VERSION ""

NS_ :

BS_:

BU_: BPCM ECM EVCU2 IDCM MCPA MCPB SGCP

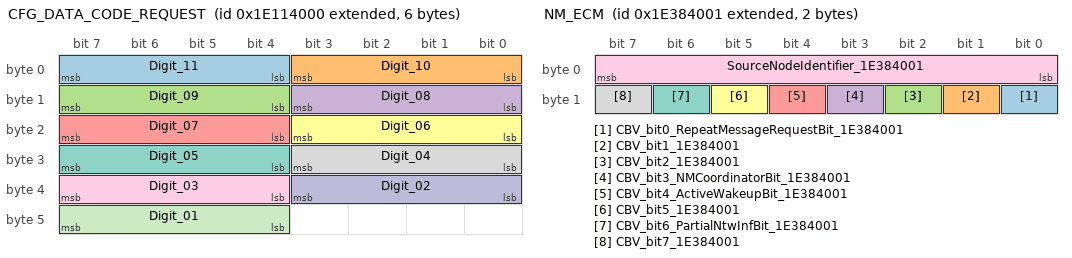
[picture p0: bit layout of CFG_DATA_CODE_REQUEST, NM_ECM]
BO_ 2651930624 CFG_DATA_CODE_REQUEST: 6 EVCU2
 SG_ Digit_11 : 7|4@0+ (1,0) [0|15] "" MCPB,MCPA
 SG_ Digit_10 : 3|4@0+ (1,0) [0|15] "" MCPB,MCPA
 SG_ Digit_09 : 15|4@0+ (1,0) [0|15] "" MCPB,MCPA
 SG_ Digit_08 : 11|4@0+ (1,0) [0|15] "" MCPB,MCPA
 SG_ Digit_07 : 23|4@0+ (1,0) [0|15] "" MCPB,MCPA
 SG_ Digit_06 : 19|4@0+ (1,0) [0|15] "" MCPB,MCPA
 SG_ Digit_05 : 31|4@0+ (1,0) [0|15] "" MCPB,MCPA
 SG_ Digit_04 : 27|4@0+ (1,0) [0|15] "" MCPB,MCPA
 SG_ Digit_03 : 39|4@0+ (1,0) [0|15] "" MCPB,MCPA
 SG_ Digit_02 : 35|4@0+ (1,0) [0|15] "" MCPB,MCPA
 SG_ Digit_01 : 47|4@0+ (1,0) [0|15] "" MCPB,MCPA

BO_ 2564554481 DIAGNOSTIC_REQUEST_FUNCTIONAL: 8 EVCU2
 SG_ N_PDU_18DBFEF1 : 7|64@0+ (1,0) [0|0] "" SGCP,MCPB,MCPA

BO_ 2564502513 DIAGNOSTIC_REQUEST_FUNC_OBD: 8 EVCU2
 SG_ N_PDU_18DB33F1 : 7|64@0+ (1,0) [0|0] "" MCPB,MCPA

BO_ 1053 VIN: 32 EVCU2
 SG_ VIN_MSG : 75|2@0+ (1,0) [0|3] "" SGCP,MCPB,MCPA,IDCM,BPCM
 SG_ VIN_DATA : 87|56@0+ (1,0) [0|72057594037927900] "" SGCP,MCPB,MCPA,IDCM,BPCM

BO_ 520 TRANSM_FD_2: 32 EVCU2
 SG_ GearEngagedForDisplay : 15|5@0+ (1,0) [0|30] "-"  SGCP,MCPB,MCPA

BO_ 156 TELEMATIC_FD_1: 32 EVCU2
 SG_ GPS_UTC_Second : 151|16@0+ (0.01,0) [0|59.99] "s"  MCPB,MCPA,IDCM,BPCM
 SG_ GPS_UTC_Minute : 47|8@0+ (1,0) [0|59] "min"  MCPB,MCPA,IDCM,BPCM
 SG_ GPS_UTC_Hour : 55|8@0+ (1,0) [0|23] "h"  MCPB,MCPA,IDCM,BPCM
 SG_ GPS_Date_Year : 167|16@0+ (1,0) [0|65534] "Years"  MCPB,MCPA,IDCM,BPCM
 SG_ GPS_Date_Month : 71|8@0+ (1,0) [1|12] "Months"  MCPB,MCPA,IDCM,BPCM
 SG_ GPS_Date_Day : 63|8@0+ (1,0) [1|31] "Days"  MCPB,MCPA,IDCM,BPCM

BO_ 1058 OBD_CONTENT_FRAME: 32 ECM
 SG_ MessageCounter_OBDCONTENTFRAME : 179|4@0+ (1,0) [0|15] "-"  EVCU2
 SG_ CRC_OBDCONTENTFRAME : 191|8@0+ (1,0) [0|255] "-"  EVCU2

BO_ 1829 IPC_FD_1: 32 EVCU2
 SG_ TotalOdometer : 75|20@0+ (1,0) [0|1048575] "km"  SGCP,MCPB,MCPA,IDCM,BPCM

BO_ 1626 IMPACT_INFO: 32 EVCU2
 SG_ IMPACTConfirm : 81|1@0+ (1,0) [0|1] "-"  MCPB,MCPA,IDCM,BPCM
 SG_ IMPACTCommand : 80|1@0+ (1,0) [0|1] "-"  MCPB,MCPA,IDCM,BPCM

BO_ 518 ENGINE_FD_5: 32 ECM
 SG_ RPMOverRev_W : 115|1@0+ (1,0) [0|1] "-"  EVCU2
 SG_ MessageCounter_ENGINE5 : 179|4@0+ (1,0) [0|15] "-"  EVCU2
 SG_ CRC_ENGINE5 : 191|8@0+ (1,0) [0|255] "-"  EVCU2

BO_ 1054 ENGINE_FD_1: 32 ECM
 SG_ ThermalManagementActive_W : 1|1@0+ (1,0) [0|1] "-"  EVCU2
 SG_ MessageCounter_ENGINE1 : 179|4@0+ (1,0) [0|15] "-"  EVCU2
 SG_ CRC_ENGINE1 : 191|8@0+ (1,0) [0|255] "-"  EVCU2

BO_ 2564554482 DIAGNOSTIC_REQUEST_FD_FUNCTIONAL: 64 EVCU2
 SG_ N_PDU_18DBFEF2 : 7|64@0+ (1,0) [0|0] "" SGCP,MCPB,MCPA

BO_ 1155 BRAKE_FD_5: 32 EVCU2
 SG_ ESCFailSts : 83|1@0+ (1,0) [0|1] "-"  MCPB
 SG_ ABSFailSts : 87|1@0+ (1,0) [0|1] "-"  MCPB

BO_ 609 BRAKE_FD_4: 32 EVCU2
 SG_ EPBSts : 115|4@0+ (1,0) [0|14] "-"  SGCP,MCPB,MCPA

BO_ 1066 BCM_FD_9: 32 EVCU2
 SG_ ExternalTemperature : 0|9@0+ (0.5,-85) [-85|170] "°C"  SGCP,MCPB,MCPA,IDCM,BPCM

BO_ 1827 BCM_FD_7: 32 EVCU2
 SG_ IgnitionOnCounter : 95|16@0+ (1,0) [0|65535] "-"  SGCP,MCPB,MCPA

BO_ 256 BCM_FD_2: 32 EVCU2
 SG_ OperationalModeSts : 75|4@0+ (1,0) [0|15] "" MCPB,MCPA,IDCM,BPCM

BO_ 1153 BCM_FD_10: 32 EVCU2
 SG_ ExternalTemperatureC : 80|9@0+ (0.5,-85) [-85|170] "°C"  SGCP,MCPB,MCPA
 SG_ CmdIgnSts : 138|3@0+ (1,0) [0|7] "" SGCP,MCPB,MCPA,IDCM,BPCM
 SG_ MessageCounter_BCM10 : 179|4@0+ (1,0) [0|15] "-"  MCPB
 SG_ CRC_BCM10 : 191|8@0+ (1,0) [0|255] "-"  MCPB

BO_ 753 LV_CHARGER1: 32 IDCM
 SG_ IDCM_Wakeup_HCP : 23|1@0+ (1,0) [0|1] "-"  EVCU2

BO_ 1032 HYBRID_THERMAL_COMMAND: 32 EVCU2
 SG_ MessageCounter_HYBRID_THERMAL_C : 179|4@0+ (1,0) [0|15] "-"  SGCP,MCPB,MCPA,ECM
 SG_ CRC_HYBRID_THERMAL_COMMAND : 191|8@0+ (1,0) [0|255] "-"  SGCP,MCPB,MCPA,ECM
 SG_ SGCP_OIL_TEMP : 175|8@0+ (1,-50) [-50|205] "°C"  SGCP
 SG_ SGCP_OIL_FlwRate : 135|8@0+ (0.1,0) [0|25.4] "LPM"  SGCP
 SG_ EOPB_OIL_TEMP : 151|8@0+ (1,-50) [-50|205] "°C"  MCPB
 SG_ EOPB_OIL_FlwRate : 167|8@0+ (0.1,0) [0|25.4] "LPM"  MCPB
 SG_ EOPA_OIL_TEMP : 143|8@0+ (1,-50) [-50|205] "°C"  MCPA
 SG_ EOPA_OIL_FlwRate : 159|8@0+ (0.1,0) [0|25.4] "LPM"  MCPA

BO_ 267 HYBRID_SYSTEM_EPT1: 32 EVCU2
 SG_ WU_Timer_Value : 23|16@0+ (1,0) [0|65535] "min"  MCPB,MCPA,IDCM,BPCM
 SG_ PerWakeUp_Diag : 33|10@0+ (1,0) [0|1023] "-"  MCPB,MCPA,IDCM,BPCM

BO_ 1033 HYBRID_POWERTRAIN5: 32 EVCU2
 SG_ IdleCLoopTrq : 33|10@0+ (0.32,-163.52) [-163.52|163.52] "Nm"  ECM
 SG_ HEV_HybPwrtrnRdcdPerfCmnd : 22|1@0+ (1,0) [0|0] "-"  ECM
 SG_ HCPMaxEngRPM : 63|8@0+ (32,0) [0|8128] "rpm"  ECM
 SG_ CRC_HYBRID_POWERTRAIN5 : 191|8@0+ (1,0) [0|255] "-"  ECM
 SG_ MessageCounter_HYBRID_POWERTRAI_409 : 179|4@0+ (1,0) [0|15] "-"  ECM
 SG_ HCP_HoodAjar : 35|2@0+ (1,0) [0|2] "" ECM

BO_ 1034 HVBATTERY_THERMAL: 48 BPCM
 SG_ HVBatSleepTime : 7|8@0+ (0.2,0) [0|48] "Days"  EVCU2

BO_ 1328 ENGINE_HYBD_FD_4: 32 ECM
 SG_ EngTorqCapbltyMinTorq : 51|12@0+ (0.32,-300.16) [-300.16|1008] "Nm"  EVCU2
 SG_ EngTorqCapbltyMaxTorq : 19|12@0+ (0.32,-300.16) [-300.16|1008] "Nm"  EVCU2
 SG_ EngTorqCapbltyMaxOffTorq : 3|12@0+ (0.32,-300.16) [-300.16|1008] "Nm"  EVCU2
 SG_ EngTorqCapbltyRefEngSpd : 71|8@0+ (32,0) [0|8160] "rpm"  EVCU2
 SG_ EngTorqCapbltyMinRunTorq : 35|12@0+ (0.32,-300.16) [-300.16|1008] "Nm"  EVCU2
 SG_ EngTorqCapbltyFrmCntr : 7|4@0+ (1,0) [0|15] "-"  EVCU2
 SG_ EngTorqCapbltyEngOpMd : 21|1@0+ (1,0) [0|0] "-"  EVCU2
 SG_ EngTorqACCCapability : 79|8@0+ (0.32,0) [0|81.28] "Nm"  EVCU2
 SG_ MessageCounter_ENGINE_HYBD_FD_4 : 179|4@0+ (1,0) [0|15] "-"  EVCU2
 SG_ CRC_ENGINE_HYBD_FD_4 : 191|8@0+ (1,0) [0|255] "-"  EVCU2

BO_ 1035 ENGINE_HYBD_FD_3: 32 ECM
 SG_ MaxEngSpdCap : 52|13@0+ (1,0) [0|8160] "rpm"  EVCU2
 SG_ MinEngSpdCap : 68|13@0+ (1,0) [0|8160] "rpm"  EVCU2
 SG_ EngSpd : 7|16@0+ (0.125,0) [0|8160] "rpm"  EVCU2
 SG_ MessageCounter_ENGINE_HYBD_FD_3 : 179|4@0+ (1,0) [0|15] "-"  EVCU2
 SG_ CRC_ENGINE_HYBD_FD_3 : 191|8@0+ (1,0) [0|255] "-"  EVCU2

BO_ 750 BCM_FD_3: 32 EVCU2
 SG_ Battery_Volt_1 : 56|9@0+ (0.025,5) [5|17.75] "Volt"  SGCP,MCPB,MCPA

BO_ 2654486529 NM_ECM: 2 ECM
 SG_ CBV_bit0_RepeatMessageRequestBit_1E384001 : 8|1@0+ (1,0) [0|1] "" SGCP,EVCU2,MCPB,MCPA,IDCM,BPCM
 SG_ CBV_bit1_1E384001 : 9|1@0+ (1,0) [0|1] "" SGCP,EVCU2,MCPB,MCPA,IDCM,BPCM
 SG_ CBV_bit2_1E384001 : 10|1@0+ (1,0) [0|1] "" SGCP,EVCU2,MCPB,MCPA,IDCM,BPCM
 SG_ CBV_bit3_NMCoordinatorBit_1E384001 : 11|1@0+ (1,0) [0|1] "" SGCP,EVCU2,MCPB,MCPA,IDCM,BPCM
 SG_ CBV_bit4_ActiveWakeupBit_1E384001 : 12|1@0+ (1,0) [0|1] "" SGCP,EVCU2,MCPB,MCPA,IDCM,BPCM
 SG_ CBV_bit5_1E384001 : 13|1@0+ (1,0) [0|1] "" SGCP,EVCU2,MCPB,MCPA,IDCM,BPCM
 SG_ CBV_bit6_PartialNtwInfBit_1E384001 : 14|1@0+ (1,0) [0|1] "" SGCP,EVCU2,MCPB,MCPA,IDCM,BPCM
 SG_ CBV_bit7_1E384001 : 15|1@0+ (1,0) [0|1] "" SGCP,EVCU2,MCPB,MCPA,IDCM,BPCM
 SG_ SourceNodeIdentifier_1E384001 : 7|8@0+ (1,0) [0|255] "-"  SGCP,EVCU2,MCPB,MCPA,IDCM,BPCM

BO_ 269 HYBRID_POWERTRAIN2: 64 EVCU2
 SG_ CRC_HYBRID_POWERTRAIN2 : 447|8@0+ (1,0) [0|255] "-"  ECM
 SG_ MessageCounter_HYBRID_POWERTRAI_10D : 435|4@0+ (1,0) [0|15] "-"  ECM

BO_ 276 HYBRID_POWERTRAIN1: 64 EVCU2
 SG_ Hybrid_Remedial_Stop : 290|1@0+ (1,0) [0|0] "-"  ECM
 SG_ HybCrnkAbrted : 282|1@0+ (1,0) [0|0] "-"  ECM
 SG_ CRC_HYBRID_POWERTRAIN1 : 447|8@0+ (1,0) [0|255] "-"  ECM
 SG_ PropulsionSystemActive : 408|1@0+ (1,0) [0|1] "-"  BPCM,ECM
 SG_ DriveReady : 423|1@0+ (1,0) [0|1] "-"  Vector__XXX
 SG_ MessageCounter_HYBRID_POWERTRAI_114 : 435|4@0+ (1,0) [0|15] "-"  ECM

BO_ 271 ENGINE_HYBD_FD_1: 64 ECM
 SG_ MessageCounter_ENGINE_HYBD_FD_1 : 435|4@0+ (1,0) [0|15] "-"  EVCU2
 SG_ CRC_ENGINE_HYBD_FD_1 : 447|8@0+ (1,0) [0|255] "-"  EVCU2
 SG_ RedSpkAuthorityAvbl : 308|1@0+ (1,0) [0|1] "" EVCU2
 SG_ EngMinSparkNomCurrAirTorqCap : 82|11@0+ (1,-500) [-500|1547] "Nm"  EVCU2

BO_ 262 ENGINE_FD_2: 64 ECM
 SG_ PowertrainPrplsnActv : 181|1@0+ (1,0) [0|1] "" SGCP,MCPB,MCPA
 SG_ MessageCounter_ENGINE2 : 435|4@0+ (1,0) [0|15] "-"  EVCU2
 SG_ EngineSpeedFailSts_W : 168|1@0+ (1,0) [0|1] "-"  SGCP,MCPB,MCPA
 SG_ EngineSpeed_W : 21|14@0+ (1,0) [0|16382] "1/min"  SGCP,MCPB,MCPA
 SG_ CRC_ENGINE2 : 447|8@0+ (1,0) [0|255] "-"  EVCU2

BO_ 258 BRAKE_FD_2: 64 EVCU2
 SG_ VehicleSpeedVSOSig : 4|13@0+ (0.0625,0) [0|511.875] "Km/h"  SGCP,MCPB,MCPA,BPCM
 SG_ MessageCounter_BRAKE2 : 435|4@0+ (1,0) [0|15] "-"  MCPB,MCPA
 SG_ LongAccelerationFailSts_BSM : 69|1@0+ (1,0) [0|1] "-"  MCPB,MCPA
 SG_ LongAcceleration_BSM : 35|12@0+ (0.02,-40.96) [-40.96|40.92] "m/s^2"  MCPB,MCPA
 SG_ LatAccelerationFailSts_BSM : 68|1@0+ (1,0) [0|1] "-"  MCPB,MCPA
 SG_ LatAcceleration_BSM : 19|12@0+ (0.02,-40.96) [-40.96|40.92] "m/s^2"  MCPB,MCPA
 SG_ ESCActive : 84|1@0+ (1,0) [0|1] "-"  MCPB,MCPA
 SG_ CRC_BRAKE2 : 447|8@0+ (1,0) [0|255] "-"  MCPB,MCPA
 SG_ ABSActive : 83|1@0+ (1,0) [0|1] "-"  MCPB,MCPA

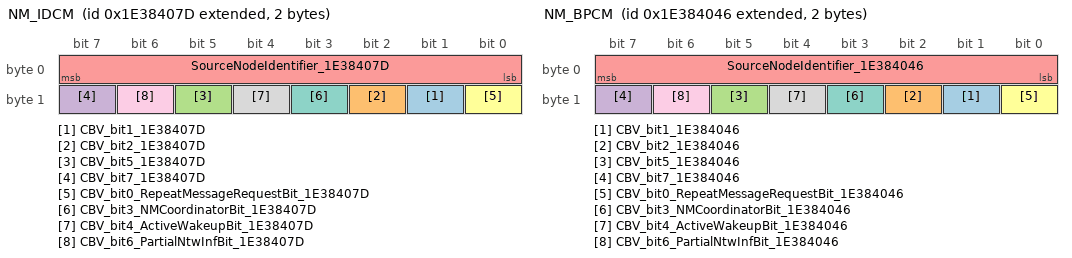
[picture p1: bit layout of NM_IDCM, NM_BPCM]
BO_ 2654486653 NM_IDCM: 2 IDCM
 SG_ CBV_bit1_1E38407D : 9|1@0+ (1,0) [0|1] "" SGCP,EVCU2,MCPB,MCPA,BPCM,ECM
 SG_ CBV_bit2_1E38407D : 10|1@0+ (1,0) [0|1] "" SGCP,EVCU2,MCPB,MCPA,BPCM,ECM
 SG_ CBV_bit5_1E38407D : 13|1@0+ (1,0) [0|1] "" SGCP,EVCU2,MCPB,MCPA,BPCM,ECM
 SG_ CBV_bit7_1E38407D : 15|1@0+ (1,0) [0|1] "" SGCP,EVCU2,MCPB,MCPA,BPCM,ECM
 SG_ SourceNodeIdentifier_1E38407D : 7|8@0+ (1,0) [0|255] "-"  SGCP,EVCU2,MCPB,MCPA,BPCM,ECM
 SG_ CBV_bit0_RepeatMessageRequestBit_1E38407D : 8|1@0+ (1,0) [0|1] "" SGCP,EVCU2,MCPB,MCPA,BPCM,ECM
 SG_ CBV_bit3_NMCoordinatorBit_1E38407D : 11|1@0+ (1,0) [0|1] "" SGCP,EVCU2,MCPB,MCPA,BPCM,ECM
 SG_ CBV_bit4_ActiveWakeupBit_1E38407D : 12|1@0+ (1,0) [0|1] "" SGCP,EVCU2,MCPB,MCPA,BPCM,ECM
 SG_ CBV_bit6_PartialNtwInfBit_1E38407D : 14|1@0+ (1,0) [0|1] "" SGCP,EVCU2,MCPB,MCPA,BPCM,ECM

BO_ 2654486598 NM_BPCM: 2 BPCM
 SG_ CBV_bit1_1E384046 : 9|1@0+ (1,0) [0|1] "" SGCP,EVCU2,MCPB,MCPA,IDCM,ECM
 SG_ CBV_bit2_1E384046 : 10|1@0+ (1,0) [0|1] "" SGCP,EVCU2,MCPB,MCPA,IDCM,ECM
 SG_ CBV_bit5_1E384046 : 13|1@0+ (1,0) [0|1] "" SGCP,EVCU2,MCPB,MCPA,IDCM,ECM
 SG_ CBV_bit7_1E384046 : 15|1@0+ (1,0) [0|1] "" SGCP,EVCU2,MCPB,MCPA,IDCM,ECM
 SG_ SourceNodeIdentifier_1E384046 : 7|8@0+ (1,0) [0|255] "-"  SGCP,EVCU2,MCPB,MCPA,IDCM,ECM
 SG_ CBV_bit0_RepeatMessageRequestBit_1E384046 : 8|1@0+ (1,0) [0|1] "" SGCP,EVCU2,MCPB,MCPA,IDCM,ECM
 SG_ CBV_bit3_NMCoordinatorBit_1E384046 : 11|1@0+ (1,0) [0|1] "" SGCP,EVCU2,MCPB,MCPA,IDCM,ECM
 SG_ CBV_bit4_ActiveWakeupBit_1E384046 : 12|1@0+ (1,0) [0|1] "" SGCP,EVCU2,MCPB,MCPA,IDCM,ECM
 SG_ CBV_bit6_PartialNtwInfBit_1E384046 : 14|1@0+ (1,0) [0|1] "" SGCP,EVCU2,MCPB,MCPA,IDCM,ECM

BO_ 1579 HYBRID_CHARGING_STATUS: 32 EVCU2
 SG_ HVBatteryVoltage_MinCal : 32|9@0+ (1,0) [0|510] "V"  IDCM,BPCM
 SG_ HVBatteryVoltage_MaxCal : 16|9@0+ (1,0) [0|510] "V"  IDCM,BPCM
 SG_ HVBatteryCurrent_MaxCal : 63|8@0+ (0.25,-32) [-32|31.5] "Amp"  IDCM,BPCM
 SG_ ChargeSystemFaultReason : 55|8@0+ (1,0) [0|254] "-"  IDCM
 SG_ ACCurrent_MaxCal : 0|9@0+ (0.25,-31.5) [-31.5|50] "Amp"  IDCM,BPCM
 SG_ ChargingLevel : 4|4@0+ (1,0) [0|14] "-"  IDCM
 SG_ OBCM_PLUG_STS : 23|2@0+ (1,0) [0|3] "" IDCM
 SG_ ChargeSystemSts : 7|3@0+ (1,0) [0|6] "-"  IDCM,BPCM
 SG_ ChargeSystemFault : 17|1@0+ (1,0) [0|1] "-"  IDCM
 SG_ CRC_HYBRID_CHARGING_STATUS : 191|8@0+ (1,0) [0|255] "-"  IDCM
 SG_ MessageCounter_HYBRID_CHARGING__62B : 179|4@0+ (1,0) [0|15] "-"  IDCM

BO_ 478 HYBRID_CHARGING_COMMAND: 32 EVCU2
 SG_ CRC_HYBRID_CHARGING_COMMAND : 191|8@0+ (1,0) [0|255] "-"  IDCM
 SG_ VoltageRequest : 4|13@0+ (0.1,0) [0|819.1] "Volts"  IDCM
 SG_ OBC_ControlMethod : 38|2@0+ (1,0) [0|2] "-"  IDCM
 SG_ J1772_CloseS2 : 51|1@0+ (1,0) [0|1] "-"  IDCM
 SG_ HVBatCoolantLevelLow : 50|2@0+ (1,0) [0|2] "-"  BPCM
 SG_ OBC_OperativeModeReq : 87|4@0+ (1,0) [0|14] "-"  IDCM
 SG_ HV_Volt_Min_Thrsh : 138|11@0+ (1,0) [0|2047] "V"  IDCM
 SG_ HV_Volt_Max_Thrsh : 133|11@0+ (1,0) [0|2047] "V"  IDCM
 SG_ DC_Curr_Max_Thrsh : 127|10@0+ (1,-511) [-511|512] "A"  IDCM
 SG_ ChargeEnable : 171|2@0+ (1,0) [0|2] "-"  IDCM
 SG_ AC_Curr_Min_Thrsh : 165|10@0+ (1,-511) [-511|512] "A"  IDCM
 SG_ AC_Curr_Max_Thrsh : 159|10@0+ (1,-511) [-511|512] "A"  IDCM
 SG_ CurrentRequest : 81|10@0+ (0.1,-32) [-32|70.3] "A"  IDCM
 SG_ VDCM_StsWldgReq : 83|1@0+ (1,0) [0|1] "-"  IDCM
 SG_ VDCM_SessnStopReq : 82|1@0+ (1,0) [0|1] "-"  IDCM
 SG_ VDCM_StsSWWldgReq : 55|2@0+ (1,0) [0|3] "-"  Vector__XXX
 SG_ MessageCounter_HYBRID_CHARGING__1DE : 179|4@0+ (1,0) [0|15] "-"  IDCM

BO_ 1578 HV_CHARGER2: 32 IDCM
 SG_ OBC_IdleTimeSec : 71|16@0+ (3,0) [0|196602] "sec"  EVCU2
 SG_ OBC_IdleTimeMin : 87|16@0+ (1,0) [0|65534] "min"  EVCU2
 SG_ OBC_ChargeTimeSec : 39|16@0+ (3,0) [0|196602] "sec"  EVCU2
 SG_ OBC_ChargeTimeMin : 55|16@0+ (1,0) [0|65534] "min"  EVCU2
 SG_ Charging_WHr : 23|16@0+ (1,0) [0|65534] "WHr"  EVCU2
 SG_ OnboardChargerReady : 116|2@0+ (1,0) [0|2] "-"  EVCU2
 SG_ OnboardChargerMode : 114|4@0+ (1,0) [0|15] "-"  EVCU2
 SG_ OBC_WakeReason : 107|4@0+ (1,0) [0|7] "-"  EVCU2
 SG_ OBC_GenericFailSts : 125|1@0+ (1,0) [0|1] "-"  EVCU2
 SG_ OBC_FaultReason : 102|7@0+ (1,0) [0|126] "-"  EVCU2
 SG_ OBC_EVServiceLampOn : 124|1@0+ (1,0) [0|1] "-"  EVCU2
 SG_ OBC_EVServiceLampFlash : 123|1@0+ (1,0) [0|1] "-"  EVCU2
 SG_ OBC_CurrentFailureSts : 121|1@0+ (1,0) [0|1] "-"  EVCU2
 SG_ OBC_ChargingFaultSts : 110|3@0+ (1,0) [0|7] "-"  EVCU2
 SG_ OBC_ChargeFailure : 120|1@0+ (1,0) [0|1] "-"  EVCU2
 SG_ OBC_CaptureEnvironmentData : 119|1@0+ (1,0) [0|1] "-"  EVCU2
 SG_ ACplug_PwrMax : 7|16@0+ (1,-32767) [-32767|32767] "W"  EVCU2
 SG_ OBC_Prox : 159|8@0+ (0.05,0) [0|12.75] "V"  EVCU2
 SG_ OBC_Pilot : 151|8@0+ (0.05,0) [0|12.75] "V"  EVCU2
 SG_ OBCM_PrechargeSts : 167|2@0+ (1,0) [0|3] "-"  EVCU2
 SG_ ChrgFailSts : 165|3@0+ (1,0) [0|7] "" EVCU2

BO_ 1372 DUALCHARGER_THERMAL: 32 IDCM
 SG_ OBC_Temp4 : 63|8@0+ (1,-40) [-40|214] "°C"  EVCU2
 SG_ OBC_Temp3 : 55|8@0+ (1,-40) [-40|214] "°C"  EVCU2
 SG_ OBC_Temp2 : 47|8@0+ (1,-40) [-40|214] "°C"  EVCU2
 SG_ OBC_Temp1 : 39|8@0+ (1,-40) [-40|214] "°C"  EVCU2

BO_ 1460 FOTA_MASTER: 32 EVCU2
 SG_ FOTA_Status : 7|4@0+ (1,0) [0|15] "" SGCP,MCPB,MCPA

BO_ 502 VDCM_OBCM: 48 EVCU2
 SG_ VDCM_OBCDischCurrentLim : 265|14@0+ (0.1,-815) [-815|823.3] "A"  IDCM
 SG_ VDCM_BattBulkSOC : 283|10@0+ (0.1,0) [0|100] "%"  IDCM
 SG_ HVCMS_ServiceScope : 87|16@0+ (1,0) [0|65534] "" IDCM
 SG_ HVCMS_ReadyToChargeState : 271|1@0+ (1,0) [0|1] "" IDCM
 SG_ HVCMS_Protocol_Entry3 : 39|16@0+ (1,0) [0|65534] "" IDCM
 SG_ HVCMS_Protocol_Entry2 : 23|16@0+ (1,0) [0|65534] "" IDCM
 SG_ HVCMS_Protocol_Entry1 : 7|16@0+ (1,0) [0|65534] "" IDCM
 SG_ HVCMS_EVTargetVoltage : 247|14@0+ (0.1,0) [0|1638.2] "V"  IDCM
 SG_ HVCMS_EVTargetCurrent : 249|10@0+ (1,-500) [-500|522] "" IDCM
 SG_ HVCMS_EVRESSConditioning : 171|1@0+ (1,0) [0|1] "" IDCM
 SG_ HVCMS_EVRESS_SOC : 159|12@0+ (0.02442,0) [0|99.97548] "%"  IDCM
 SG_ HVCMS_EVReady : 170|1@0+ (1,0) [0|1] "" IDCM
 SG_ HVCMS_EVMax_V_Limit : 215|14@0+ (0.1,0) [0|1638.2] "V"  IDCM
 SG_ HVCMS_EVMax_P_Limit : 191|24@0+ (0.1,0) [0|1677721.4] "W"  IDCM
 SG_ HVCMS_EVMax_I_Limit : 169|10@0+ (1,-500) [-500|522] "A"  IDCM
 SG_ HVCMS_EVEnergyCapacity : 217|17@0+ (1,0) [0|131070] "Wh"  IDCM
 SG_ HVCMS_ChargingComplete : 269|1@0+ (1,0) [0|1] "" IDCM
 SG_ HVCMS_BulkChargingComplete : 270|1@0+ (1,0) [0|1] "" IDCM
 SG_ VDCM_TypeCNegotiationSts : 378|3@0+ (1,0) [0|7] "" IDCM
 SG_ VDCM_GenChallenge : 362|16@0+ (1,0) [0|65535] "" IDCM
 SG_ VDCM_ContractAuthenticationID : 346|16@0+ (1,0) [0|65535] "" IDCM
 SG_ HVCMS_EVEnergyRequest : 331|17@0+ (1,0) [0|131071] "Wh"  IDCM
 SG_ OBCM_OutVoltageSyncTgt : 289|10@0+ (1,0) [0|1022] "V"  IDCM
 SG_ HVCMS_ServiceCategory : 103|4@0+ (1,0) [0|15] "" IDCM
 SG_ HVCMS_SelectedServiceId : 135|16@0+ (1,0) [0|65535] "" IDCM
 SG_ HVCMS_SelectedPaymentOptn : 119|2@0+ (1,0) [0|3] "" IDCM
 SG_ HVCMS_SelectedEnergyTransferType : 151|4@0+ (1,0) [0|15] "" IDCM
 SG_ HVCMS_RemaningTimeToFullSOC : 71|16@0+ (1,0) [0|65535] "sec"  IDCM
 SG_ HVCMS_RemaningTimeToBulkSOC : 55|16@0+ (1,0) [0|65534] "" IDCM
 SG_ HVCMS_EVErrorCode : 163|4@0+ (1,0) [0|15] "" IDCM

BO_ 242 PIM_F: 64 MCPA
 SG_ MC_PF1 : 499|4@0+ (1,0) [0|15] "-"  EVCU2,BPCM
 SG_ INVFInterlockSts : 229|2@0+ (1,0) [0|3] "-"  EVCU2
 SG_ InvF_DC_Voltage : 271|10@0+ (1,0) [0|1022] "V"  EVCU2
 SG_ CRC_PF1 : 511|8@0+ (1,0) [0|255] "-"  EVCU2,BPCM
 SG_ InvF_DerateReason : 170|4@0+ (1,0) [0|15] "-"  EVCU2
 SG_ MCPA_Torque_Achieved : 44|13@0+ (0.125,-512) [-512|511.875] "Nm"  EVCU2
 SG_ MCPA_TorqAchieved_AEMD_V : 196|1@0+ (1,0) [0|1] "" EVCU2
 SG_ MCPA_TorqAchieved_AEMD : 299|13@0+ (0.125,-512) [-512|511.875] "Nm"  EVCU2
 SG_ MCPA_Spd_Lim : 356|16@0+ (1,-32767) [-32767|32678] "rpm"  EVCU2
 SG_ MCPA_RPM_V : 234|1@0+ (1,0) [0|1] "" EVCU2
 SG_ MCPA_RPM : 28|16@0+ (1,-32768) [-32768|32767] "rpm"  EVCU2
 SG_ MCPA_MtrMinCpbltyTrq : 321|13@0+ (0.125,-512) [-512|511.875] "Nm"  EVCU2
 SG_ MCPA_MtrMaxCpbltyTrq : 318|13@0+ (0.125,-512) [-512|511.875] "Nm"  EVCU2
 SG_ MCPA_MtrIndex : 398|5@0+ (1,0) [0|31] "" EVCU2
 SG_ MCPA_MinTorq : 280|13@0+ (0.125,-512) [-512|511.875] "Nm"  EVCU2
 SG_ MCPA_MaxTorq : 277|13@0+ (0.125,-512) [-512|511.875] "Nm"  EVCU2
 SG_ MCPA_Invrtr_State : 186|4@0+ (1,0) [0|15] "" EVCU2
 SG_ MCPA_HV_CnctrOpn_Req : 195|1@0+ (1,0) [0|1] "" EVCU2
 SG_ MCPA_Dschrge_Status : 393|2@0+ (1,0) [0|3] "" EVCU2
 SG_ MCPA_DeratingFactor : 388|6@0+ (0.02,0) [0|1.26] "" EVCU2
 SG_ MCPA_DC_Volt_V : 197|1@0+ (1,0) [0|1] "" EVCU2
 SG_ MCPA_DC_Current_V : 198|1@0+ (1,0) [0|1] "" EVCU2
 SG_ MCPA_DC_Current : 63|15@0+ (0.1,-1638.4) [-1638.4|1638.3] "A"  EVCU2,BPCM
 SG_ MCPA_CpbltySpdDivVolt : 340|16@0+ (1,0) [0|65535] "rpm"  EVCU2
 SG_ MCPA_AccelRawV : 193|1@0+ (1,0) [0|1] "" EVCU2
 SG_ MCPA_AccelRaw : 372|16@0+ (1,0) [0|65535] "" EVCU2
 SG_ MCPA_6SO_Status : 64|2@0+ (1,0) [0|3] "" EVCU2
 SG_ MCPA_3PS_Pos : 194|1@0+ (1,0) [0|1] "" EVCU2
 SG_ InvF_CoolantTemp : 407|11@0+ (0.1,-40) [-40|164.7] "°C"  EVCU2
 SG_ MCPA_Torque_Achieved_V : 129|1@0+ (1,0) [0|1] "" EVCU2
 SG_ MCPA_SPT_Stat : 78|2@0+ (1,0) [0|3] "" EVCU2

BO_ 498 OBCM_VDCM: 48 IDCM
 SG_ HVCMS_EVSEPresentVoltage : 250|14@0+ (0.1,0) [0|1638.3] "V"  EVCU2
 SG_ HVCMS_EVSEPeakCurrentRipple : 199|10@0+ (1,-500) [-500|523] "A"  EVCU2
 SG_ HVCMS_EVSEMinCurrentLimit : 157|10@0+ (1,-500) [-500|523] "A"  EVCU2
 SG_ HVCMS_EVSEMaxPowerLimit : 205|24@0+ (0.1,0) [0|1677721.5] "W"  EVCU2
 SG_ HVCMS_EVSEMaxCurrentLimit : 151|10@0+ (1,-500) [-500|523] "A"  EVCU2
 SG_ HVCMS_EVSECurrRegulationTol : 244|10@0+ (1,-500) [-500|523] "A"  EVCU2
 SG_ HVCMS_EnergyToBeDelivered : 229|17@0+ (1,0) [0|131071] "Wh"  EVCU2
 SG_ EVSE_IsolationSts : 143|3@0+ (1,0) [0|7] "" EVCU2
 SG_ EVSE_Accepted_Protocol : 39|16@0+ (1,0) [0|65535] "" EVCU2
 SG_ DC_TimeOut : 139|1@0+ (1,0) [0|1] "" EVCU2
 SG_ DC_Isolation_Disable_Cmd : 140|1@0+ (1,0) [0|1] "" EVCU2
 SG_ OBCM_PLCTypeSts : 337|3@0+ (1,0) [0|6] "" EVCU2
 SG_ HVCMS_EVSEVoltageLimitAchieved : 286|2@0+ (1,0) [0|3] "" EVCU2
 SG_ HVCMS_EVSEPowerLimitAchieved : 272|2@0+ (1,0) [0|3] "" EVCU2
 SG_ HVCMS_EVSEMinimumVoltageLimit : 300|16@0+ (0.1,0) [0|6553.4] "V"  EVCU2
 SG_ HVCMS_EVSEMaximumVoltageLimit : 284|16@0+ (0.1,0) [0|6553.4] "V"  EVCU2
 SG_ HVCMS_EVSECurrentLimitAchieved : 274|2@0+ (1,0) [0|3] "" EVCU2
 SG_ HVCMS_EVSEPresentCurrent : 350|16@0+ (0.02,0) [0|1310.7] "A"  EVCU2
 SG_ EVSE_OfferedEnergyTransferType : 103|4@0+ (1,0) [0|15] "" EVCU2
 SG_ HVCMS_TxMessageStat : 7|5@0+ (1,0) [0|31] "" EVCU2
 SG_ HVCMS_ResponseCode : 23|5@0+ (1,0) [0|31] "" EVCU2
 SG_ HVCMS_EVSEProcessing : 119|1@0+ (1,0) [0|1] "" EVCU2
 SG_ EVSE_FreeService : 71|1@0+ (1,0) [0|1] "" EVCU2
 SG_ TxMessageResponse : 70|5@0+ (1,0) [0|31] "" EVCU2
 SG_ HVCMS_EVSEStatusCode : 135|4@0+ (1,0) [0|15] "" EVCU2
 SG_ EVSE_ServiceId : 55|16@0+ (1,0) [0|65535] "" EVCU2
 SG_ EVSE_OfferedService : 138|3@0+ (1,0) [0|7] "" EVCU2
 SG_ EVSE_OfferedPaymentOptn : 87|2@0+ (1,0) [0|3] "" EVCU2
 SG_ MC_OBCM_VDCM : 371|4@0+ (1,0) [0|15] "" EVCU2
 SG_ EVSE_Supported_ISO1 : 64|1@0+ (1,0) [0|1] "" EVCU2
 SG_ EVSE_Supported_DIN : 65|1@0+ (1,0) [0|1] "-"  EVCU2
 SG_ CRC_OBCM_VDCM : 383|8@0+ (1,0) [0|255] "" EVCU2
 SG_ EVSE_Supported_SAE : 31|1@0+ (1,0) [0|1] "" EVCU2
 SG_ EVSE_Service2_Certificate : 16|1@0+ (1,0) [0|1] "-"  EVCU2
 SG_ EVSE_OfferedPaymentEIM : 18|1@0+ (1,0) [0|1] "-"  EVCU2
 SG_ EVSE_OfferedPaymentContract : 17|1@0+ (1,0) [0|1] "-"  EVCU2
 SG_ EVSE_Notification : 2|2@0+ (1,0) [0|3] "" EVCU2

CM_ "Project_WS25_ProjectStandard_FD-CAN5 [CS00155_FD]";
CM_ SG_ 1328 EngTorqCapbltyMinTorq "Engine torque capability: minimum torque (fuel off)";
CM_ SG_ 1328 EngTorqCapbltyMaxTorq "Engine torque capability: maximum torque";
CM_ SG_ 1035 MaxEngSpdCap "Maximum Engine Speed Capacity";
CM_ SG_ 2564502513 N_PDU_18DB33F1 "This signal is used for diagnostic purposes";
CM_ SG_ 1328 EngTorqCapbltyMaxOffTorq "Capability Max-off";
CM_ SG_ 1053 VIN_MSG "VIN Message Information";
CM_ SG_ 1829 TotalOdometer "Used to give information about the total odometer value in km.";
CM_ SG_ 1626 IMPACTConfirm "This signal is used to confirm that a crash happened";
CM_ SG_ 1626 IMPACTCommand "This signal is used to indicate that a crash happened";
CM_ SG_ 1155 ESCFailSts "0";
CM_ SG_ 1155 ABSFailSts "0";
CM_ SG_ 609 EPBSts "0";
CM_ SG_ 1153 ExternalTemperatureC "Used to indicate the external temperature value in °C";
CM_ SG_ 1153 CmdIgnSts "Used to give information about the key selector position";
CM_ SG_ 1033 IdleCLoopTrq "Electric motor PID torque to maintain idle speed.";
CM_ SG_ 1033 HEV_HybPwrtrnRdcdPerfCmnd "Driver torque request modifier due to system remedial acion";
CM_ SG_ 1033 HCPMaxEngRPM "Engine rev limit due to HCP/MGU limits";
CM_ SG_ 1328 EngTorqCapbltyRefEngSpd "Engine torque capability: reference engine speed";
CM_ SG_ 1328 EngTorqCapbltyMinRunTorq "Engine torque capability: minimum run torque (fuel on)";
CM_ SG_ 1328 EngTorqCapbltyFrmCntr "Engine Torque Capability: Frame Counter (4 bit)";
CM_ SG_ 1328 EngTorqCapbltyEngOpMd "Engine operating mode [0] = non-MDS, [1] = MDS";
CM_ SG_ 1328 EngTorqACCCapability "Eng Trq to be subtracted from the entire capability curve on the HCP side";
CM_ SG_ 1035 MinEngSpdCap "Minimum Engine Speed Capacity";
CM_ SG_ 1035 EngSpd "Engine speed";
CM_ SG_ 518 RPMOverRev_W "-";
CM_ SG_ 518 MessageCounter_ENGINE5 "This signal is a counter used for safety checks strategies. This counter is incremented of 1 (one) unit at each frame transmission.";
CM_ SG_ 518 CRC_ENGINE5 "CRC according to SAE J1850 standard at each frame transmission.";
CM_ SG_ 1054 ThermalManagementActive_W "-";
CM_ SG_ 1054 MessageCounter_ENGINE1 "This signal is a counter used for safety checks strategies. This counter is incremented of 1 (one) unit at each frame transmission.";
CM_ SG_ 1054 CRC_ENGINE1 "CRC according to SAE J1850 standard at each frame transmission.";
CM_ SG_ 750 Battery_Volt_1 "Battery Volt 1 signal";
CM_ SG_ 1153 MessageCounter_BCM10 "This signal is a counter used for safety checks strategies. This counter is incremented of 1 (one) unit at each frame transmission.";
CM_ SG_ 1153 CRC_BCM10 "CRC according to SAE J1850 standard at each frame transmission.";
CM_ SG_ 1058 MessageCounter_OBDCONTENTFRAME "This signal is a counter used for safety checks strategies. This counter is incremented of 1 (one) unit at each frame transmission.";
CM_ SG_ 1058 CRC_OBDCONTENTFRAME "CRC according to SAE J1850 standard at each frame transmission.";
CM_ SG_ 1033 CRC_HYBRID_POWERTRAIN5 "CRC according to SAE J1850 standard at each frame transmission.";
CM_ SG_ 269 CRC_HYBRID_POWERTRAIN2 "CRC according to SAE J1850 standard at each frame transmission.";
CM_ SG_ 276 Hybrid_Remedial_Stop "Engine Start Allowed.0 = ENG_ON_ALLOWED, 1 = ENG_ON_NOT_ALLOW";
CM_ SG_ 276 HybCrnkAbrted "Hybrid Crank Aborted";
CM_ SG_ 276 CRC_HYBRID_POWERTRAIN1 "CRC according to SAE J1850 standard at each frame transmission.";
CM_ SG_ 1328 MessageCounter_ENGINE_HYBD_FD_4 "This signal is a counter used for safety checks strategies. This counter is incremented of 1 (one) unit at each frame transmission.";
CM_ SG_ 1328 CRC_ENGINE_HYBD_FD_4 "CRC according to SAE J1850 standard at each frame transmission.";
CM_ SG_ 1035 MessageCounter_ENGINE_HYBD_FD_3 "This signal is a counter used for safety checks strategies. This counter is incremented of 1 (one) unit at each frame transmission.";
CM_ SG_ 1035 CRC_ENGINE_HYBD_FD_3 "CRC according to SAE J1850 standard at each frame transmission.";
CM_ SG_ 271 MessageCounter_ENGINE_HYBD_FD_1 "This signal is a counter used for safety checks strategies. This counter is incremented of 1 (one) unit at each frame transmission.";
CM_ SG_ 271 CRC_ENGINE_HYBD_FD_1 "CRC according to SAE J1850 standard at each frame transmission.";
CM_ SG_ 262 PowertrainPrplsnActv "Powertrain Propulsion Status.";
CM_ SG_ 262 MessageCounter_ENGINE2 "This signal is a counter used for safety checks strategies. This counter is incremented of 1 (one) unit at each frame transmission.";
CM_ SG_ 262 EngineSpeedFailSts_W "Used to indicate if a Fail is present for the engine speed";
CM_ SG_ 262 EngineSpeed_W "It gives information on C-CAN network about  engine speed";
CM_ SG_ 262 CRC_ENGINE2 "CRC according to SAE J1850 standard at each frame transmission.";
CM_ SG_ 258 VehicleSpeedVSOSig "It is the average vehicle speed calculated.";
CM_ SG_ 258 MessageCounter_BRAKE2 "This signal is a counter used for safety checks strategies. This counter is incremented of 1 (one) unit at each frame transmission.";
CM_ SG_ 258 LongAccelerationFailSts_BSM "This signal indicates the status of Longitudinal acceleration signal";
CM_ SG_ 258 LongAcceleration_BSM "This signal indicates the Longitudinal Acceleration Value";
CM_ SG_ 258 LatAccelerationFailSts_BSM "This signal indicates the status of Lateral Acceleration Signal";
CM_ SG_ 258 LatAcceleration_BSM "This signal indicates the Lateral Acceleration Value";
CM_ SG_ 258 ESCActive "This signal is set to Active when the brake intervention by ESC is active.";
CM_ SG_ 258 CRC_BRAKE2 "CRC according to SAE J1850 standard at each frame transmission.";
CM_ SG_ 258 ABSActive "This signal is set to Active when the ABS functionality is active.";
CM_ SG_ 1579 HVBatteryVoltage_MinCal "Minimum allowable HV battery voltage";
CM_ SG_ 1579 HVBatteryVoltage_MaxCal "Maximum allowable HV battery voltage";
CM_ SG_ 1579 HVBatteryCurrent_MaxCal "Maximum allowable HV battery current";
CM_ SG_ 1579 ChargeSystemFaultReason "Charge System Fault Reason";
CM_ SG_ 1579 ACCurrent_MaxCal "Maximum allowable AC current";
CM_ SG_ 478 CRC_HYBRID_CHARGING_COMMAND "CRC according to SAE J1850 standard at each frame transmission.";
CM_ SG_ 1034 HVBatSleepTime "Time since BPCM last went to sleep.";
CM_ SG_ 1578 OBC_IdleTimeSec "On board charger idle time";
CM_ SG_ 1578 OBC_IdleTimeMin "On board charger idle time - long";
CM_ SG_ 1578 OBC_ChargeTimeSec "On board charge time";
CM_ SG_ 1578 OBC_ChargeTimeMin "On board charge time - long";
CM_ SG_ 1578 Charging_WHr "Watt-hours of charge";
CM_ SG_ 1372 OBC_Temp4 "OBCM temperature sensor 3";
CM_ SG_ 1372 OBC_Temp3 "OBCM temperature sensor 4";
CM_ SG_ 1372 OBC_Temp2 "OBCM temperature sensor 2";
CM_ SG_ 1372 OBC_Temp1 "OBCM temperature sensor 1";
CM_ SG_ 520 GearEngagedForDisplay "Transmission Gear engaged signal for Display on cluster.";
CM_ SG_ 156 GPS_UTC_Second "GPS UTC second";
CM_ SG_ 156 GPS_UTC_Minute "GPS UTC minute";
CM_ SG_ 156 GPS_UTC_Hour "GPS UTC hour";
CM_ SG_ 156 GPS_Date_Year "GPS date year";
CM_ SG_ 156 GPS_Date_Month "GPS date month";
CM_ SG_ 156 GPS_Date_Day "GPS date day";
CM_ SG_ 276 PropulsionSystemActive "Propulsion system active, [1] = active";
CM_ SG_ 1460 FOTA_Status "FOTA_Status";
CM_ SG_ 478 VoltageRequest "High Voltage Battery Voltage";
CM_ SG_ 2564554481 N_PDU_18DBFEF1 "This signal is used for diagnostic purposes";
CM_ SG_ 2564554482 N_PDU_18DBFEF2 "This signal is used for diagnostic purposes";
CM_ SG_ 267 WU_Timer_Value "HCP wake-up timer value";
CM_ SG_ 267 PerWakeUp_Diag "Periodic wakeup diagnostics";
CM_ SG_ 1579 ChargingLevel "Charging level and type.";
CM_ SG_ 478 OBC_ControlMethod "Onboard charger commanded control method";
CM_ SG_ 478 J1772_CloseS2 "J 1772 Close command";
CM_ SG_ 478 HVBatCoolantLevelLow "Battery coolant level low";
CM_ SG_ 502 VDCM_OBCDischCurrentLim "This signal indicates the Limit of discharge current.";
CM_ SG_ 502 VDCM_BattBulkSOC "This signal indicates the SOC at which the battery is considered as full.";
CM_ SG_ 502 HVCMS_ServiceScope "This signal indicates the HVCMS Service Scope.";
CM_ SG_ 502 HVCMS_ReadyToChargeState "This signal indicates the HVCMS_ReadyToChargeState.";
CM_ SG_ 502 HVCMS_Protocol_Entry3 "HVCMS Protocol";
CM_ SG_ 502 HVCMS_Protocol_Entry2 "HVCMS Protocol";
CM_ SG_ 502 HVCMS_Protocol_Entry1 "HVCMS Protocol";
CM_ SG_ 502 HVCMS_EVTargetVoltage "This signal indicates the HVCMS EV Target Voltage.";
CM_ SG_ 502 HVCMS_EVTargetCurrent "This signal indicates the HVCMS_EVTargetCurrent.";
CM_ SG_ 502 HVCMS_EVRESSConditioning "This signal indicates the HVCMS EV RESS Conditioning.";
CM_ SG_ 502 HVCMS_EVRESS_SOC "This signal indicates the HVCMS EV RESS State Of Charge.";
CM_ SG_ 502 HVCMS_EVReady "This signal indicates the HVCMS EV Ready.";
CM_ SG_ 502 HVCMS_EVMax_V_Limit "This signal indicates the HVCMS EV Max Voltage Limit.";
CM_ SG_ 502 HVCMS_EVMax_P_Limit "This signal indicates the HVCMS EV Max Power Limit.";
CM_ SG_ 502 HVCMS_EVMax_I_Limit "This signal indicates the HVCMS EV Max Current Limit.";
CM_ SG_ 502 HVCMS_EVEnergyCapacity "This signal indicates the HVCMS EV Energy Capacity.";
CM_ SG_ 502 HVCMS_ChargingComplete "This signal indicates the HVCMS Charging Complete.";
CM_ SG_ 502 HVCMS_BulkChargingComplete "This signal indicates the HVCMS Bulk Charging Complete.";
CM_ SG_ 242 MC_PF1 "Message counter according to SAE J1850 standard that has to be calculated from bit 63 to bit 8 at each frame transmission.";
CM_ SG_ 242 INVFInterlockSts "Front inverter interlock state";
CM_ SG_ 242 InvF_DC_Voltage "Inverter Front DC Voltage.";
CM_ SG_ 242 CRC_PF1 "CRC according to SAE J1850 standard that has to be calculated from bit 63 to bit 8 at each frame transmission.";
CM_ SG_ 498 HVCMS_EVSEPeakCurrentRipple "Peak-to-peak magnitude of the current ripple of the EVSE.";
CM_ SG_ 498 HVCMS_EVSEMaxPowerLimit "Maximum power the EVSE can deliver.";
CM_ SG_ 498 HVCMS_EVSECurrRegulationTol "Absolute magnitude of the regulation tolerance of the EVSE.";
CM_ SG_ 498 HVCMS_EnergyToBeDelivered "Amount of energy to be delivered by the EVSE.";
CM_ SG_ 498 DC_TimeOut "DC Charging session time out";
CM_ SG_ 498 DC_Isolation_Disable_Cmd "Isolation Disabling command for DC charging";
CM_ SG_ 1579 OBCM_PLUG_STS "Plug Status retrieved by the VDCM according to the proximity Sts and pilot Sts and current input available sent by the OBCM";
CM_ SG_ 478 OBC_OperativeModeReq "This signal indicates the Onboard charger mode request";
CM_ SG_ 478 HV_Volt_Min_Thrsh "This signal indicates the Commanded minimum Traction Battery Voltage to On Board Charger.";
CM_ SG_ 478 HV_Volt_Max_Thrsh "This signal indicates the Commanded maximum Traction Battery Voltage to On Board Charger.";
CM_ SG_ 478 DC_Curr_Max_Thrsh "Maximum Threshold for charging DC current.";
CM_ SG_ 478 ChargeEnable "Charge Enable";
CM_ SG_ 478 AC_Curr_Min_Thrsh "Commanded AC current min threshold to On Board Charge";
CM_ SG_ 478 AC_Curr_Max_Thrsh "Commanded AC current max threshold to On Board Charge";
CM_ SG_ 1578 OnboardChargerReady "OBCM Ready status";
CM_ SG_ 1578 OnboardChargerMode "OBCM operative mode";
CM_ SG_ 1578 OBC_WakeReason "OBCM wakeup status";
CM_ SG_ 1578 OBC_GenericFailSts ".";
CM_ SG_ 1578 OBC_FaultReason "OBCM Fault Reason";
CM_ SG_ 1578 OBC_EVServiceLampOn "Ev service On request from OBCM";
CM_ SG_ 1578 OBC_EVServiceLampFlash "Ev service LIGHT flash from OBCM";
CM_ SG_ 1578 OBC_CurrentFailureSts ".";
CM_ SG_ 1578 OBC_ChargingFaultSts "OBCM charging fault status";
CM_ SG_ 1578 OBC_ChargeFailure "0 = Open, 1 = Off/SNA";
CM_ SG_ 1578 OBC_CaptureEnvironmentData "Capture Environmental Data";
CM_ SG_ 1578 ACplug_PwrMax "Maximum  AC power limit";
CM_ SG_ 2654486653 SourceNodeIdentifier_1E38407D "Source Node Identifier";
CM_ SG_ 2654486598 SourceNodeIdentifier_1E384046 "Source Node Identifier";
CM_ SG_ 478 CurrentRequest "HCP current request to the on board charger";
CM_ SG_ 276 DriveReady "Ready to Drive, [1] = Vehicle is allowed to shift out of park or neutral";
CM_ SG_ 502 VDCM_TypeCNegotiationSts "This signal indicates the Status of Negotiation in case of Type C EVSE";
CM_ SG_ 502 VDCM_GenChallenge "This signal indicates the Contract Authentication request gen challenge.";
CM_ SG_ 502 VDCM_ContractAuthenticationID "This signal indicates the Contract Authentication ID.";
CM_ SG_ 502 HVCMS_EVEnergyRequest "This signal indicates the HVCMS EV Energy Request.";
CM_ SG_ 242 InvF_DerateReason "Inverter Derating Reason";
CM_ SG_ 498 OBCM_PLCTypeSts "Power Line communication";
CM_ SG_ 498 HVCMS_EVSEMinimumVoltageLimit "For communication with charging station type A,B,C";
CM_ SG_ 498 HVCMS_EVSEMaximumVoltageLimit "For communication with charging station type A,B,C";
CM_ SG_ 1579 ChargeSystemSts "Charging System status";
CM_ SG_ 1579 ChargeSystemFault "Charging System Fault status";
CM_ SG_ 753 IDCM_Wakeup_HCP "IDCM wakeup event for charging";
CM_ SG_ 502 OBCM_OutVoltageSyncTgt "This signal indicates the OBCM Precharge Voltage Level";
CM_ SG_ 242 MCPA_Torque_Achieved "Motr B Torque Achieved";
CM_ SG_ 242 MCPA_TorqAchieved_AEMD_V "Motor Torque Achieved Validity";
CM_ SG_ 242 MCPA_TorqAchieved_AEMD "Motor Torque Achieved";
CM_ SG_ 242 MCPA_Spd_Lim "Limited motor speed during reduced performance from MCP B";
CM_ SG_ 242 MCPA_RPM_V "Motor A Speed Validity, [1] = True";
CM_ SG_ 242 MCPA_RPM "Motor A Speed Raw";
CM_ SG_ 242 MCPA_MtrMinCpbltyTrq "Motor A Min Capability Torque";
CM_ SG_ 242 MCPA_MtrMaxCpbltyTrq "Motor A Max Capability Torque";
CM_ SG_ 242 MCPA_MtrIndex "Motor A Capability Curve Array Index";
CM_ SG_ 242 MCPA_MinTorq "Motor A Minimum Torque";
CM_ SG_ 242 MCPA_MaxTorq "Motor A Maximum Torque";
CM_ SG_ 242 MCPA_Invrtr_State "Inverter State of Operation of Motor A";
CM_ SG_ 242 MCPA_HV_CnctrOpn_Req "HV Battery pack contactor request";
CM_ SG_ 242 MCPA_Dschrge_Status "The active discharge status of MCPA";
CM_ SG_ 242 MCPA_DeratingFactor "Motor A Derating Factor";
CM_ SG_ 242 MCPA_DC_Volt_V "Motor A DC current  validity, [1] = True";
CM_ SG_ 242 MCPA_DC_Current_V "Motor A DC current  validity, [1] = True";
CM_ SG_ 242 MCPA_DC_Current "Motor A DC Current";
CM_ SG_ 242 MCPA_CpbltySpdDivVolt "Motor A Speed at Capability Curve";
CM_ SG_ 242 MCPA_AccelRawV "Motor A Acceleration Validity";
CM_ SG_ 242 MCPA_AccelRaw "Motor A Acceleration";
CM_ SG_ 242 MCPA_6SO_Status "Motor A 6SO Status";
CM_ SG_ 242 MCPA_3PS_Pos "3 phase motor short possible from MCP B; True = [1]";
CM_ SG_ 478 VDCM_StsWldgReq "This signal indicates the welding check request from VDCM";
CM_ SG_ 478 VDCM_SessnStopReq "This signal indicates the session stop request from VDCM";
CM_ SG_ 2654486653 CBV_bit0_RepeatMessageRequestBit_1E38407D "Repeat Message Request Bit";
CM_ SG_ 2654486653 CBV_bit3_NMCoordinatorBit_1E38407D "NM Coordinator Sleep Bit";
CM_ SG_ 2654486653 CBV_bit4_ActiveWakeupBit_1E38407D "Active Wakeup Bit";
CM_ SG_ 2654486653 CBV_bit6_PartialNtwInfBit_1E38407D "Partial Network Information Bit (PNI)";
CM_ SG_ 2654486529 CBV_bit0_RepeatMessageRequestBit_1E384001 "Repeat Message Request Bit";
CM_ SG_ 2654486529 CBV_bit3_NMCoordinatorBit_1E384001 "NM Coordinator Sleep Bit";
CM_ SG_ 2654486529 CBV_bit4_ActiveWakeupBit_1E384001 "Active Wakeup Bit";
CM_ SG_ 2654486529 CBV_bit6_PartialNtwInfBit_1E384001 "Partial Network Information Bit (PNI)";
CM_ SG_ 2654486529 SourceNodeIdentifier_1E384001 "Source Node Identifier";
CM_ SG_ 2654486598 CBV_bit0_RepeatMessageRequestBit_1E384046 "Repeat Message Request Bit";
CM_ SG_ 2654486598 CBV_bit3_NMCoordinatorBit_1E384046 "NM Coordinator Sleep Bit";
CM_ SG_ 2654486598 CBV_bit4_ActiveWakeupBit_1E384046 "Active Wakeup Bit";
CM_ SG_ 2654486598 CBV_bit6_PartialNtwInfBit_1E384046 "Partial Network Information Bit (PNI)";
CM_ SG_ 1033 MessageCounter_HYBRID_POWERTRAI_409 "This signal is a counter used for safety checks strategies. This counter is incremented of 1 (one) unit at each frame transmission.";
CM_ SG_ 269 MessageCounter_HYBRID_POWERTRAI_10D "This signal is a counter used for safety checks strategies. This counter is incremented of 1 (one) unit at each frame transmission.";
CM_ SG_ 276 MessageCounter_HYBRID_POWERTRAI_114 "This signal is a counter used for safety checks strategies. This counter is incremented of 1 (one) unit at each frame transmission.";
CM_ SG_ 242 InvF_CoolantTemp "PIM Coolant Temperature";
CM_ SG_ 498 HVCMS_TxMessageStat "Response code from the Charging Station";
CM_ SG_ 498 HVCMS_ResponseCode "Response code from the Charging Station";
CM_ SG_ 1579 CRC_HYBRID_CHARGING_STATUS "CRC according to SAE J1850 standard at each frame transmission.";
CM_ SG_ 478 VDCM_StsSWWldgReq "Software welding check request from VDCM";
CM_ SG_ 1578 OBCM_PrechargeSts "OBCM precharge status feedback";
CM_ SG_ 502 HVCMS_ServiceCategory "This signal indicates the HVCMS Service Category.";
CM_ SG_ 502 HVCMS_SelectedServiceId "This signal indicates the HVCMS Selected Service Identifier.";
CM_ SG_ 502 HVCMS_SelectedPaymentOptn "This signal indicates the HVCMS Selected Payment Option.";
CM_ SG_ 502 HVCMS_SelectedEnergyTransferType "This signal indicates the HVCMS Selected Energy Transfer Type.";
CM_ SG_ 502 HVCMS_RemaningTimeToFullSOC "This signal indicates the HVCM Remaning Time To Full SOC.";
CM_ SG_ 502 HVCMS_RemaningTimeToBulkSOC "This signal indicates the HVCM Remaning Time To Bulk SOC.";
CM_ SG_ 502 HVCMS_EVErrorCode "This signal indicates the HVCMS EV Error Code.";
CM_ SG_ 242 MCPA_Torque_Achieved_V "Achieved Torque value Validity, [1] = True";
CM_ SG_ 242 MCPA_SPT_Stat "Inverter Isolation Status";
CM_ SG_ 498 TxMessageResponse "This signal indicates the HVCMS Service Category.";
CM_ SG_ 498 EVSE_ServiceId "EVSE Service ID";
CM_ SG_ 498 EVSE_OfferedPaymentOptn "List of payment options offered.";
CM_ SG_ 1578 ChrgFailSts "TxMessageResponse from EVSE.";
CM_ SG_ 1053 VIN_DATA "VIN Digits (8 bit ascii encoded)";
CM_ SG_ 1033 HCP_HoodAjar "Diagnosed hood status for HVIL";
CM_ SG_ 271 RedSpkAuthorityAvbl "Reduced Spark Availability Warning";
CM_ SG_ 271 EngMinSparkNomCurrAirTorqCap "Engine Torque capacity at current airflow  min and  nominal spark advance.";
CM_ SG_ 1032 MessageCounter_HYBRID_THERMAL_C "This signal is a counter used for safety checks strategies. This counter is incremented of 1 (one) unit at each frame transmission.";
CM_ SG_ 1032 CRC_HYBRID_THERMAL_COMMAND "CRC according to SAE J1850 standard at each frame transmission.";
CM_ SG_ 1579 MessageCounter_HYBRID_CHARGING__62B "This signal is a counter used for safety checks strategies. This counter is incremented of 1 (one) unit at each frame transmission.";
CM_ SG_ 478 MessageCounter_HYBRID_CHARGING__1DE "This signal is a counter used for safety checks strategies. This counter is incremented of 1 (one) unit at each frame transmission.";
CM_ SG_ 1032 SGCP_OIL_TEMP "SGCP Oil Temperature in generator";
CM_ SG_ 1032 SGCP_OIL_FlwRate "SGCP Oil Flow Rate through generator";
CM_ SG_ 1032 EOPB_OIL_TEMP "EOPB Oil Temperature in EDM B";
CM_ SG_ 1032 EOPB_OIL_FlwRate "EOPB Oil Flow Rate through EDM B";
CM_ SG_ 1032 EOPA_OIL_TEMP "EOPA Oil Temperature in EDM A";
CM_ SG_ 1032 EOPA_OIL_FlwRate "EOPA Oil Flow Rate through EDM A";
CM_ SG_ 498 EVSE_Supported_ISO1 "Used to report if ISO15118_2 protocol is offered or not.";
CM_ SG_ 498 EVSE_Supported_DIN "Used to report if DIN protocol is offered or not.";
CM_ SG_ 498 EVSE_Supported_SAE "Used to report if SAE protocol is offered or not.";
CM_ SG_ 498 EVSE_Service2_Certificate "Used to report the availability of Contract Certificate services.";
CM_ SG_ 498 EVSE_OfferedPaymentEIM "Used to report if EIM is offered as a method of paymet by EVSE.";
CM_ SG_ 498 EVSE_OfferedPaymentContract "Used to report if Contract is offered as a method of paymet by EVSE.";
CM_ SG_ 498 EVSE_Notification "This signal contains an action that the SECC wants the EVCC to perform.";
BA_DEF_ SG_ "GenSigTimeoutTime_ECM" INT 0 65535;
BA_DEF_ SG_ "GenSigTimeoutTime_BPCM" INT 0 65535;
BA_DEF_ SG_ "SystemSignalLongSymbol" STRING ;
BA_DEF_ SG_ "GenSigSendType" ENUM "NotUsed","OnWrite","OnWriteWithRepetition","OnChange","OnChangeWithRepetition","IfActive","IfActiveWithRepetition","NoSigSendType";
BA_DEF_ SG_ "GenSigInactiveValue" INT 0 2147483647;
BA_DEF_ SG_ "GenSigStartValue" INT 0 2147483647;
BA_DEF_ BU_ "NwmNodeType" ENUM "+15_NotWakeable","+30_Wakeable","+30_NotWakeable","kMaster","kSlave15","kSlave30","none";
BA_DEF_ BU_ "NmNodeType" ENUM "+15_NotWakeable","+30_Wakeable","+30_NotWakeable","kMaster","kSlave15","kSlave30","none";
BA_DEF_ BU_ "NmAsrCanMsgReducedTime" INT 1 65535;
BA_DEF_ BU_ "NmAsrNodeIdentifier" HEX 0 255;
BA_DEF_ BU_ "NmAsrNode" ENUM "No","Yes";
BA_DEF_ BU_ "NmNode" ENUM "No","Yes";
BA_DEF_ BU_ "NmStationAddress" HEX 0 255;
BA_DEF_ BU_ "Description" STRING ;
BA_DEF_ "VersionYear" INT 0 99;
BA_DEF_ "VersionWeek" INT 0 53;
BA_DEF_ "Version" HEX 0 255;
BA_DEF_ "NmAsrCanMsgCycleTime" INT 1 65535;
BA_DEF_ "NmAsrBaseAddress" HEX 235487232 2147483647;
BA_DEF_ "NmAsrMessageCount" INT 1 256;
BA_DEF_ "NmAsrRepeatMessageTime" INT 1 65535;
BA_DEF_ "NmAsrWaitBusSleepTime" INT 1 65535;
BA_DEF_ "NmAsrTimeoutTime" INT 1 65535;
BA_DEF_ "DBName" STRING ;
BA_DEF_ "Baudrate" INT 0 1000000;
BA_DEF_ "BusType" STRING ;
BA_DEF_ "NmType" STRING ;
BA_DEF_ "Manufacturer" ENUM "DBAG","VAG","BWVAG","PAG","GM";
BA_DEF_ BO_ "CANFD_BRS" ENUM "0","1";
BA_DEF_ BO_ "VFrameFormat" ENUM "StandardCAN","ExtendedCAN","reserved","reserved","reserved","reserved","reserved","reserved","reserved","reserved","reserved","reserved","reserved","reserved","StandardCAN_FD","ExtendedCAN_FD";
BA_DEF_ BO_ "DiagConnection" HEX 0 65535;
BA_DEF_ BO_ "DiagState" ENUM "No","Yes";
BA_DEF_ BO_ "NmAsrMessage" ENUM "No","Yes";
BA_DEF_ BO_ "GenMsgDelayTime" INT 0 65535;
BA_DEF_ BO_ "GenMsgCycleTime" INT 0 65535;
BA_DEF_ BO_ "GenMsgCycleTimeFast" INT 0 65535;
BA_DEF_ BO_ "GenMsgStartDelayTime" INT 0 65535;
BA_DEF_ BO_ "GenMsgILSupport" ENUM "No","Yes";
BA_DEF_ BO_ "GenMsgNrOfRepetition" INT 0 255;
BA_DEF_ BO_ "GenMsgSendType" ENUM "Cyclic","NotUsed","NotUsed","NotUsed","NotUsed","NotUsed","NotUsed","NotUsed","NoMsgSendType";
BA_DEF_ BO_ "NmMessage" ENUM "No","Yes";
BA_DEF_ BO_ "DiagResponse" ENUM "No","Yes";
BA_DEF_ BO_ "Type" ENUM "P","C","PE","COC","PE_Cntrl","E","E_Cntrl","OC","S","BAF","DC","EM","MM","ISO-TP","-";
BA_DEF_ BO_ "DiagRequest" ENUM "No","Yes";
BA_DEF_ SG_ "GenSigTimeoutTime_SGCP" INT 0 65535;
BA_DEF_ SG_ "GenSigTimeoutTime_MCPB" INT 0 65535;
BA_DEF_ SG_ "GenSigTimeoutTime_MCPA" INT 0 65535;
BA_DEF_ SG_ "GenSigTimeoutTime_IDCM" INT 0 65535;
BA_DEF_ SG_ "GenSigTimeoutTime_EVCU2" INT 0 65535;
BA_DEF_DEF_ "GenSigTimeoutTime_ECM" 2500;
BA_DEF_DEF_ "GenSigTimeoutTime_BPCM" 2500;
BA_DEF_DEF_ "SystemSignalLongSymbol" "";
BA_DEF_DEF_ "GenSigSendType" "NoSigSendType";
BA_DEF_DEF_ "GenSigInactiveValue" 0;
BA_DEF_DEF_ "GenSigStartValue" 0;
BA_DEF_DEF_ "NwmNodeType" "none";
BA_DEF_DEF_ "NmNodeType" "none";
BA_DEF_DEF_ "NmAsrCanMsgReducedTime" 100;
BA_DEF_DEF_ "NmAsrNodeIdentifier" 0;
BA_DEF_DEF_ "NmAsrNode" "Yes";
BA_DEF_DEF_ "NmNode" "Yes";
BA_DEF_DEF_ "NmStationAddress" 0;
BA_DEF_DEF_ "Description" "";
BA_DEF_DEF_ "VersionYear" 23;
BA_DEF_DEF_ "VersionWeek" 17;
BA_DEF_DEF_ "Version" 160;
BA_DEF_DEF_ "NmAsrCanMsgCycleTime" 200;
BA_DEF_DEF_ "NmAsrBaseAddress" 506724352;
BA_DEF_DEF_ "NmAsrMessageCount" 256;
BA_DEF_DEF_ "NmAsrRepeatMessageTime" 800;
BA_DEF_DEF_ "NmAsrWaitBusSleepTime" 750;
BA_DEF_DEF_ "NmAsrTimeoutTime" 1000;
BA_DEF_DEF_ "DBName" "CAN";
BA_DEF_DEF_ "Baudrate" 500000;
BA_DEF_DEF_ "BusType" "CAN";
BA_DEF_DEF_ "NmType" "";
BA_DEF_DEF_ "Manufacturer" "DBAG";
BA_DEF_DEF_ "CANFD_BRS" "0";
BA_DEF_DEF_ "VFrameFormat" "StandardCAN_FD";
BA_DEF_DEF_ "DiagConnection" 0;
BA_DEF_DEF_ "DiagState" "No";
BA_DEF_DEF_ "NmAsrMessage" "No";
BA_DEF_DEF_ "GenMsgDelayTime" 0;
BA_DEF_DEF_ "GenMsgCycleTime" 0;
BA_DEF_DEF_ "GenMsgCycleTimeFast" 0;
BA_DEF_DEF_ "GenMsgStartDelayTime" 0;
BA_DEF_DEF_ "GenMsgILSupport" "No";
BA_DEF_DEF_ "GenMsgNrOfRepetition" 0;
BA_DEF_DEF_ "GenMsgSendType" "NoMsgSendType";
BA_DEF_DEF_ "NmMessage" "No";
BA_DEF_DEF_ "DiagResponse" "No";
BA_DEF_DEF_ "Type" "-";
BA_DEF_DEF_ "DiagRequest" "No";
BA_DEF_DEF_ "GenSigTimeoutTime_SGCP" 2500;
BA_DEF_DEF_ "GenSigTimeoutTime_MCPB" 2500;
BA_DEF_DEF_ "GenSigTimeoutTime_MCPA" 2500;
BA_DEF_DEF_ "GenSigTimeoutTime_IDCM" 2500;
BA_DEF_DEF_ "GenSigTimeoutTime_EVCU2" 2500;
BA_ "NmAsrBaseAddress" 507002880;
BA_ "NmAsrCanMsgCycleTime" 1000;
BA_ "NmAsrRepeatMessageTime" 5000;
BA_ "NmAsrWaitBusSleepTime" 1000;
BA_ "NmAsrTimeoutTime" 8000;
BA_ "DBName" "FDCAN5";
BA_ "BusType" "CAN FD";
BA_ "NmType" "NmAsr";
BA_ "NwmNodeType" BU_ BPCM 1;
BA_ "NmNodeType" BU_ BPCM 1;
BA_ "NmAsrCanMsgReducedTime" BU_ BPCM 525;
BA_ "NmAsrNodeIdentifier" BU_ BPCM 70;
BA_ "NmStationAddress" BU_ BPCM 70;
BA_ "Description" BU_ BPCM "Battery Pack Control Module";
BA_ "NwmNodeType" BU_ ECM 0;
BA_ "NmNodeType" BU_ ECM 0;
BA_ "NmAsrCanMsgReducedTime" BU_ ECM 575;
BA_ "NmAsrNodeIdentifier" BU_ ECM 1;
BA_ "NmAsrNode" BU_ ECM 0;
BA_ "NmNode" BU_ ECM 0;
BA_ "NmStationAddress" BU_ ECM 1;
BA_ "Description" BU_ ECM "Engine Control Module";
BA_ "NwmNodeType" BU_ EVCU2 1;
BA_ "NmNodeType" BU_ EVCU2 1;
BA_ "NmAsrCanMsgReducedTime" BU_ EVCU2 950;
BA_ "NmAsrNodeIdentifier" BU_ EVCU2 64;
BA_ "NmStationAddress" BU_ EVCU2 64;
BA_ "Description" BU_ EVCU2 "Electric Vehicle Control Unit 2";
BA_ "NwmNodeType" BU_ IDCM 1;
BA_ "NmNodeType" BU_ IDCM 1;
BA_ "NmAsrCanMsgReducedTime" BU_ IDCM 600;
BA_ "NmAsrNodeIdentifier" BU_ IDCM 125;
BA_ "NmStationAddress" BU_ IDCM 125;
BA_ "Description" BU_ IDCM "Integrated Dual Charge Module";
BA_ "NwmNodeType" BU_ MCPA 1;
BA_ "NmNodeType" BU_ MCPA 1;
BA_ "NmAsrCanMsgReducedTime" BU_ MCPA 625;
BA_ "NmAsrNodeIdentifier" BU_ MCPA 88;
BA_ "NmStationAddress" BU_ MCPA 88;
BA_ "Description" BU_ MCPA "Motor Control Processor A";
BA_ "NwmNodeType" BU_ MCPB 1;
BA_ "NmNodeType" BU_ MCPB 1;
BA_ "NmAsrCanMsgReducedTime" BU_ MCPB 650;
BA_ "NmAsrNodeIdentifier" BU_ MCPB 89;
BA_ "NmStationAddress" BU_ MCPB 89;
BA_ "Description" BU_ MCPB "Motor Control Processor B";
BA_ "NwmNodeType" BU_ SGCP 1;
BA_ "NmNodeType" BU_ SGCP 1;
BA_ "NmAsrCanMsgReducedTime" BU_ SGCP 675;
BA_ "NmAsrNodeIdentifier" BU_ SGCP 201;
BA_ "NmStationAddress" BU_ SGCP 201;
BA_ "Description" BU_ SGCP "Starter Generator Control Processor";
BA_ "CANFD_BRS" BO_ 2651930624 1;
BA_ "VFrameFormat" BO_ 2651930624 15;
BA_ "GenMsgDelayTime" BO_ 2651930624 10;
BA_ "GenMsgILSupport" BO_ 2651930624 1;
BA_ "Type" BO_ 2651930624 8;
BA_ "VFrameFormat" BO_ 2564554481 1;
BA_ "DiagConnection" BO_ 2564554481 61950;
BA_ "DiagState" BO_ 2564554481 1;
BA_ "Type" BO_ 2564554481 8;
BA_ "VFrameFormat" BO_ 2564502513 1;
BA_ "DiagConnection" BO_ 2564502513 61747;
BA_ "DiagState" BO_ 2564502513 1;
BA_ "Type" BO_ 2564502513 8;
BA_ "CANFD_BRS" BO_ 1053 1;
BA_ "GenMsgCycleTime" BO_ 1053 100;
BA_ "GenMsgILSupport" BO_ 1053 1;
BA_ "GenMsgSendType" BO_ 1053 0;
BA_ "Type" BO_ 1053 1;
BA_ "CANFD_BRS" BO_ 520 1;
BA_ "GenMsgCycleTime" BO_ 520 20;
BA_ "GenMsgILSupport" BO_ 520 1;
BA_ "GenMsgSendType" BO_ 520 0;
BA_ "Type" BO_ 520 1;
BA_ "GenMsgILSupport" BO_ 156 1;
BA_ "Type" BO_ 156 8;
BA_ "CANFD_BRS" BO_ 156 1;
BA_ "CANFD_BRS" BO_ 1058 1;
BA_ "GenMsgCycleTime" BO_ 1058 100;
BA_ "GenMsgILSupport" BO_ 1058 1;
BA_ "GenMsgSendType" BO_ 1058 0;
BA_ "Type" BO_ 1058 1;
BA_ "CANFD_BRS" BO_ 1829 1;
BA_ "GenMsgCycleTime" BO_ 1829 1000;
BA_ "GenMsgILSupport" BO_ 1829 1;
BA_ "GenMsgSendType" BO_ 1829 0;
BA_ "Type" BO_ 1829 1;
BA_ "GenMsgCycleTimeFast" BO_ 1626 10;
BA_ "GenMsgILSupport" BO_ 1626 1;
BA_ "GenMsgSendType" BO_ 1626 0;
BA_ "Type" BO_ 1626 10;
BA_ "CANFD_BRS" BO_ 1626 1;
BA_ "GenMsgCycleTime" BO_ 1626 500;
BA_ "CANFD_BRS" BO_ 518 1;
BA_ "GenMsgCycleTime" BO_ 518 20;
BA_ "GenMsgILSupport" BO_ 518 1;
BA_ "GenMsgSendType" BO_ 518 0;
BA_ "Type" BO_ 518 1;
BA_ "GenMsgCycleTime" BO_ 1054 100;
BA_ "GenMsgILSupport" BO_ 1054 1;
BA_ "GenMsgSendType" BO_ 1054 0;
BA_ "Type" BO_ 1054 1;
BA_ "CANFD_BRS" BO_ 1054 1;
BA_ "CANFD_BRS" BO_ 2564554482 1;
BA_ "VFrameFormat" BO_ 2564554482 15;
BA_ "DiagConnection" BO_ 2564554482 62206;
BA_ "DiagState" BO_ 2564554482 1;
BA_ "Type" BO_ 2564554482 8;
BA_ "CANFD_BRS" BO_ 1155 1;
BA_ "GenMsgDelayTime" BO_ 1155 20;
BA_ "GenMsgCycleTime" BO_ 1155 500;
BA_ "GenMsgCycleTimeFast" BO_ 1155 20;
BA_ "GenMsgILSupport" BO_ 1155 1;
BA_ "GenMsgNrOfRepetition" BO_ 1155 2;
BA_ "GenMsgSendType" BO_ 1155 0;
BA_ "Type" BO_ 1155 3;
BA_ "CANFD_BRS" BO_ 609 1;
BA_ "GenMsgCycleTime" BO_ 609 100;
BA_ "GenMsgCycleTimeFast" BO_ 609 20;
BA_ "GenMsgILSupport" BO_ 609 1;
BA_ "GenMsgNrOfRepetition" BO_ 609 2;
BA_ "GenMsgSendType" BO_ 609 0;
BA_ "Type" BO_ 609 3;
BA_ "CANFD_BRS" BO_ 1066 1;
BA_ "GenMsgDelayTime" BO_ 1066 20;
BA_ "GenMsgCycleTime" BO_ 1066 250;
BA_ "GenMsgCycleTimeFast" BO_ 1066 20;
BA_ "GenMsgILSupport" BO_ 1066 1;
BA_ "GenMsgNrOfRepetition" BO_ 1066 2;
BA_ "GenMsgSendType" BO_ 1066 0;
BA_ "Type" BO_ 1066 3;
BA_ "CANFD_BRS" BO_ 1827 1;
BA_ "GenMsgCycleTime" BO_ 1827 1000;
BA_ "GenMsgILSupport" BO_ 1827 1;
BA_ "GenMsgSendType" BO_ 1827 0;
BA_ "Type" BO_ 1827 1;
BA_ "CANFD_BRS" BO_ 256 1;
BA_ "GenMsgCycleTime" BO_ 256 10;
BA_ "GenMsgILSupport" BO_ 256 1;
BA_ "GenMsgSendType" BO_ 256 0;
BA_ "Type" BO_ 256 1;
BA_ "CANFD_BRS" BO_ 1153 1;
BA_ "GenMsgDelayTime" BO_ 1153 20;
BA_ "GenMsgCycleTime" BO_ 1153 500;
BA_ "GenMsgCycleTimeFast" BO_ 1153 20;
BA_ "GenMsgILSupport" BO_ 1153 1;
BA_ "GenMsgNrOfRepetition" BO_ 1153 2;
BA_ "GenMsgSendType" BO_ 1153 0;
BA_ "Type" BO_ 1153 3;
BA_ "CANFD_BRS" BO_ 753 1;
BA_ "GenMsgCycleTime" BO_ 753 50;
BA_ "GenMsgILSupport" BO_ 753 1;
BA_ "GenMsgSendType" BO_ 753 0;
BA_ "Type" BO_ 753 1;
BA_ "CANFD_BRS" BO_ 1032 1;
BA_ "GenMsgCycleTime" BO_ 1032 100;
BA_ "GenMsgILSupport" BO_ 1032 1;
BA_ "GenMsgSendType" BO_ 1032 0;
BA_ "Type" BO_ 1032 1;
BA_ "CANFD_BRS" BO_ 267 1;
BA_ "GenMsgCycleTime" BO_ 267 10;
BA_ "GenMsgILSupport" BO_ 267 1;
BA_ "GenMsgSendType" BO_ 267 0;
BA_ "Type" BO_ 267 1;
BA_ "CANFD_BRS" BO_ 1033 1;
BA_ "GenMsgCycleTime" BO_ 1033 100;
BA_ "GenMsgILSupport" BO_ 1033 1;
BA_ "GenMsgSendType" BO_ 1033 0;
BA_ "Type" BO_ 1033 1;
BA_ "CANFD_BRS" BO_ 1034 1;
BA_ "GenMsgCycleTime" BO_ 1034 100;
BA_ "GenMsgILSupport" BO_ 1034 1;
BA_ "GenMsgSendType" BO_ 1034 0;
BA_ "Type" BO_ 1034 1;
BA_ "CANFD_BRS" BO_ 1328 1;
BA_ "GenMsgCycleTime" BO_ 1328 200;
BA_ "GenMsgILSupport" BO_ 1328 1;
BA_ "GenMsgSendType" BO_ 1328 0;
BA_ "Type" BO_ 1328 1;
BA_ "CANFD_BRS" BO_ 1035 1;
BA_ "GenMsgCycleTime" BO_ 1035 100;
BA_ "GenMsgILSupport" BO_ 1035 1;
BA_ "GenMsgSendType" BO_ 1035 0;
BA_ "Type" BO_ 1035 1;
BA_ "CANFD_BRS" BO_ 750 1;
BA_ "GenMsgCycleTime" BO_ 750 50;
BA_ "GenMsgILSupport" BO_ 750 1;
BA_ "GenMsgSendType" BO_ 750 0;
BA_ "Type" BO_ 750 1;
BA_ "CANFD_BRS" BO_ 2654486529 1;
BA_ "VFrameFormat" BO_ 2654486529 15;
BA_ "NmAsrMessage" BO_ 2654486529 1;
BA_ "NmMessage" BO_ 2654486529 1;
BA_ "Type" BO_ 2654486529 8;
BA_ "GenMsgILSupport" BO_ 269 1;
BA_ "GenMsgSendType" BO_ 269 0;
BA_ "Type" BO_ 269 1;
BA_ "CANFD_BRS" BO_ 269 1;
BA_ "GenMsgCycleTime" BO_ 269 10;
BA_ "CANFD_BRS" BO_ 276 1;
BA_ "GenMsgCycleTime" BO_ 276 10;
BA_ "GenMsgILSupport" BO_ 276 1;
BA_ "GenMsgSendType" BO_ 276 0;
BA_ "Type" BO_ 276 1;
BA_ "GenMsgCycleTime" BO_ 271 10;
BA_ "GenMsgILSupport" BO_ 271 1;
BA_ "GenMsgSendType" BO_ 271 0;
BA_ "Type" BO_ 271 1;
BA_ "CANFD_BRS" BO_ 271 1;
BA_ "CANFD_BRS" BO_ 262 1;
BA_ "GenMsgCycleTime" BO_ 262 10;
BA_ "GenMsgILSupport" BO_ 262 1;
BA_ "GenMsgSendType" BO_ 262 0;
BA_ "Type" BO_ 262 1;
BA_ "CANFD_BRS" BO_ 258 1;
BA_ "GenMsgCycleTime" BO_ 258 10;
BA_ "GenMsgILSupport" BO_ 258 1;
BA_ "GenMsgSendType" BO_ 258 0;
BA_ "Type" BO_ 258 1;
BA_ "CANFD_BRS" BO_ 2654486653 1;
BA_ "VFrameFormat" BO_ 2654486653 15;
BA_ "NmAsrMessage" BO_ 2654486653 1;
BA_ "NmMessage" BO_ 2654486653 1;
BA_ "Type" BO_ 2654486653 8;
BA_ "VFrameFormat" BO_ 2654486598 15;
BA_ "NmAsrMessage" BO_ 2654486598 1;
BA_ "NmMessage" BO_ 2654486598 1;
BA_ "Type" BO_ 2654486598 8;
BA_ "CANFD_BRS" BO_ 2654486598 1;
BA_ "CANFD_BRS" BO_ 1579 1;
BA_ "GenMsgCycleTime" BO_ 1579 500;
BA_ "GenMsgILSupport" BO_ 1579 1;
BA_ "GenMsgSendType" BO_ 1579 0;
BA_ "Type" BO_ 1579 1;
BA_ "CANFD_BRS" BO_ 478 1;
BA_ "GenMsgCycleTime" BO_ 478 20;
BA_ "GenMsgILSupport" BO_ 478 1;
BA_ "GenMsgSendType" BO_ 478 0;
BA_ "Type" BO_ 478 1;
BA_ "CANFD_BRS" BO_ 1578 1;
BA_ "GenMsgCycleTime" BO_ 1578 500;
BA_ "GenMsgCycleTimeFast" BO_ 1578 10;
BA_ "GenMsgILSupport" BO_ 1578 1;
BA_ "GenMsgNrOfRepetition" BO_ 1578 3;
BA_ "GenMsgSendType" BO_ 1578 0;
BA_ "Type" BO_ 1578 3;
BA_ "CANFD_BRS" BO_ 1372 1;
BA_ "GenMsgCycleTime" BO_ 1372 250;
BA_ "GenMsgILSupport" BO_ 1372 1;
BA_ "GenMsgSendType" BO_ 1372 0;
BA_ "Type" BO_ 1372 1;
BA_ "CANFD_BRS" BO_ 1460 1;
BA_ "GenMsgDelayTime" BO_ 1460 20;
BA_ "GenMsgCycleTime" BO_ 1460 1000;
BA_ "GenMsgILSupport" BO_ 1460 1;
BA_ "GenMsgSendType" BO_ 1460 0;
BA_ "Type" BO_ 1460 3;
BA_ "CANFD_BRS" BO_ 502 1;
BA_ "GenMsgCycleTime" BO_ 502 20;
BA_ "GenMsgILSupport" BO_ 502 1;
BA_ "GenMsgSendType" BO_ 502 0;
BA_ "Type" BO_ 502 1;
BA_ "CANFD_BRS" BO_ 242 1;
BA_ "GenMsgCycleTime" BO_ 242 10;
BA_ "GenMsgILSupport" BO_ 242 1;
BA_ "GenMsgSendType" BO_ 242 0;
BA_ "Type" BO_ 242 1;
BA_ "CANFD_BRS" BO_ 498 1;
BA_ "GenMsgCycleTime" BO_ 498 20;
BA_ "GenMsgILSupport" BO_ 498 1;
BA_ "GenMsgSendType" BO_ 498 0;
BA_ "Type" BO_ 498 1;
BA_ "GenSigTimeoutTime_ECM" SG_ 1035 EngSpd 0;
BA_ "GenSigTimeoutTime_BPCM" SG_ 1035 EngSpd 0;
BA_ "GenSigTimeoutTime_SGCP" SG_ 1035 EngSpd 0;
BA_ "GenSigTimeoutTime_MCPB" SG_ 1035 EngSpd 0;
BA_ "GenSigTimeoutTime_MCPA" SG_ 1035 EngSpd 0;
BA_ "GenSigTimeoutTime_IDCM" SG_ 1035 EngSpd 0;
BA_ "GenSigTimeoutTime_ECM" SG_ 1035 MinEngSpdCap 0;
BA_ "GenSigTimeoutTime_BPCM" SG_ 1035 MinEngSpdCap 0;
BA_ "GenSigTimeoutTime_SGCP" SG_ 1035 MinEngSpdCap 0;
BA_ "GenSigTimeoutTime_MCPB" SG_ 1035 MinEngSpdCap 0;
BA_ "GenSigTimeoutTime_MCPA" SG_ 1035 MinEngSpdCap 0;
BA_ "GenSigTimeoutTime_IDCM" SG_ 1035 MinEngSpdCap 0;
BA_ "GenSigTimeoutTime_ECM" SG_ 1035 MaxEngSpdCap 0;
BA_ "GenSigTimeoutTime_BPCM" SG_ 1035 MaxEngSpdCap 0;
BA_ "GenSigTimeoutTime_SGCP" SG_ 1035 MaxEngSpdCap 0;
BA_ "GenSigTimeoutTime_MCPB" SG_ 1035 MaxEngSpdCap 0;
BA_ "GenSigTimeoutTime_MCPA" SG_ 1035 MaxEngSpdCap 0;
BA_ "GenSigTimeoutTime_IDCM" SG_ 1035 MaxEngSpdCap 0;
BA_ "GenSigTimeoutTime_IDCM" SG_ 1328 MessageCounter_ENGINE_HYBD_FD_4 0;
BA_ "GenSigTimeoutTime_ECM" SG_ 1328 EngTorqACCCapability 0;
BA_ "GenSigTimeoutTime_BPCM" SG_ 1328 EngTorqACCCapability 0;
BA_ "GenSigTimeoutTime_SGCP" SG_ 1328 EngTorqACCCapability 0;
BA_ "GenSigTimeoutTime_MCPB" SG_ 1328 EngTorqACCCapability 0;
BA_ "GenSigTimeoutTime_MCPA" SG_ 1328 EngTorqACCCapability 0;
BA_ "GenSigTimeoutTime_IDCM" SG_ 1328 EngTorqACCCapability 0;
BA_ "GenSigTimeoutTime_ECM" SG_ 1328 EngTorqCapbltyEngOpMd 0;
BA_ "GenSigTimeoutTime_BPCM" SG_ 1328 EngTorqCapbltyEngOpMd 0;
BA_ "GenSigTimeoutTime_SGCP" SG_ 1328 EngTorqCapbltyEngOpMd 0;
BA_ "GenSigTimeoutTime_MCPB" SG_ 1328 EngTorqCapbltyEngOpMd 0;
BA_ "GenSigTimeoutTime_MCPA" SG_ 1328 EngTorqCapbltyEngOpMd 0;
BA_ "GenSigTimeoutTime_IDCM" SG_ 1328 EngTorqCapbltyEngOpMd 0;
BA_ "GenSigTimeoutTime_ECM" SG_ 1328 EngTorqCapbltyFrmCntr 0;
BA_ "GenSigTimeoutTime_BPCM" SG_ 1328 EngTorqCapbltyFrmCntr 0;
BA_ "GenSigTimeoutTime_SGCP" SG_ 1328 EngTorqCapbltyFrmCntr 0;
BA_ "GenSigTimeoutTime_MCPB" SG_ 1328 EngTorqCapbltyFrmCntr 0;
BA_ "GenSigTimeoutTime_MCPA" SG_ 1328 EngTorqCapbltyFrmCntr 0;
BA_ "GenSigTimeoutTime_IDCM" SG_ 1328 EngTorqCapbltyFrmCntr 0;
BA_ "GenSigTimeoutTime_ECM" SG_ 1328 EngTorqCapbltyMinRunTorq 0;
BA_ "GenSigTimeoutTime_BPCM" SG_ 1328 EngTorqCapbltyMinRunTorq 0;
BA_ "GenSigStartValue" SG_ 1328 EngTorqCapbltyMinRunTorq 938;
BA_ "GenSigTimeoutTime_SGCP" SG_ 1328 EngTorqCapbltyMinRunTorq 0;
BA_ "GenSigTimeoutTime_MCPB" SG_ 1328 EngTorqCapbltyMinRunTorq 0;
BA_ "GenSigTimeoutTime_MCPA" SG_ 1328 EngTorqCapbltyMinRunTorq 0;
BA_ "GenSigTimeoutTime_IDCM" SG_ 1328 EngTorqCapbltyMinRunTorq 0;
BA_ "GenSigTimeoutTime_ECM" SG_ 1328 EngTorqCapbltyRefEngSpd 0;
BA_ "GenSigTimeoutTime_BPCM" SG_ 1328 EngTorqCapbltyRefEngSpd 0;
BA_ "GenSigTimeoutTime_SGCP" SG_ 1328 EngTorqCapbltyRefEngSpd 0;
BA_ "GenSigTimeoutTime_MCPB" SG_ 1328 EngTorqCapbltyRefEngSpd 0;
BA_ "GenSigTimeoutTime_MCPA" SG_ 1328 EngTorqCapbltyRefEngSpd 0;
BA_ "GenSigTimeoutTime_IDCM" SG_ 1328 EngTorqCapbltyRefEngSpd 0;
BA_ "GenSigTimeoutTime_ECM" SG_ 1328 EngTorqCapbltyMaxOffTorq 0;
BA_ "GenSigTimeoutTime_BPCM" SG_ 1328 EngTorqCapbltyMaxOffTorq 0;
BA_ "GenSigTimeoutTime_SGCP" SG_ 1328 EngTorqCapbltyMaxOffTorq 0;
BA_ "GenSigTimeoutTime_MCPB" SG_ 1328 EngTorqCapbltyMaxOffTorq 0;
BA_ "GenSigTimeoutTime_MCPA" SG_ 1328 EngTorqCapbltyMaxOffTorq 0;
BA_ "GenSigTimeoutTime_IDCM" SG_ 1328 EngTorqCapbltyMaxOffTorq 0;
BA_ "GenSigTimeoutTime_ECM" SG_ 2654486653 SourceNodeIdentifier_1E38407D 0;
BA_ "GenSigTimeoutTime_BPCM" SG_ 2654486653 SourceNodeIdentifier_1E38407D 0;
BA_ "GenSigTimeoutTime_ECM" SG_ 1328 EngTorqCapbltyMinTorq 0;
BA_ "GenSigTimeoutTime_BPCM" SG_ 1328 EngTorqCapbltyMinTorq 0;
BA_ "GenSigStartValue" SG_ 1328 EngTorqCapbltyMinTorq 938;
BA_ "GenSigTimeoutTime_SGCP" SG_ 1328 EngTorqCapbltyMinTorq 0;
BA_ "GenSigTimeoutTime_MCPB" SG_ 1328 EngTorqCapbltyMinTorq 0;
BA_ "GenSigTimeoutTime_MCPA" SG_ 1328 EngTorqCapbltyMinTorq 0;
BA_ "GenSigTimeoutTime_IDCM" SG_ 1328 EngTorqCapbltyMinTorq 0;
BA_ "GenSigTimeoutTime_ECM" SG_ 1328 EngTorqCapbltyMaxTorq 0;
BA_ "GenSigTimeoutTime_BPCM" SG_ 1328 EngTorqCapbltyMaxTorq 0;
BA_ "GenSigStartValue" SG_ 1328 EngTorqCapbltyMaxTorq 938;
BA_ "GenSigTimeoutTime_SGCP" SG_ 1328 EngTorqCapbltyMaxTorq 0;
BA_ "GenSigTimeoutTime_MCPB" SG_ 1328 EngTorqCapbltyMaxTorq 0;
BA_ "GenSigTimeoutTime_MCPA" SG_ 1328 EngTorqCapbltyMaxTorq 0;
BA_ "GenSigTimeoutTime_IDCM" SG_ 1328 EngTorqCapbltyMaxTorq 0;
BA_ "GenSigTimeoutTime_ECM" SG_ 1054 CRC_ENGINE1 0;
BA_ "GenSigTimeoutTime_BPCM" SG_ 1054 CRC_ENGINE1 0;
BA_ "GenSigTimeoutTime_SGCP" SG_ 1054 CRC_ENGINE1 0;
BA_ "GenSigTimeoutTime_MCPB" SG_ 1054 CRC_ENGINE1 0;
BA_ "GenSigTimeoutTime_MCPA" SG_ 1054 CRC_ENGINE1 0;
BA_ "GenSigTimeoutTime_IDCM" SG_ 1054 CRC_ENGINE1 0;
BA_ "GenSigTimeoutTime_ECM" SG_ 1054 MessageCounter_ENGINE1 0;
BA_ "GenSigTimeoutTime_BPCM" SG_ 1054 MessageCounter_ENGINE1 0;
BA_ "GenSigTimeoutTime_SGCP" SG_ 1054 MessageCounter_ENGINE1 0;
BA_ "GenSigTimeoutTime_MCPB" SG_ 1054 MessageCounter_ENGINE1 0;
BA_ "GenSigTimeoutTime_MCPA" SG_ 1054 MessageCounter_ENGINE1 0;
BA_ "GenSigTimeoutTime_IDCM" SG_ 1054 MessageCounter_ENGINE1 0;
BA_ "GenSigTimeoutTime_ECM" SG_ 1054 ThermalManagementActive_W 0;
BA_ "GenSigTimeoutTime_BPCM" SG_ 1054 ThermalManagementActive_W 0;
BA_ "GenSigTimeoutTime_SGCP" SG_ 1054 ThermalManagementActive_W 0;
BA_ "GenSigTimeoutTime_MCPB" SG_ 1054 ThermalManagementActive_W 0;
BA_ "GenSigTimeoutTime_MCPA" SG_ 1054 ThermalManagementActive_W 0;
BA_ "GenSigTimeoutTime_IDCM" SG_ 1054 ThermalManagementActive_W 0;
BA_ "GenSigTimeoutTime_ECM" SG_ 518 CRC_ENGINE5 0;
BA_ "GenSigTimeoutTime_BPCM" SG_ 518 CRC_ENGINE5 0;
BA_ "GenSigTimeoutTime_SGCP" SG_ 518 CRC_ENGINE5 0;
BA_ "GenSigTimeoutTime_MCPB" SG_ 518 CRC_ENGINE5 0;
BA_ "GenSigTimeoutTime_MCPA" SG_ 518 CRC_ENGINE5 0;
BA_ "GenSigTimeoutTime_IDCM" SG_ 518 CRC_ENGINE5 0;
BA_ "GenSigTimeoutTime_ECM" SG_ 518 MessageCounter_ENGINE5 0;
BA_ "GenSigTimeoutTime_BPCM" SG_ 518 MessageCounter_ENGINE5 0;
BA_ "GenSigTimeoutTime_SGCP" SG_ 518 MessageCounter_ENGINE5 0;
BA_ "GenSigTimeoutTime_MCPB" SG_ 518 MessageCounter_ENGINE5 0;
BA_ "GenSigTimeoutTime_MCPA" SG_ 518 MessageCounter_ENGINE5 0;
BA_ "GenSigTimeoutTime_IDCM" SG_ 518 MessageCounter_ENGINE5 0;
BA_ "GenSigTimeoutTime_ECM" SG_ 518 RPMOverRev_W 0;
BA_ "GenSigTimeoutTime_BPCM" SG_ 518 RPMOverRev_W 0;
BA_ "GenSigTimeoutTime_SGCP" SG_ 518 RPMOverRev_W 0;
BA_ "GenSigTimeoutTime_MCPB" SG_ 518 RPMOverRev_W 0;
BA_ "GenSigTimeoutTime_MCPA" SG_ 518 RPMOverRev_W 0;
BA_ "GenSigTimeoutTime_IDCM" SG_ 518 RPMOverRev_W 0;
BA_ "GenSigTimeoutTime_ECM" SG_ 1058 CRC_OBDCONTENTFRAME 0;
BA_ "GenSigTimeoutTime_BPCM" SG_ 1058 CRC_OBDCONTENTFRAME 0;
BA_ "GenSigTimeoutTime_SGCP" SG_ 1058 CRC_OBDCONTENTFRAME 0;
BA_ "GenSigTimeoutTime_MCPB" SG_ 1058 CRC_OBDCONTENTFRAME 0;
BA_ "GenSigTimeoutTime_MCPA" SG_ 1058 CRC_OBDCONTENTFRAME 0;
BA_ "GenSigTimeoutTime_IDCM" SG_ 1058 CRC_OBDCONTENTFRAME 0;
BA_ "GenSigTimeoutTime_ECM" SG_ 1058 MessageCounter_OBDCONTENTFRAME 0;
BA_ "GenSigTimeoutTime_BPCM" SG_ 1058 MessageCounter_OBDCONTENTFRAME 0;
BA_ "GenSigTimeoutTime_SGCP" SG_ 1058 MessageCounter_OBDCONTENTFRAME 0;
BA_ "GenSigTimeoutTime_MCPB" SG_ 1058 MessageCounter_OBDCONTENTFRAME 0;
BA_ "GenSigTimeoutTime_MCPA" SG_ 1058 MessageCounter_OBDCONTENTFRAME 0;
BA_ "GenSigTimeoutTime_IDCM" SG_ 1058 MessageCounter_OBDCONTENTFRAME 0;
BA_ "GenSigTimeoutTime_ECM" SG_ 262 CRC_ENGINE2 0;
BA_ "GenSigTimeoutTime_BPCM" SG_ 262 CRC_ENGINE2 0;
BA_ "GenSigTimeoutTime_SGCP" SG_ 262 CRC_ENGINE2 0;
BA_ "GenSigTimeoutTime_MCPB" SG_ 262 CRC_ENGINE2 0;
BA_ "GenSigTimeoutTime_MCPA" SG_ 262 CRC_ENGINE2 0;
BA_ "GenSigTimeoutTime_IDCM" SG_ 262 CRC_ENGINE2 0;
BA_ "GenSigTimeoutTime_ECM" SG_ 262 EngineSpeed_W 0;
BA_ "GenSigTimeoutTime_BPCM" SG_ 262 EngineSpeed_W 0;
BA_ "GenSigTimeoutTime_IDCM" SG_ 262 EngineSpeed_W 0;
BA_ "GenSigTimeoutTime_EVCU2" SG_ 262 EngineSpeed_W 0;
BA_ "GenSigTimeoutTime_ECM" SG_ 262 EngineSpeedFailSts_W 0;
BA_ "GenSigTimeoutTime_BPCM" SG_ 262 EngineSpeedFailSts_W 0;
BA_ "GenSigTimeoutTime_IDCM" SG_ 262 EngineSpeedFailSts_W 0;
BA_ "GenSigTimeoutTime_EVCU2" SG_ 262 EngineSpeedFailSts_W 0;
BA_ "GenSigTimeoutTime_ECM" SG_ 262 MessageCounter_ENGINE2 0;
BA_ "GenSigTimeoutTime_BPCM" SG_ 262 MessageCounter_ENGINE2 0;
BA_ "GenSigTimeoutTime_SGCP" SG_ 262 MessageCounter_ENGINE2 0;
BA_ "GenSigTimeoutTime_MCPB" SG_ 262 MessageCounter_ENGINE2 0;
BA_ "GenSigTimeoutTime_MCPA" SG_ 262 MessageCounter_ENGINE2 0;
BA_ "GenSigTimeoutTime_IDCM" SG_ 262 MessageCounter_ENGINE2 0;
BA_ "GenSigTimeoutTime_IDCM" SG_ 262 PowertrainPrplsnActv 0;
BA_ "GenSigTimeoutTime_EVCU2" SG_ 262 PowertrainPrplsnActv 0;
BA_ "GenSigTimeoutTime_MCPA" SG_ 276 MessageCounter_HYBRID_POWERTRAI_114 0;
BA_ "GenSigTimeoutTime_IDCM" SG_ 276 MessageCounter_HYBRID_POWERTRAI_114 0;
BA_ "GenSigTimeoutTime_EVCU2" SG_ 276 MessageCounter_HYBRID_POWERTRAI_114 0;
BA_ "GenSigTimeoutTime_BPCM" SG_ 276 CRC_HYBRID_POWERTRAIN1 0;
BA_ "GenSigTimeoutTime_SGCP" SG_ 276 CRC_HYBRID_POWERTRAIN1 0;
BA_ "GenSigTimeoutTime_MCPB" SG_ 276 CRC_HYBRID_POWERTRAIN1 0;
BA_ "GenSigTimeoutTime_MCPA" SG_ 276 CRC_HYBRID_POWERTRAIN1 0;
BA_ "GenSigTimeoutTime_IDCM" SG_ 276 CRC_HYBRID_POWERTRAIN1 0;
BA_ "GenSigTimeoutTime_EVCU2" SG_ 276 CRC_HYBRID_POWERTRAIN1 0;
BA_ "GenSigTimeoutTime_ECM" SG_ 258 LatAccelerationFailSts_BSM 0;
BA_ "GenSigTimeoutTime_BPCM" SG_ 258 LatAccelerationFailSts_BSM 0;
BA_ "GenSigTimeoutTime_SGCP" SG_ 258 LatAccelerationFailSts_BSM 0;
BA_ "GenSigTimeoutTime_IDCM" SG_ 258 LatAccelerationFailSts_BSM 0;
BA_ "GenSigTimeoutTime_EVCU2" SG_ 258 LatAccelerationFailSts_BSM 0;
BA_ "GenSigTimeoutTime_ECM" SG_ 258 LatAcceleration_BSM 0;
BA_ "GenSigTimeoutTime_BPCM" SG_ 258 LatAcceleration_BSM 0;
BA_ "GenSigStartValue" SG_ 258 LatAcceleration_BSM 4095;
BA_ "GenSigTimeoutTime_ECM" SG_ 258 LongAccelerationFailSts_BSM 0;
BA_ "GenSigTimeoutTime_BPCM" SG_ 258 LongAccelerationFailSts_BSM 0;
BA_ "GenSigTimeoutTime_SGCP" SG_ 258 LongAccelerationFailSts_BSM 0;
BA_ "GenSigTimeoutTime_IDCM" SG_ 258 LongAccelerationFailSts_BSM 0;
BA_ "GenSigTimeoutTime_EVCU2" SG_ 258 LongAccelerationFailSts_BSM 0;
BA_ "GenSigTimeoutTime_ECM" SG_ 258 LongAcceleration_BSM 0;
BA_ "GenSigTimeoutTime_BPCM" SG_ 258 LongAcceleration_BSM 0;
BA_ "GenSigStartValue" SG_ 258 LongAcceleration_BSM 4095;
BA_ "GenSigTimeoutTime_SGCP" SG_ 258 LongAcceleration_BSM 0;
BA_ "GenSigTimeoutTime_IDCM" SG_ 258 LongAcceleration_BSM 0;
BA_ "GenSigTimeoutTime_EVCU2" SG_ 258 LongAcceleration_BSM 0;
BA_ "GenSigTimeoutTime_ECM" SG_ 258 MessageCounter_BRAKE2 0;
BA_ "GenSigTimeoutTime_BPCM" SG_ 258 MessageCounter_BRAKE2 0;
BA_ "GenSigTimeoutTime_SGCP" SG_ 258 MessageCounter_BRAKE2 0;
BA_ "GenSigTimeoutTime_IDCM" SG_ 258 MessageCounter_BRAKE2 0;
BA_ "GenSigTimeoutTime_EVCU2" SG_ 258 MessageCounter_BRAKE2 0;
BA_ "GenSigTimeoutTime_ECM" SG_ 258 VehicleSpeedVSOSig 0;
BA_ "GenSigTimeoutTime_IDCM" SG_ 258 VehicleSpeedVSOSig 0;
BA_ "GenSigTimeoutTime_EVCU2" SG_ 258 VehicleSpeedVSOSig 0;
BA_ "GenSigTimeoutTime_ECM" SG_ 242 MCPA_Torque_Achieved 0;
BA_ "GenSigTimeoutTime_BPCM" SG_ 242 MCPA_Torque_Achieved 0;
BA_ "GenSigStartValue" SG_ 242 MCPA_Torque_Achieved 4096;
BA_ "GenSigTimeoutTime_SGCP" SG_ 242 MCPA_Torque_Achieved 0;
BA_ "GenSigTimeoutTime_MCPB" SG_ 242 MCPA_Torque_Achieved 0;
BA_ "GenSigTimeoutTime_MCPA" SG_ 242 MCPA_Torque_Achieved 0;
BA_ "GenSigTimeoutTime_IDCM" SG_ 242 MCPA_Torque_Achieved 0;
BA_ "GenSigTimeoutTime_ECM" SG_ 242 MCPA_TorqAchieved_AEMD_V 0;
BA_ "GenSigTimeoutTime_BPCM" SG_ 242 MCPA_TorqAchieved_AEMD_V 0;
BA_ "GenSigTimeoutTime_SGCP" SG_ 242 MCPA_TorqAchieved_AEMD_V 0;
BA_ "GenSigTimeoutTime_MCPB" SG_ 242 MCPA_TorqAchieved_AEMD_V 0;
BA_ "GenSigTimeoutTime_MCPA" SG_ 242 MCPA_TorqAchieved_AEMD_V 0;
BA_ "GenSigTimeoutTime_IDCM" SG_ 242 MCPA_TorqAchieved_AEMD_V 0;
BA_ "GenSigTimeoutTime_ECM" SG_ 242 MCPA_TorqAchieved_AEMD 0;
BA_ "GenSigTimeoutTime_BPCM" SG_ 242 MCPA_TorqAchieved_AEMD 0;
BA_ "GenSigStartValue" SG_ 242 MCPA_TorqAchieved_AEMD 4096;
BA_ "GenSigTimeoutTime_SGCP" SG_ 242 MCPA_TorqAchieved_AEMD 0;
BA_ "GenSigTimeoutTime_MCPB" SG_ 242 MCPA_TorqAchieved_AEMD 0;
BA_ "GenSigTimeoutTime_MCPA" SG_ 242 MCPA_TorqAchieved_AEMD 0;
BA_ "GenSigTimeoutTime_IDCM" SG_ 242 MCPA_TorqAchieved_AEMD 0;
BA_ "GenSigTimeoutTime_ECM" SG_ 242 MCPA_Spd_Lim 0;
BA_ "GenSigTimeoutTime_BPCM" SG_ 242 MCPA_Spd_Lim 0;
BA_ "GenSigTimeoutTime_SGCP" SG_ 242 MCPA_Spd_Lim 0;
BA_ "GenSigTimeoutTime_MCPB" SG_ 242 MCPA_Spd_Lim 0;
BA_ "GenSigTimeoutTime_MCPA" SG_ 242 MCPA_Spd_Lim 0;
BA_ "GenSigTimeoutTime_IDCM" SG_ 242 MCPA_Spd_Lim 0;
BA_ "GenSigTimeoutTime_ECM" SG_ 242 InvF_DerateReason 0;
BA_ "GenSigTimeoutTime_BPCM" SG_ 242 InvF_DerateReason 0;
BA_ "GenSigTimeoutTime_SGCP" SG_ 242 InvF_DerateReason 0;
BA_ "GenSigTimeoutTime_MCPB" SG_ 242 InvF_DerateReason 0;
BA_ "GenSigTimeoutTime_MCPA" SG_ 242 InvF_DerateReason 0;
BA_ "GenSigTimeoutTime_IDCM" SG_ 242 InvF_DerateReason 0;
BA_ "GenSigTimeoutTime_ECM" SG_ 242 CRC_PF1 0;
BA_ "GenSigTimeoutTime_SGCP" SG_ 242 CRC_PF1 0;
BA_ "GenSigTimeoutTime_MCPB" SG_ 242 CRC_PF1 0;
BA_ "GenSigTimeoutTime_MCPA" SG_ 242 CRC_PF1 0;
BA_ "GenSigTimeoutTime_IDCM" SG_ 242 CRC_PF1 0;
BA_ "GenSigTimeoutTime_ECM" SG_ 242 INVFInterlockSts 0;
BA_ "GenSigTimeoutTime_BPCM" SG_ 242 INVFInterlockSts 0;
BA_ "GenSigTimeoutTime_SGCP" SG_ 242 INVFInterlockSts 0;
BA_ "GenSigTimeoutTime_MCPB" SG_ 242 INVFInterlockSts 0;
BA_ "GenSigTimeoutTime_MCPA" SG_ 242 INVFInterlockSts 0;
BA_ "GenSigTimeoutTime_IDCM" SG_ 242 INVFInterlockSts 0;
BA_ "GenSigTimeoutTime_ECM" SG_ 242 InvF_DC_Voltage 0;
BA_ "GenSigTimeoutTime_BPCM" SG_ 242 InvF_DC_Voltage 0;
BA_ "GenSigTimeoutTime_SGCP" SG_ 242 InvF_DC_Voltage 0;
BA_ "GenSigTimeoutTime_MCPB" SG_ 242 InvF_DC_Voltage 0;
BA_ "GenSigTimeoutTime_MCPA" SG_ 242 InvF_DC_Voltage 0;
BA_ "GenSigTimeoutTime_IDCM" SG_ 242 InvF_DC_Voltage 0;
BA_ "GenSigTimeoutTime_ECM" SG_ 242 MC_PF1 0;
BA_ "GenSigTimeoutTime_SGCP" SG_ 242 MC_PF1 0;
BA_ "GenSigTimeoutTime_MCPB" SG_ 242 MC_PF1 0;
BA_ "GenSigTimeoutTime_MCPA" SG_ 242 MC_PF1 0;
BA_ "GenSigTimeoutTime_IDCM" SG_ 242 MC_PF1 0;
BA_ "GenSigTimeoutTime_ECM" SG_ 242 MCPA_3PS_Pos 0;
BA_ "GenSigTimeoutTime_BPCM" SG_ 242 MCPA_3PS_Pos 0;
BA_ "GenSigTimeoutTime_SGCP" SG_ 242 MCPA_3PS_Pos 0;
BA_ "GenSigTimeoutTime_MCPB" SG_ 242 MCPA_3PS_Pos 0;
BA_ "GenSigTimeoutTime_MCPA" SG_ 242 MCPA_3PS_Pos 0;
BA_ "GenSigTimeoutTime_IDCM" SG_ 242 MCPA_3PS_Pos 0;
BA_ "GenSigTimeoutTime_ECM" SG_ 242 InvF_CoolantTemp 0;
BA_ "GenSigTimeoutTime_BPCM" SG_ 242 InvF_CoolantTemp 0;
BA_ "GenSigTimeoutTime_SGCP" SG_ 242 InvF_CoolantTemp 0;
BA_ "GenSigTimeoutTime_MCPB" SG_ 242 InvF_CoolantTemp 0;
BA_ "GenSigTimeoutTime_MCPA" SG_ 242 InvF_CoolantTemp 0;
BA_ "GenSigTimeoutTime_IDCM" SG_ 242 InvF_CoolantTemp 0;
BA_ "GenSigTimeoutTime_ECM" SG_ 242 MCPA_Torque_Achieved_V 0;
BA_ "GenSigTimeoutTime_BPCM" SG_ 242 MCPA_Torque_Achieved_V 0;
BA_ "GenSigTimeoutTime_SGCP" SG_ 242 MCPA_Torque_Achieved_V 0;
BA_ "GenSigTimeoutTime_MCPB" SG_ 242 MCPA_Torque_Achieved_V 0;
BA_ "GenSigTimeoutTime_MCPA" SG_ 242 MCPA_Torque_Achieved_V 0;
BA_ "GenSigTimeoutTime_IDCM" SG_ 242 MCPA_Torque_Achieved_V 0;
BA_ "GenSigTimeoutTime_ECM" SG_ 242 MCPA_SPT_Stat 0;
BA_ "GenSigTimeoutTime_BPCM" SG_ 242 MCPA_SPT_Stat 0;
BA_ "GenSigTimeoutTime_SGCP" SG_ 242 MCPA_SPT_Stat 0;
BA_ "GenSigTimeoutTime_MCPB" SG_ 242 MCPA_SPT_Stat 0;
BA_ "GenSigTimeoutTime_MCPA" SG_ 242 MCPA_SPT_Stat 0;
BA_ "GenSigTimeoutTime_IDCM" SG_ 242 MCPA_SPT_Stat 0;
BA_ "GenSigTimeoutTime_ECM" SG_ 242 MCPA_AccelRaw 0;
BA_ "GenSigTimeoutTime_BPCM" SG_ 242 MCPA_AccelRaw 0;
BA_ "GenSigTimeoutTime_SGCP" SG_ 242 MCPA_AccelRaw 0;
BA_ "GenSigTimeoutTime_MCPB" SG_ 242 MCPA_AccelRaw 0;
BA_ "GenSigTimeoutTime_MCPA" SG_ 242 MCPA_AccelRaw 0;
BA_ "GenSigTimeoutTime_IDCM" SG_ 242 MCPA_AccelRaw 0;
BA_ "GenSigTimeoutTime_ECM" SG_ 242 MCPA_6SO_Status 0;
BA_ "GenSigTimeoutTime_BPCM" SG_ 242 MCPA_6SO_Status 0;
BA_ "GenSigTimeoutTime_SGCP" SG_ 242 MCPA_6SO_Status 0;
BA_ "GenSigTimeoutTime_MCPB" SG_ 242 MCPA_6SO_Status 0;
BA_ "GenSigTimeoutTime_MCPA" SG_ 242 MCPA_6SO_Status 0;
BA_ "GenSigTimeoutTime_IDCM" SG_ 242 MCPA_6SO_Status 0;
BA_ "GenSigTimeoutTime_ECM" SG_ 242 MCPA_RPM_V 0;
BA_ "GenSigTimeoutTime_BPCM" SG_ 242 MCPA_RPM_V 0;
BA_ "GenSigTimeoutTime_SGCP" SG_ 242 MCPA_RPM_V 0;
BA_ "GenSigTimeoutTime_MCPB" SG_ 242 MCPA_RPM_V 0;
BA_ "GenSigTimeoutTime_MCPA" SG_ 242 MCPA_RPM_V 0;
BA_ "GenSigTimeoutTime_IDCM" SG_ 242 MCPA_RPM_V 0;
BA_ "GenSigTimeoutTime_ECM" SG_ 242 MCPA_RPM 0;
BA_ "GenSigTimeoutTime_BPCM" SG_ 242 MCPA_RPM 0;
BA_ "GenSigStartValue" SG_ 242 MCPA_RPM 32768;
BA_ "GenSigTimeoutTime_SGCP" SG_ 242 MCPA_RPM 0;
BA_ "GenSigTimeoutTime_MCPB" SG_ 242 MCPA_RPM 0;
BA_ "GenSigTimeoutTime_MCPA" SG_ 242 MCPA_RPM 0;
BA_ "GenSigTimeoutTime_IDCM" SG_ 242 MCPA_RPM 0;
BA_ "GenSigTimeoutTime_MCPB" SG_ 242 MCPA_MtrMinCpbltyTrq 0;
BA_ "GenSigTimeoutTime_MCPA" SG_ 242 MCPA_MtrMinCpbltyTrq 0;
BA_ "GenSigTimeoutTime_IDCM" SG_ 242 MCPA_MtrMinCpbltyTrq 0;
BA_ "GenSigTimeoutTime_ECM" SG_ 242 MCPA_MtrMinCpbltyTrq 0;
BA_ "GenSigTimeoutTime_BPCM" SG_ 242 MCPA_MtrMinCpbltyTrq 0;
BA_ "GenSigStartValue" SG_ 242 MCPA_MtrMinCpbltyTrq 4096;
BA_ "GenSigTimeoutTime_SGCP" SG_ 242 MCPA_MtrMinCpbltyTrq 0;
BA_ "GenSigTimeoutTime_ECM" SG_ 242 MCPA_MtrMaxCpbltyTrq 0;
BA_ "GenSigTimeoutTime_BPCM" SG_ 242 MCPA_MtrMaxCpbltyTrq 0;
BA_ "GenSigStartValue" SG_ 242 MCPA_MtrMaxCpbltyTrq 4096;
BA_ "GenSigTimeoutTime_SGCP" SG_ 242 MCPA_MtrMaxCpbltyTrq 0;
BA_ "GenSigTimeoutTime_MCPB" SG_ 242 MCPA_MtrMaxCpbltyTrq 0;
BA_ "GenSigTimeoutTime_MCPA" SG_ 242 MCPA_MtrMaxCpbltyTrq 0;
BA_ "GenSigTimeoutTime_IDCM" SG_ 242 MCPA_MtrMaxCpbltyTrq 0;
BA_ "GenSigTimeoutTime_ECM" SG_ 242 MCPA_MtrIndex 0;
BA_ "GenSigTimeoutTime_BPCM" SG_ 242 MCPA_MtrIndex 0;
BA_ "GenSigTimeoutTime_SGCP" SG_ 242 MCPA_MtrIndex 0;
BA_ "GenSigTimeoutTime_MCPB" SG_ 242 MCPA_MtrIndex 0;
BA_ "GenSigTimeoutTime_MCPA" SG_ 242 MCPA_MtrIndex 0;
BA_ "GenSigTimeoutTime_IDCM" SG_ 242 MCPA_MtrIndex 0;
BA_ "GenSigTimeoutTime_ECM" SG_ 242 MCPA_MinTorq 0;
BA_ "GenSigTimeoutTime_BPCM" SG_ 242 MCPA_MinTorq 0;
BA_ "GenSigStartValue" SG_ 242 MCPA_MinTorq 4096;
BA_ "GenSigTimeoutTime_SGCP" SG_ 242 MCPA_MinTorq 0;
BA_ "GenSigTimeoutTime_MCPB" SG_ 242 MCPA_MinTorq 0;
BA_ "GenSigTimeoutTime_MCPA" SG_ 242 MCPA_MinTorq 0;
BA_ "GenSigTimeoutTime_IDCM" SG_ 242 MCPA_MinTorq 0;
BA_ "GenSigTimeoutTime_ECM" SG_ 242 MCPA_MaxTorq 0;
BA_ "GenSigTimeoutTime_BPCM" SG_ 242 MCPA_MaxTorq 0;
BA_ "GenSigStartValue" SG_ 242 MCPA_MaxTorq 4096;
BA_ "GenSigTimeoutTime_SGCP" SG_ 242 MCPA_MaxTorq 0;
BA_ "GenSigTimeoutTime_MCPB" SG_ 242 MCPA_MaxTorq 0;
BA_ "GenSigTimeoutTime_MCPA" SG_ 242 MCPA_MaxTorq 0;
BA_ "GenSigTimeoutTime_IDCM" SG_ 242 MCPA_MaxTorq 0;
BA_ "GenSigTimeoutTime_ECM" SG_ 242 MCPA_Invrtr_State 0;
BA_ "GenSigTimeoutTime_BPCM" SG_ 242 MCPA_Invrtr_State 0;
BA_ "GenSigTimeoutTime_SGCP" SG_ 242 MCPA_Invrtr_State 0;
BA_ "GenSigTimeoutTime_MCPB" SG_ 242 MCPA_Invrtr_State 0;
BA_ "GenSigTimeoutTime_MCPA" SG_ 242 MCPA_Invrtr_State 0;
BA_ "GenSigTimeoutTime_IDCM" SG_ 242 MCPA_Invrtr_State 0;
BA_ "GenSigTimeoutTime_ECM" SG_ 242 MCPA_HV_CnctrOpn_Req 0;
BA_ "GenSigTimeoutTime_BPCM" SG_ 242 MCPA_HV_CnctrOpn_Req 0;
BA_ "GenSigTimeoutTime_SGCP" SG_ 242 MCPA_HV_CnctrOpn_Req 0;
BA_ "GenSigTimeoutTime_MCPB" SG_ 242 MCPA_HV_CnctrOpn_Req 0;
BA_ "GenSigTimeoutTime_MCPA" SG_ 242 MCPA_HV_CnctrOpn_Req 0;
BA_ "GenSigTimeoutTime_IDCM" SG_ 242 MCPA_HV_CnctrOpn_Req 0;
BA_ "GenSigTimeoutTime_ECM" SG_ 242 MCPA_Dschrge_Status 0;
BA_ "GenSigTimeoutTime_BPCM" SG_ 242 MCPA_Dschrge_Status 0;
BA_ "GenSigTimeoutTime_SGCP" SG_ 242 MCPA_Dschrge_Status 0;
BA_ "GenSigTimeoutTime_MCPB" SG_ 242 MCPA_Dschrge_Status 0;
BA_ "GenSigTimeoutTime_MCPA" SG_ 242 MCPA_Dschrge_Status 0;
BA_ "GenSigTimeoutTime_IDCM" SG_ 242 MCPA_Dschrge_Status 0;
BA_ "GenSigTimeoutTime_ECM" SG_ 242 MCPA_DeratingFactor 0;
BA_ "GenSigTimeoutTime_BPCM" SG_ 242 MCPA_DeratingFactor 0;
BA_ "GenSigTimeoutTime_SGCP" SG_ 242 MCPA_DeratingFactor 0;
BA_ "GenSigTimeoutTime_MCPB" SG_ 242 MCPA_DeratingFactor 0;
BA_ "GenSigTimeoutTime_MCPA" SG_ 242 MCPA_DeratingFactor 0;
BA_ "GenSigTimeoutTime_IDCM" SG_ 242 MCPA_DeratingFactor 0;
BA_ "GenSigTimeoutTime_ECM" SG_ 242 MCPA_DC_Volt_V 0;
BA_ "GenSigTimeoutTime_BPCM" SG_ 242 MCPA_DC_Volt_V 0;
BA_ "GenSigTimeoutTime_SGCP" SG_ 242 MCPA_DC_Volt_V 0;
BA_ "GenSigTimeoutTime_MCPB" SG_ 242 MCPA_DC_Volt_V 0;
BA_ "GenSigTimeoutTime_MCPA" SG_ 242 MCPA_DC_Volt_V 0;
BA_ "GenSigTimeoutTime_IDCM" SG_ 242 MCPA_DC_Volt_V 0;
BA_ "GenSigTimeoutTime_ECM" SG_ 242 MCPA_DC_Current_V 0;
BA_ "GenSigTimeoutTime_BPCM" SG_ 242 MCPA_DC_Current_V 0;
BA_ "GenSigTimeoutTime_SGCP" SG_ 242 MCPA_DC_Current_V 0;
BA_ "GenSigTimeoutTime_MCPB" SG_ 242 MCPA_DC_Current_V 0;
BA_ "GenSigTimeoutTime_MCPA" SG_ 242 MCPA_DC_Current_V 0;
BA_ "GenSigTimeoutTime_IDCM" SG_ 242 MCPA_DC_Current_V 0;
BA_ "GenSigTimeoutTime_ECM" SG_ 242 MCPA_DC_Current 0;
BA_ "GenSigStartValue" SG_ 242 MCPA_DC_Current 16384;
BA_ "GenSigTimeoutTime_SGCP" SG_ 242 MCPA_DC_Current 0;
BA_ "GenSigTimeoutTime_MCPB" SG_ 242 MCPA_DC_Current 0;
BA_ "GenSigTimeoutTime_MCPA" SG_ 242 MCPA_DC_Current 0;
BA_ "GenSigTimeoutTime_IDCM" SG_ 242 MCPA_DC_Current 0;
BA_ "GenSigTimeoutTime_ECM" SG_ 242 MCPA_CpbltySpdDivVolt 0;
BA_ "GenSigTimeoutTime_BPCM" SG_ 242 MCPA_CpbltySpdDivVolt 0;
BA_ "GenSigTimeoutTime_SGCP" SG_ 242 MCPA_CpbltySpdDivVolt 0;
BA_ "GenSigTimeoutTime_MCPB" SG_ 242 MCPA_CpbltySpdDivVolt 0;
BA_ "GenSigTimeoutTime_MCPA" SG_ 242 MCPA_CpbltySpdDivVolt 0;
BA_ "GenSigTimeoutTime_IDCM" SG_ 242 MCPA_CpbltySpdDivVolt 0;
BA_ "GenSigTimeoutTime_ECM" SG_ 242 MCPA_AccelRawV 0;
BA_ "GenSigTimeoutTime_BPCM" SG_ 242 MCPA_AccelRawV 0;
BA_ "GenSigTimeoutTime_SGCP" SG_ 242 MCPA_AccelRawV 0;
BA_ "GenSigTimeoutTime_MCPB" SG_ 242 MCPA_AccelRawV 0;
BA_ "GenSigTimeoutTime_MCPA" SG_ 242 MCPA_AccelRawV 0;
BA_ "GenSigTimeoutTime_IDCM" SG_ 242 MCPA_AccelRawV 0;
BA_ "GenSigTimeoutTime_ECM" SG_ 271 MessageCounter_ENGINE_HYBD_FD_1 0;
BA_ "GenSigTimeoutTime_BPCM" SG_ 271 MessageCounter_ENGINE_HYBD_FD_1 0;
BA_ "GenSigTimeoutTime_SGCP" SG_ 271 MessageCounter_ENGINE_HYBD_FD_1 0;
BA_ "GenSigTimeoutTime_MCPB" SG_ 271 MessageCounter_ENGINE_HYBD_FD_1 0;
BA_ "GenSigTimeoutTime_MCPA" SG_ 271 MessageCounter_ENGINE_HYBD_FD_1 0;
BA_ "GenSigTimeoutTime_IDCM" SG_ 271 MessageCounter_ENGINE_HYBD_FD_1 0;
BA_ "GenSigTimeoutTime_SGCP" SG_ 271 CRC_ENGINE_HYBD_FD_1 0;
BA_ "GenSigTimeoutTime_MCPB" SG_ 271 CRC_ENGINE_HYBD_FD_1 0;
BA_ "GenSigTimeoutTime_MCPA" SG_ 271 CRC_ENGINE_HYBD_FD_1 0;
BA_ "GenSigTimeoutTime_IDCM" SG_ 271 CRC_ENGINE_HYBD_FD_1 0;
BA_ "GenSigTimeoutTime_ECM" SG_ 271 CRC_ENGINE_HYBD_FD_1 0;
BA_ "GenSigTimeoutTime_BPCM" SG_ 271 CRC_ENGINE_HYBD_FD_1 0;
BA_ "GenSigTimeoutTime_ECM" SG_ 271 RedSpkAuthorityAvbl 0;
BA_ "GenSigTimeoutTime_BPCM" SG_ 271 RedSpkAuthorityAvbl 0;
BA_ "GenSigTimeoutTime_SGCP" SG_ 271 RedSpkAuthorityAvbl 0;
BA_ "GenSigTimeoutTime_MCPB" SG_ 271 RedSpkAuthorityAvbl 0;
BA_ "GenSigTimeoutTime_MCPA" SG_ 271 RedSpkAuthorityAvbl 0;
BA_ "GenSigTimeoutTime_IDCM" SG_ 271 RedSpkAuthorityAvbl 0;
BA_ "GenSigTimeoutTime_ECM" SG_ 271 EngMinSparkNomCurrAirTorqCap 0;
BA_ "GenSigTimeoutTime_BPCM" SG_ 271 EngMinSparkNomCurrAirTorqCap 0;
BA_ "GenSigTimeoutTime_SGCP" SG_ 271 EngMinSparkNomCurrAirTorqCap 0;
BA_ "GenSigTimeoutTime_MCPB" SG_ 271 EngMinSparkNomCurrAirTorqCap 0;
BA_ "GenSigTimeoutTime_MCPA" SG_ 271 EngMinSparkNomCurrAirTorqCap 0;
BA_ "GenSigTimeoutTime_IDCM" SG_ 271 EngMinSparkNomCurrAirTorqCap 0;
BA_ "GenSigTimeoutTime_ECM" SG_ 1035 MessageCounter_ENGINE_HYBD_FD_3 0;
BA_ "GenSigTimeoutTime_BPCM" SG_ 1035 MessageCounter_ENGINE_HYBD_FD_3 0;
BA_ "GenSigTimeoutTime_SGCP" SG_ 1035 MessageCounter_ENGINE_HYBD_FD_3 0;
BA_ "GenSigTimeoutTime_MCPB" SG_ 1035 MessageCounter_ENGINE_HYBD_FD_3 0;
BA_ "GenSigTimeoutTime_MCPA" SG_ 1035 MessageCounter_ENGINE_HYBD_FD_3 0;
BA_ "GenSigTimeoutTime_IDCM" SG_ 1035 MessageCounter_ENGINE_HYBD_FD_3 0;
BA_ "GenSigTimeoutTime_ECM" SG_ 1035 CRC_ENGINE_HYBD_FD_3 0;
BA_ "GenSigTimeoutTime_BPCM" SG_ 1035 CRC_ENGINE_HYBD_FD_3 0;
BA_ "GenSigTimeoutTime_SGCP" SG_ 1035 CRC_ENGINE_HYBD_FD_3 0;
BA_ "GenSigTimeoutTime_MCPB" SG_ 1035 CRC_ENGINE_HYBD_FD_3 0;
BA_ "GenSigTimeoutTime_MCPA" SG_ 1035 CRC_ENGINE_HYBD_FD_3 0;
BA_ "GenSigTimeoutTime_IDCM" SG_ 1035 CRC_ENGINE_HYBD_FD_3 0;
BA_ "GenSigTimeoutTime_ECM" SG_ 1328 CRC_ENGINE_HYBD_FD_4 0;
BA_ "GenSigTimeoutTime_BPCM" SG_ 1328 CRC_ENGINE_HYBD_FD_4 0;
BA_ "GenSigTimeoutTime_SGCP" SG_ 1328 CRC_ENGINE_HYBD_FD_4 0;
BA_ "GenSigTimeoutTime_MCPB" SG_ 1328 CRC_ENGINE_HYBD_FD_4 0;
BA_ "GenSigTimeoutTime_MCPA" SG_ 1328 CRC_ENGINE_HYBD_FD_4 0;
BA_ "GenSigTimeoutTime_IDCM" SG_ 1328 CRC_ENGINE_HYBD_FD_4 0;
BA_ "GenSigTimeoutTime_ECM" SG_ 1328 MessageCounter_ENGINE_HYBD_FD_4 0;
BA_ "GenSigTimeoutTime_BPCM" SG_ 1328 MessageCounter_ENGINE_HYBD_FD_4 0;
BA_ "GenSigTimeoutTime_SGCP" SG_ 1328 MessageCounter_ENGINE_HYBD_FD_4 0;
BA_ "GenSigTimeoutTime_MCPB" SG_ 1328 MessageCounter_ENGINE_HYBD_FD_4 0;
BA_ "GenSigTimeoutTime_MCPA" SG_ 1328 MessageCounter_ENGINE_HYBD_FD_4 0;
BA_ "GenSigTimeoutTime_ECM" SG_ 2654486598 CBV_bit0_RepeatMessageRequestBit_1E384046 0;
BA_ "GenSigTimeoutTime_BPCM" SG_ 2654486598 CBV_bit0_RepeatMessageRequestBit_1E384046 0;
BA_ "GenSigTimeoutTime_SGCP" SG_ 2654486598 CBV_bit0_RepeatMessageRequestBit_1E384046 0;
BA_ "GenSigTimeoutTime_MCPB" SG_ 2654486598 CBV_bit0_RepeatMessageRequestBit_1E384046 0;
BA_ "GenSigTimeoutTime_MCPA" SG_ 2654486598 CBV_bit0_RepeatMessageRequestBit_1E384046 0;
BA_ "GenSigTimeoutTime_IDCM" SG_ 2654486598 CBV_bit0_RepeatMessageRequestBit_1E384046 0;
BA_ "GenSigTimeoutTime_EVCU2" SG_ 2654486598 CBV_bit0_RepeatMessageRequestBit_1E384046 0;
BA_ "GenSigTimeoutTime_ECM" SG_ 2654486598 SourceNodeIdentifier_1E384046 0;
BA_ "GenSigTimeoutTime_BPCM" SG_ 2654486598 SourceNodeIdentifier_1E384046 0;
BA_ "GenSigTimeoutTime_SGCP" SG_ 2654486598 SourceNodeIdentifier_1E384046 0;
BA_ "GenSigTimeoutTime_MCPB" SG_ 2654486598 SourceNodeIdentifier_1E384046 0;
BA_ "GenSigTimeoutTime_MCPA" SG_ 2654486598 SourceNodeIdentifier_1E384046 0;
BA_ "GenSigTimeoutTime_IDCM" SG_ 2654486598 SourceNodeIdentifier_1E384046 0;
BA_ "GenSigTimeoutTime_EVCU2" SG_ 2654486598 SourceNodeIdentifier_1E384046 0;
BA_ "GenSigTimeoutTime_ECM" SG_ 2654486598 CBV_bit5_1E384046 0;
BA_ "GenSigTimeoutTime_BPCM" SG_ 2654486598 CBV_bit5_1E384046 0;
BA_ "GenSigTimeoutTime_SGCP" SG_ 2654486598 CBV_bit5_1E384046 0;
BA_ "GenSigTimeoutTime_MCPB" SG_ 2654486598 CBV_bit5_1E384046 0;
BA_ "GenSigTimeoutTime_MCPA" SG_ 2654486598 CBV_bit5_1E384046 0;
BA_ "GenSigTimeoutTime_IDCM" SG_ 2654486598 CBV_bit5_1E384046 0;
BA_ "GenSigTimeoutTime_EVCU2" SG_ 2654486598 CBV_bit5_1E384046 0;
BA_ "GenSigTimeoutTime_ECM" SG_ 2654486598 CBV_bit7_1E384046 0;
BA_ "GenSigTimeoutTime_BPCM" SG_ 2654486598 CBV_bit7_1E384046 0;
BA_ "GenSigTimeoutTime_SGCP" SG_ 2654486598 CBV_bit7_1E384046 0;
BA_ "GenSigTimeoutTime_MCPB" SG_ 2654486598 CBV_bit7_1E384046 0;
BA_ "GenSigTimeoutTime_MCPA" SG_ 2654486598 CBV_bit7_1E384046 0;
BA_ "GenSigTimeoutTime_IDCM" SG_ 2654486598 CBV_bit7_1E384046 0;
BA_ "GenSigTimeoutTime_EVCU2" SG_ 2654486598 CBV_bit7_1E384046 0;
BA_ "GenSigTimeoutTime_ECM" SG_ 2654486598 CBV_bit1_1E384046 0;
BA_ "GenSigTimeoutTime_BPCM" SG_ 2654486598 CBV_bit1_1E384046 0;
BA_ "GenSigTimeoutTime_SGCP" SG_ 2654486598 CBV_bit1_1E384046 0;
BA_ "GenSigTimeoutTime_MCPB" SG_ 2654486598 CBV_bit1_1E384046 0;
BA_ "GenSigTimeoutTime_MCPA" SG_ 2654486598 CBV_bit1_1E384046 0;
BA_ "GenSigTimeoutTime_IDCM" SG_ 2654486598 CBV_bit1_1E384046 0;
BA_ "GenSigTimeoutTime_EVCU2" SG_ 2654486598 CBV_bit1_1E384046 0;
BA_ "GenSigTimeoutTime_ECM" SG_ 2654486598 CBV_bit2_1E384046 0;
BA_ "GenSigTimeoutTime_BPCM" SG_ 2654486598 CBV_bit2_1E384046 0;
BA_ "GenSigTimeoutTime_SGCP" SG_ 2654486598 CBV_bit2_1E384046 0;
BA_ "GenSigTimeoutTime_MCPB" SG_ 2654486598 CBV_bit2_1E384046 0;
BA_ "GenSigTimeoutTime_MCPA" SG_ 2654486598 CBV_bit2_1E384046 0;
BA_ "GenSigTimeoutTime_IDCM" SG_ 2654486598 CBV_bit2_1E384046 0;
BA_ "GenSigTimeoutTime_EVCU2" SG_ 2654486598 CBV_bit2_1E384046 0;
BA_ "GenSigTimeoutTime_ECM" SG_ 2654486598 CBV_bit6_PartialNtwInfBit_1E384046 0;
BA_ "GenSigTimeoutTime_BPCM" SG_ 2654486598 CBV_bit6_PartialNtwInfBit_1E384046 0;
BA_ "GenSigTimeoutTime_SGCP" SG_ 2654486598 CBV_bit6_PartialNtwInfBit_1E384046 0;
BA_ "GenSigTimeoutTime_MCPB" SG_ 2654486598 CBV_bit6_PartialNtwInfBit_1E384046 0;
BA_ "GenSigTimeoutTime_MCPA" SG_ 2654486598 CBV_bit6_PartialNtwInfBit_1E384046 0;
BA_ "GenSigTimeoutTime_IDCM" SG_ 2654486598 CBV_bit6_PartialNtwInfBit_1E384046 0;
BA_ "GenSigTimeoutTime_EVCU2" SG_ 2654486598 CBV_bit6_PartialNtwInfBit_1E384046 0;
BA_ "GenSigTimeoutTime_SGCP" SG_ 2654486598 CBV_bit3_NMCoordinatorBit_1E384046 0;
BA_ "GenSigTimeoutTime_MCPB" SG_ 2654486598 CBV_bit3_NMCoordinatorBit_1E384046 0;
BA_ "GenSigTimeoutTime_MCPA" SG_ 2654486598 CBV_bit3_NMCoordinatorBit_1E384046 0;
BA_ "GenSigTimeoutTime_IDCM" SG_ 2654486598 CBV_bit3_NMCoordinatorBit_1E384046 0;
BA_ "GenSigTimeoutTime_EVCU2" SG_ 2654486598 CBV_bit3_NMCoordinatorBit_1E384046 0;
BA_ "GenSigTimeoutTime_ECM" SG_ 2654486598 CBV_bit3_NMCoordinatorBit_1E384046 0;
BA_ "GenSigTimeoutTime_BPCM" SG_ 2654486598 CBV_bit3_NMCoordinatorBit_1E384046 0;
BA_ "GenSigTimeoutTime_ECM" SG_ 2654486598 CBV_bit4_ActiveWakeupBit_1E384046 0;
BA_ "GenSigTimeoutTime_BPCM" SG_ 2654486598 CBV_bit4_ActiveWakeupBit_1E384046 0;
BA_ "GenSigTimeoutTime_SGCP" SG_ 2654486598 CBV_bit4_ActiveWakeupBit_1E384046 0;
BA_ "GenSigTimeoutTime_MCPB" SG_ 2654486598 CBV_bit4_ActiveWakeupBit_1E384046 0;
BA_ "GenSigTimeoutTime_MCPA" SG_ 2654486598 CBV_bit4_ActiveWakeupBit_1E384046 0;
BA_ "GenSigTimeoutTime_IDCM" SG_ 2654486598 CBV_bit4_ActiveWakeupBit_1E384046 0;
BA_ "GenSigTimeoutTime_EVCU2" SG_ 2654486598 CBV_bit4_ActiveWakeupBit_1E384046 0;
BA_ "GenSigTimeoutTime_ECM" SG_ 1034 HVBatSleepTime 0;
BA_ "GenSigTimeoutTime_BPCM" SG_ 1034 HVBatSleepTime 0;
BA_ "GenSigTimeoutTime_SGCP" SG_ 1034 HVBatSleepTime 0;
BA_ "GenSigTimeoutTime_MCPB" SG_ 1034 HVBatSleepTime 0;
BA_ "GenSigTimeoutTime_MCPA" SG_ 1034 HVBatSleepTime 0;
BA_ "GenSigTimeoutTime_IDCM" SG_ 1034 HVBatSleepTime 0;
BA_ "GenSigTimeoutTime_BPCM" SG_ 1033 HCP_HoodAjar 0;
BA_ "GenSigTimeoutTime_SGCP" SG_ 1033 HCP_HoodAjar 0;
BA_ "GenSigTimeoutTime_MCPB" SG_ 1033 HCP_HoodAjar 0;
BA_ "GenSigTimeoutTime_MCPA" SG_ 1033 HCP_HoodAjar 0;
BA_ "GenSigTimeoutTime_IDCM" SG_ 1033 HCP_HoodAjar 0;
BA_ "GenSigTimeoutTime_EVCU2" SG_ 1033 HCP_HoodAjar 0;
BA_ "GenSigTimeoutTime_BPCM" SG_ 1033 HEV_HybPwrtrnRdcdPerfCmnd 0;
BA_ "GenSigTimeoutTime_SGCP" SG_ 1033 HEV_HybPwrtrnRdcdPerfCmnd 0;
BA_ "GenSigTimeoutTime_MCPB" SG_ 1033 HEV_HybPwrtrnRdcdPerfCmnd 0;
BA_ "GenSigTimeoutTime_MCPA" SG_ 1033 HEV_HybPwrtrnRdcdPerfCmnd 0;
BA_ "GenSigTimeoutTime_IDCM" SG_ 1033 HEV_HybPwrtrnRdcdPerfCmnd 0;
BA_ "GenSigTimeoutTime_EVCU2" SG_ 1033 HEV_HybPwrtrnRdcdPerfCmnd 0;
BA_ "GenSigTimeoutTime_BPCM" SG_ 1033 HCPMaxEngRPM 0;
BA_ "GenSigStartValue" SG_ 1033 HCPMaxEngRPM 255;
BA_ "GenSigTimeoutTime_SGCP" SG_ 1033 HCPMaxEngRPM 0;
BA_ "GenSigTimeoutTime_MCPB" SG_ 1033 HCPMaxEngRPM 0;
BA_ "GenSigTimeoutTime_MCPA" SG_ 1033 HCPMaxEngRPM 0;
BA_ "GenSigTimeoutTime_IDCM" SG_ 1033 HCPMaxEngRPM 0;
BA_ "GenSigTimeoutTime_EVCU2" SG_ 1033 HCPMaxEngRPM 0;
BA_ "GenSigTimeoutTime_BPCM" SG_ 1033 CRC_HYBRID_POWERTRAIN5 0;
BA_ "GenSigTimeoutTime_SGCP" SG_ 1033 CRC_HYBRID_POWERTRAIN5 0;
BA_ "GenSigTimeoutTime_MCPB" SG_ 1033 CRC_HYBRID_POWERTRAIN5 0;
BA_ "GenSigTimeoutTime_MCPA" SG_ 1033 CRC_HYBRID_POWERTRAIN5 0;
BA_ "GenSigTimeoutTime_IDCM" SG_ 1033 CRC_HYBRID_POWERTRAIN5 0;
BA_ "GenSigTimeoutTime_EVCU2" SG_ 1033 CRC_HYBRID_POWERTRAIN5 0;
BA_ "GenSigTimeoutTime_BPCM" SG_ 1033 MessageCounter_HYBRID_POWERTRAI_409 0;
BA_ "SystemSignalLongSymbol" SG_ 1033 MessageCounter_HYBRID_POWERTRAI_409 "MessageCounter_HYBRID_POWERTRAIN5";
BA_ "GenSigTimeoutTime_SGCP" SG_ 1033 MessageCounter_HYBRID_POWERTRAI_409 0;
BA_ "GenSigTimeoutTime_MCPB" SG_ 1033 MessageCounter_HYBRID_POWERTRAI_409 0;
BA_ "GenSigTimeoutTime_MCPA" SG_ 1033 MessageCounter_HYBRID_POWERTRAI_409 0;
BA_ "GenSigTimeoutTime_IDCM" SG_ 1033 MessageCounter_HYBRID_POWERTRAI_409 0;
BA_ "GenSigTimeoutTime_EVCU2" SG_ 1033 MessageCounter_HYBRID_POWERTRAI_409 0;
BA_ "GenSigTimeoutTime_BPCM" SG_ 1033 IdleCLoopTrq 0;
BA_ "GenSigStartValue" SG_ 1033 IdleCLoopTrq 511;
BA_ "GenSigTimeoutTime_SGCP" SG_ 1033 IdleCLoopTrq 0;
BA_ "GenSigTimeoutTime_MCPB" SG_ 1033 IdleCLoopTrq 0;
BA_ "GenSigTimeoutTime_MCPA" SG_ 1033 IdleCLoopTrq 0;
BA_ "GenSigTimeoutTime_IDCM" SG_ 1033 IdleCLoopTrq 0;
BA_ "GenSigTimeoutTime_EVCU2" SG_ 1033 IdleCLoopTrq 0;
BA_ "GenSigTimeoutTime_SGCP" SG_ 267 WU_Timer_Value 0;
BA_ "GenSigTimeoutTime_EVCU2" SG_ 267 WU_Timer_Value 0;
BA_ "GenSigTimeoutTime_ECM" SG_ 267 WU_Timer_Value 0;
BA_ "GenSigTimeoutTime_ECM" SG_ 267 PerWakeUp_Diag 0;
BA_ "GenSigTimeoutTime_SGCP" SG_ 267 PerWakeUp_Diag 0;
BA_ "GenSigTimeoutTime_EVCU2" SG_ 267 PerWakeUp_Diag 0;
BA_ "GenSigTimeoutTime_ECM" SG_ 1032 EOPA_OIL_TEMP 0;
BA_ "GenSigTimeoutTime_BPCM" SG_ 1032 EOPA_OIL_TEMP 0;
BA_ "GenSigTimeoutTime_SGCP" SG_ 1032 EOPA_OIL_TEMP 0;
BA_ "GenSigTimeoutTime_MCPB" SG_ 1032 EOPA_OIL_TEMP 0;
BA_ "GenSigTimeoutTime_SGCP" SG_ 1032 EOPA_OIL_FlwRate 0;
BA_ "GenSigTimeoutTime_MCPB" SG_ 1032 EOPA_OIL_FlwRate 0;
BA_ "GenSigTimeoutTime_IDCM" SG_ 1032 EOPA_OIL_FlwRate 0;
BA_ "GenSigTimeoutTime_EVCU2" SG_ 1032 EOPA_OIL_FlwRate 0;
BA_ "GenSigTimeoutTime_ECM" SG_ 1032 EOPA_OIL_FlwRate 0;
BA_ "GenSigTimeoutTime_BPCM" SG_ 1032 EOPA_OIL_FlwRate 0;
BA_ "GenSigTimeoutTime_ECM" SG_ 1155 ESCFailSts 0;
BA_ "GenSigTimeoutTime_BPCM" SG_ 1155 ESCFailSts 0;
BA_ "GenSigSendType" SG_ 1155 ESCFailSts 3;
BA_ "GenSigTimeoutTime_SGCP" SG_ 1155 ESCFailSts 0;
BA_ "GenSigTimeoutTime_MCPA" SG_ 1155 ESCFailSts 0;
BA_ "GenSigTimeoutTime_IDCM" SG_ 1155 ESCFailSts 0;
BA_ "GenSigTimeoutTime_EVCU2" SG_ 1155 ESCFailSts 0;
BA_ "GenSigTimeoutTime_ECM" SG_ 1155 ABSFailSts 0;
BA_ "GenSigTimeoutTime_BPCM" SG_ 1155 ABSFailSts 0;
BA_ "GenSigSendType" SG_ 1155 ABSFailSts 3;
BA_ "GenSigTimeoutTime_SGCP" SG_ 1155 ABSFailSts 0;
BA_ "GenSigTimeoutTime_MCPA" SG_ 1155 ABSFailSts 0;
BA_ "GenSigTimeoutTime_IDCM" SG_ 1155 ABSFailSts 0;
BA_ "GenSigTimeoutTime_EVCU2" SG_ 1155 ABSFailSts 0;
BA_ "GenSigTimeoutTime_ECM" SG_ 609 EPBSts 0;
BA_ "GenSigTimeoutTime_BPCM" SG_ 609 EPBSts 0;
BA_ "GenSigSendType" SG_ 609 EPBSts 3;
BA_ "GenSigTimeoutTime_IDCM" SG_ 609 EPBSts 0;
BA_ "GenSigTimeoutTime_EVCU2" SG_ 609 EPBSts 0;
BA_ "GenSigTimeoutTime_ECM" SG_ 1066 ExternalTemperature 0;
BA_ "GenSigTimeoutTime_SGCP" SG_ 1066 ExternalTemperature 0;
BA_ "GenSigTimeoutTime_EVCU2" SG_ 1066 ExternalTemperature 0;
BA_ "GenSigTimeoutTime_ECM" SG_ 2564554482 N_PDU_18DBFEF2 0;
BA_ "GenSigTimeoutTime_BPCM" SG_ 2564554482 N_PDU_18DBFEF2 0;
BA_ "GenSigTimeoutTime_SGCP" SG_ 2564554482 N_PDU_18DBFEF2 0;
BA_ "GenSigTimeoutTime_MCPB" SG_ 2564554482 N_PDU_18DBFEF2 0;
BA_ "GenSigTimeoutTime_MCPA" SG_ 2564554482 N_PDU_18DBFEF2 0;
BA_ "GenSigTimeoutTime_IDCM" SG_ 2564554482 N_PDU_18DBFEF2 0;
BA_ "GenSigTimeoutTime_EVCU2" SG_ 2564554482 N_PDU_18DBFEF2 0;
BA_ "GenSigTimeoutTime_ECM" SG_ 1827 IgnitionOnCounter 0;
BA_ "GenSigTimeoutTime_BPCM" SG_ 1827 IgnitionOnCounter 0;
BA_ "GenSigTimeoutTime_IDCM" SG_ 1827 IgnitionOnCounter 0;
BA_ "GenSigTimeoutTime_EVCU2" SG_ 1827 IgnitionOnCounter 0;
BA_ "GenSigTimeoutTime_ECM" SG_ 1153 ExternalTemperatureC 0;
BA_ "GenSigTimeoutTime_BPCM" SG_ 1153 ExternalTemperatureC 0;
BA_ "GenSigStartValue" SG_ 1153 ExternalTemperatureC 511;
BA_ "GenSigTimeoutTime_IDCM" SG_ 1153 ExternalTemperatureC 0;
BA_ "GenSigTimeoutTime_EVCU2" SG_ 1153 ExternalTemperatureC 0;
BA_ "GenSigTimeoutTime_BPCM" SG_ 1153 MessageCounter_BCM10 0;
BA_ "GenSigTimeoutTime_MCPA" SG_ 1153 MessageCounter_BCM10 0;
BA_ "GenSigTimeoutTime_IDCM" SG_ 1153 MessageCounter_BCM10 0;
BA_ "GenSigTimeoutTime_EVCU2" SG_ 1153 MessageCounter_BCM10 0;
BA_ "GenSigTimeoutTime_ECM" SG_ 1153 CmdIgnSts 0;
BA_ "GenSigSendType" SG_ 1153 CmdIgnSts 3;
BA_ "GenSigTimeoutTime_IDCM" SG_ 1153 CmdIgnSts 0;
BA_ "GenSigTimeoutTime_EVCU2" SG_ 1153 CmdIgnSts 0;
BA_ "GenSigTimeoutTime_BPCM" SG_ 1153 CRC_BCM10 0;
BA_ "GenSigTimeoutTime_MCPA" SG_ 1153 CRC_BCM10 0;
BA_ "GenSigTimeoutTime_IDCM" SG_ 1153 CRC_BCM10 0;
BA_ "GenSigTimeoutTime_EVCU2" SG_ 1153 CRC_BCM10 0;
BA_ "GenSigTimeoutTime_ECM" SG_ 1032 MessageCounter_HYBRID_THERMAL_C 0;
BA_ "GenSigTimeoutTime_BPCM" SG_ 1032 MessageCounter_HYBRID_THERMAL_C 0;
BA_ "SystemSignalLongSymbol" SG_ 1032 MessageCounter_HYBRID_THERMAL_C "MessageCounter_HYBRID_THERMAL_COMMAND";
BA_ "GenSigTimeoutTime_SGCP" SG_ 1032 MessageCounter_HYBRID_THERMAL_C 0;
BA_ "GenSigTimeoutTime_MCPB" SG_ 1032 MessageCounter_HYBRID_THERMAL_C 0;
BA_ "GenSigTimeoutTime_MCPA" SG_ 1032 MessageCounter_HYBRID_THERMAL_C 0;
BA_ "GenSigTimeoutTime_IDCM" SG_ 1032 MessageCounter_HYBRID_THERMAL_C 0;
BA_ "GenSigTimeoutTime_ECM" SG_ 1032 CRC_HYBRID_THERMAL_COMMAND 0;
BA_ "GenSigTimeoutTime_BPCM" SG_ 1032 CRC_HYBRID_THERMAL_COMMAND 0;
BA_ "GenSigTimeoutTime_SGCP" SG_ 1032 CRC_HYBRID_THERMAL_COMMAND 0;
BA_ "GenSigTimeoutTime_MCPB" SG_ 1032 CRC_HYBRID_THERMAL_COMMAND 0;
BA_ "GenSigTimeoutTime_ECM" SG_ 1626 IMPACTCommand 0;
BA_ "GenSigSendType" SG_ 1626 IMPACTCommand 5;
BA_ "GenSigTimeoutTime_SGCP" SG_ 1626 IMPACTCommand 0;
BA_ "GenSigTimeoutTime_EVCU2" SG_ 1626 IMPACTCommand 0;
BA_ "GenSigTimeoutTime_ECM" SG_ 1829 TotalOdometer 0;
BA_ "GenSigTimeoutTime_BPCM" SG_ 1829 TotalOdometer 0;
BA_ "GenSigTimeoutTime_IDCM" SG_ 1829 TotalOdometer 0;
BA_ "GenSigTimeoutTime_EVCU2" SG_ 1829 TotalOdometer 0;
BA_ "GenSigTimeoutTime_ECM" SG_ 156 GPS_Date_Day 0;
BA_ "GenSigStartValue" SG_ 156 GPS_Date_Day 255;
BA_ "GenSigTimeoutTime_SGCP" SG_ 156 GPS_Date_Day 0;
BA_ "GenSigTimeoutTime_EVCU2" SG_ 156 GPS_Date_Day 0;
BA_ "GenSigTimeoutTime_ECM" SG_ 520 GearEngagedForDisplay 0;
BA_ "GenSigTimeoutTime_BPCM" SG_ 520 GearEngagedForDisplay 0;
BA_ "GenSigStartValue" SG_ 520 GearEngagedForDisplay 31;
BA_ "GenSigTimeoutTime_IDCM" SG_ 520 GearEngagedForDisplay 0;
BA_ "GenSigTimeoutTime_EVCU2" SG_ 520 GearEngagedForDisplay 0;
BA_ "GenSigTimeoutTime_ECM" SG_ 156 GPS_UTC_Second 0;
BA_ "GenSigStartValue" SG_ 156 GPS_UTC_Second 65535;
BA_ "GenSigTimeoutTime_SGCP" SG_ 156 GPS_UTC_Second 0;
BA_ "GenSigTimeoutTime_EVCU2" SG_ 156 GPS_UTC_Second 0;
BA_ "GenSigTimeoutTime_ECM" SG_ 156 GPS_UTC_Minute 0;
BA_ "GenSigStartValue" SG_ 156 GPS_UTC_Minute 255;
BA_ "GenSigTimeoutTime_SGCP" SG_ 156 GPS_UTC_Minute 0;
BA_ "GenSigTimeoutTime_EVCU2" SG_ 156 GPS_UTC_Minute 0;
BA_ "GenSigTimeoutTime_ECM" SG_ 156 GPS_UTC_Hour 0;
BA_ "GenSigStartValue" SG_ 156 GPS_UTC_Hour 255;
BA_ "GenSigTimeoutTime_SGCP" SG_ 156 GPS_UTC_Hour 0;
BA_ "GenSigTimeoutTime_EVCU2" SG_ 156 GPS_UTC_Hour 0;
BA_ "GenSigTimeoutTime_ECM" SG_ 156 GPS_Date_Year 0;
BA_ "GenSigStartValue" SG_ 156 GPS_Date_Year 65535;
BA_ "GenSigTimeoutTime_SGCP" SG_ 156 GPS_Date_Year 0;
BA_ "GenSigTimeoutTime_EVCU2" SG_ 156 GPS_Date_Year 0;
BA_ "GenSigTimeoutTime_ECM" SG_ 156 GPS_Date_Month 0;
BA_ "GenSigStartValue" SG_ 156 GPS_Date_Month 255;
BA_ "GenSigTimeoutTime_SGCP" SG_ 156 GPS_Date_Month 0;
BA_ "GenSigTimeoutTime_EVCU2" SG_ 156 GPS_Date_Month 0;
BA_ "GenSigTimeoutTime_ECM" SG_ 1626 IMPACTConfirm 0;
BA_ "GenSigSendType" SG_ 1626 IMPACTConfirm 5;
BA_ "GenSigInactiveValue" SG_ 1626 IMPACTConfirm 1;
BA_ "GenSigStartValue" SG_ 1626 IMPACTConfirm 1;
BA_ "GenSigTimeoutTime_SGCP" SG_ 1626 IMPACTConfirm 0;
BA_ "GenSigTimeoutTime_EVCU2" SG_ 1626 IMPACTConfirm 0;
BA_ "GenSigTimeoutTime_ECM" SG_ 1053 VIN_MSG 0;
BA_ "GenSigTimeoutTime_BPCM" SG_ 1053 VIN_MSG 0;
BA_ "GenSigStartValue" SG_ 1053 VIN_MSG 3;
BA_ "GenSigTimeoutTime_IDCM" SG_ 1053 VIN_MSG 0;
BA_ "GenSigTimeoutTime_EVCU2" SG_ 1053 VIN_MSG 0;
BA_ "GenSigTimeoutTime_ECM" SG_ 2564554481 N_PDU_18DBFEF1 0;
BA_ "GenSigTimeoutTime_BPCM" SG_ 2564554481 N_PDU_18DBFEF1 0;
BA_ "GenSigTimeoutTime_SGCP" SG_ 2564554481 N_PDU_18DBFEF1 0;
BA_ "GenSigTimeoutTime_MCPB" SG_ 2564554481 N_PDU_18DBFEF1 0;
BA_ "GenSigTimeoutTime_MCPA" SG_ 2564554481 N_PDU_18DBFEF1 0;
BA_ "GenSigTimeoutTime_IDCM" SG_ 2564554481 N_PDU_18DBFEF1 0;
BA_ "GenSigTimeoutTime_EVCU2" SG_ 2564554481 N_PDU_18DBFEF1 0;
BA_ "GenSigTimeoutTime_ECM" SG_ 1053 VIN_DATA 0;
BA_ "GenSigTimeoutTime_BPCM" SG_ 1053 VIN_DATA 0;
BA_ "GenSigTimeoutTime_IDCM" SG_ 1053 VIN_DATA 0;
BA_ "GenSigTimeoutTime_EVCU2" SG_ 1053 VIN_DATA 0;
BA_ "GenSigTimeoutTime_IDCM" SG_ 478 VDCM_StsSWWldgReq 0;
BA_ "GenSigTimeoutTime_EVCU2" SG_ 478 VDCM_StsSWWldgReq 0;
BA_ "GenSigTimeoutTime_ECM" SG_ 502 HVCMS_Protocol_Entry1 0;
BA_ "GenSigTimeoutTime_BPCM" SG_ 502 HVCMS_Protocol_Entry1 0;
BA_ "GenSigTimeoutTime_SGCP" SG_ 502 HVCMS_Protocol_Entry1 0;
BA_ "GenSigTimeoutTime_MCPB" SG_ 502 HVCMS_Protocol_Entry1 0;
BA_ "GenSigTimeoutTime_MCPA" SG_ 502 HVCMS_Protocol_Entry1 0;
BA_ "GenSigTimeoutTime_EVCU2" SG_ 502 HVCMS_Protocol_Entry1 0;
BA_ "GenSigTimeoutTime_SGCP" SG_ 502 HVCMS_BulkChargingComplete 0;
BA_ "GenSigTimeoutTime_MCPB" SG_ 502 HVCMS_BulkChargingComplete 0;
BA_ "GenSigTimeoutTime_MCPA" SG_ 502 HVCMS_BulkChargingComplete 0;
BA_ "GenSigTimeoutTime_EVCU2" SG_ 502 HVCMS_BulkChargingComplete 0;
BA_ "GenSigTimeoutTime_ECM" SG_ 502 HVCMS_EVTargetVoltage 0;
BA_ "GenSigTimeoutTime_BPCM" SG_ 502 HVCMS_EVTargetVoltage 0;
BA_ "GenSigTimeoutTime_SGCP" SG_ 502 HVCMS_EVTargetVoltage 0;
BA_ "GenSigTimeoutTime_MCPB" SG_ 502 HVCMS_EVTargetVoltage 0;
BA_ "GenSigTimeoutTime_MCPA" SG_ 502 HVCMS_EVTargetVoltage 0;
BA_ "GenSigTimeoutTime_EVCU2" SG_ 502 HVCMS_EVTargetVoltage 0;
BA_ "GenSigTimeoutTime_ECM" SG_ 502 HVCMS_EVTargetCurrent 0;
BA_ "GenSigTimeoutTime_BPCM" SG_ 502 HVCMS_EVTargetCurrent 0;
BA_ "GenSigTimeoutTime_SGCP" SG_ 502 HVCMS_EVTargetCurrent 0;
BA_ "GenSigTimeoutTime_MCPB" SG_ 502 HVCMS_EVTargetCurrent 0;
BA_ "GenSigTimeoutTime_MCPA" SG_ 502 HVCMS_EVTargetCurrent 0;
BA_ "GenSigTimeoutTime_EVCU2" SG_ 502 HVCMS_EVTargetCurrent 0;
BA_ "GenSigTimeoutTime_MCPA" SG_ 502 HVCMS_EVRESSConditioning 0;
BA_ "GenSigTimeoutTime_EVCU2" SG_ 502 HVCMS_EVRESSConditioning 0;
BA_ "GenSigTimeoutTime_ECM" SG_ 502 HVCMS_EVRESSConditioning 0;
BA_ "GenSigTimeoutTime_BPCM" SG_ 502 HVCMS_EVRESSConditioning 0;
BA_ "GenSigTimeoutTime_SGCP" SG_ 502 HVCMS_EVRESSConditioning 0;
BA_ "GenSigTimeoutTime_MCPB" SG_ 502 HVCMS_EVRESSConditioning 0;
BA_ "GenSigTimeoutTime_ECM" SG_ 502 HVCMS_EVRESS_SOC 0;
BA_ "GenSigTimeoutTime_BPCM" SG_ 502 HVCMS_EVRESS_SOC 0;
BA_ "GenSigTimeoutTime_SGCP" SG_ 502 HVCMS_EVRESS_SOC 0;
BA_ "GenSigTimeoutTime_MCPB" SG_ 502 HVCMS_EVRESS_SOC 0;
BA_ "GenSigTimeoutTime_MCPA" SG_ 502 HVCMS_EVRESS_SOC 0;
BA_ "GenSigTimeoutTime_EVCU2" SG_ 502 HVCMS_EVRESS_SOC 0;
BA_ "GenSigTimeoutTime_ECM" SG_ 502 HVCMS_EVReady 0;
BA_ "GenSigTimeoutTime_BPCM" SG_ 502 HVCMS_EVReady 0;
BA_ "GenSigTimeoutTime_SGCP" SG_ 502 HVCMS_EVReady 0;
BA_ "GenSigTimeoutTime_MCPB" SG_ 502 HVCMS_EVReady 0;
BA_ "GenSigTimeoutTime_MCPA" SG_ 502 HVCMS_EVReady 0;
BA_ "GenSigTimeoutTime_EVCU2" SG_ 502 HVCMS_EVReady 0;
BA_ "GenSigTimeoutTime_SGCP" SG_ 1578 OBC_ChargingFaultSts 0;
BA_ "GenSigTimeoutTime_MCPB" SG_ 1578 OBC_ChargingFaultSts 0;
BA_ "GenSigTimeoutTime_MCPA" SG_ 1578 OBC_ChargingFaultSts 0;
BA_ "GenSigTimeoutTime_IDCM" SG_ 1578 OBC_ChargingFaultSts 0;
BA_ "GenSigTimeoutTime_SGCP" SG_ 2654486653 SourceNodeIdentifier_1E38407D 0;
BA_ "GenSigTimeoutTime_MCPB" SG_ 2654486653 SourceNodeIdentifier_1E38407D 0;
BA_ "GenSigTimeoutTime_ECM" SG_ 2654486653 CBV_bit7_1E38407D 0;
BA_ "GenSigTimeoutTime_BPCM" SG_ 2654486653 CBV_bit7_1E38407D 0;
BA_ "GenSigTimeoutTime_SGCP" SG_ 2654486653 CBV_bit7_1E38407D 0;
BA_ "GenSigTimeoutTime_MCPB" SG_ 2654486653 CBV_bit7_1E38407D 0;
BA_ "GenSigTimeoutTime_MCPA" SG_ 2654486653 CBV_bit7_1E38407D 0;
BA_ "GenSigTimeoutTime_IDCM" SG_ 2654486653 CBV_bit7_1E38407D 0;
BA_ "GenSigTimeoutTime_EVCU2" SG_ 2654486653 CBV_bit7_1E38407D 0;
BA_ "GenSigTimeoutTime_ECM" SG_ 2651930624 Digit_11 0;
BA_ "GenSigTimeoutTime_BPCM" SG_ 2651930624 Digit_11 0;
BA_ "GenSigTimeoutTime_SGCP" SG_ 2651930624 Digit_11 0;
BA_ "GenSigTimeoutTime_IDCM" SG_ 2651930624 Digit_11 0;
BA_ "GenSigTimeoutTime_EVCU2" SG_ 2651930624 Digit_11 0;
BA_ "GenSigTimeoutTime_ECM" SG_ 2651930624 Digit_10 0;
BA_ "GenSigTimeoutTime_BPCM" SG_ 2651930624 Digit_10 0;
BA_ "GenSigTimeoutTime_SGCP" SG_ 2651930624 Digit_10 0;
BA_ "GenSigTimeoutTime_IDCM" SG_ 2651930624 Digit_10 0;
BA_ "GenSigTimeoutTime_EVCU2" SG_ 2651930624 Digit_10 0;
BA_ "GenSigTimeoutTime_ECM" SG_ 2651930624 Digit_09 0;
BA_ "GenSigTimeoutTime_BPCM" SG_ 2651930624 Digit_09 0;
BA_ "GenSigTimeoutTime_SGCP" SG_ 2651930624 Digit_09 0;
BA_ "GenSigTimeoutTime_IDCM" SG_ 2651930624 Digit_09 0;
BA_ "GenSigTimeoutTime_EVCU2" SG_ 2651930624 Digit_09 0;
BA_ "GenSigTimeoutTime_ECM" SG_ 2651930624 Digit_08 0;
BA_ "GenSigTimeoutTime_BPCM" SG_ 2651930624 Digit_08 0;
BA_ "GenSigTimeoutTime_SGCP" SG_ 2651930624 Digit_08 0;
BA_ "GenSigTimeoutTime_IDCM" SG_ 2651930624 Digit_08 0;
BA_ "GenSigTimeoutTime_EVCU2" SG_ 2651930624 Digit_08 0;
BA_ "GenSigTimeoutTime_ECM" SG_ 2651930624 Digit_07 0;
BA_ "GenSigTimeoutTime_BPCM" SG_ 2651930624 Digit_07 0;
BA_ "GenSigTimeoutTime_SGCP" SG_ 2651930624 Digit_07 0;
BA_ "GenSigTimeoutTime_IDCM" SG_ 2651930624 Digit_07 0;
BA_ "GenSigTimeoutTime_EVCU2" SG_ 2651930624 Digit_07 0;
BA_ "GenSigTimeoutTime_ECM" SG_ 2651930624 Digit_06 0;
BA_ "GenSigTimeoutTime_BPCM" SG_ 2651930624 Digit_06 0;
BA_ "GenSigTimeoutTime_SGCP" SG_ 2651930624 Digit_06 0;
BA_ "GenSigTimeoutTime_IDCM" SG_ 2651930624 Digit_06 0;
BA_ "GenSigTimeoutTime_EVCU2" SG_ 2651930624 Digit_06 0;
BA_ "GenSigTimeoutTime_ECM" SG_ 2651930624 Digit_05 0;
BA_ "GenSigTimeoutTime_BPCM" SG_ 2651930624 Digit_05 0;
BA_ "GenSigTimeoutTime_SGCP" SG_ 2651930624 Digit_05 0;
BA_ "GenSigTimeoutTime_IDCM" SG_ 2651930624 Digit_05 0;
BA_ "GenSigTimeoutTime_EVCU2" SG_ 2651930624 Digit_05 0;
BA_ "GenSigTimeoutTime_ECM" SG_ 2651930624 Digit_04 0;
BA_ "GenSigTimeoutTime_BPCM" SG_ 2651930624 Digit_04 0;
BA_ "GenSigTimeoutTime_SGCP" SG_ 2651930624 Digit_04 0;
BA_ "GenSigTimeoutTime_IDCM" SG_ 2651930624 Digit_04 0;
BA_ "GenSigTimeoutTime_EVCU2" SG_ 2651930624 Digit_04 0;
BA_ "GenSigTimeoutTime_BPCM" SG_ 2651930624 Digit_03 0;
BA_ "GenSigTimeoutTime_SGCP" SG_ 2651930624 Digit_03 0;
BA_ "GenSigTimeoutTime_IDCM" SG_ 2651930624 Digit_03 0;
BA_ "GenSigTimeoutTime_EVCU2" SG_ 2651930624 Digit_03 0;
BA_ "GenSigTimeoutTime_ECM" SG_ 2651930624 Digit_03 0;
BA_ "GenSigTimeoutTime_ECM" SG_ 2651930624 Digit_02 0;
BA_ "GenSigTimeoutTime_BPCM" SG_ 2651930624 Digit_02 0;
BA_ "GenSigTimeoutTime_SGCP" SG_ 2651930624 Digit_02 0;
BA_ "GenSigTimeoutTime_IDCM" SG_ 2651930624 Digit_02 0;
BA_ "GenSigTimeoutTime_EVCU2" SG_ 2651930624 Digit_02 0;
BA_ "GenSigTimeoutTime_ECM" SG_ 2651930624 Digit_01 0;
BA_ "GenSigTimeoutTime_BPCM" SG_ 2651930624 Digit_01 0;
BA_ "GenSigTimeoutTime_SGCP" SG_ 2651930624 Digit_01 0;
BA_ "GenSigTimeoutTime_IDCM" SG_ 2651930624 Digit_01 0;
BA_ "GenSigTimeoutTime_EVCU2" SG_ 256 OperationalModeSts 0;
BA_ "GenSigTimeoutTime_BPCM" SG_ 256 OperationalModeSts 0;
BA_ "GenSigTimeoutTime_IDCM" SG_ 256 OperationalModeSts 0;
BA_ "GenSigTimeoutTime_SGCP" SG_ 498 EVSE_Notification 0;
BA_ "GenSigTimeoutTime_MCPB" SG_ 498 EVSE_Notification 0;
BA_ "GenSigTimeoutTime_MCPA" SG_ 498 EVSE_Notification 0;
BA_ "GenSigTimeoutTime_IDCM" SG_ 498 EVSE_Notification 0;
BA_ "GenSigTimeoutTime_ECM" SG_ 498 EVSE_Notification 0;
BA_ "GenSigTimeoutTime_BPCM" SG_ 498 EVSE_Notification 0;
BA_ "GenSigTimeoutTime_ECM" SG_ 498 HVCMS_EVSEMinimumVoltageLimit 0;
BA_ "GenSigTimeoutTime_BPCM" SG_ 498 HVCMS_EVSEMinimumVoltageLimit 0;
BA_ "GenSigTimeoutTime_SGCP" SG_ 498 HVCMS_EVSEMinimumVoltageLimit 0;
BA_ "GenSigTimeoutTime_MCPB" SG_ 498 HVCMS_EVSEMinimumVoltageLimit 0;
BA_ "GenSigTimeoutTime_MCPA" SG_ 498 HVCMS_EVSEMinimumVoltageLimit 0;
BA_ "GenSigTimeoutTime_IDCM" SG_ 498 HVCMS_EVSEMinimumVoltageLimit 0;
BA_ "GenSigTimeoutTime_ECM" SG_ 498 HVCMS_EVSEPresentCurrent 0;
BA_ "GenSigTimeoutTime_BPCM" SG_ 498 HVCMS_EVSEPresentCurrent 0;
BA_ "GenSigTimeoutTime_SGCP" SG_ 498 HVCMS_EVSEPresentCurrent 0;
BA_ "GenSigTimeoutTime_MCPB" SG_ 498 HVCMS_EVSEPresentCurrent 0;
BA_ "GenSigTimeoutTime_MCPA" SG_ 498 HVCMS_EVSEPresentCurrent 0;
BA_ "GenSigTimeoutTime_IDCM" SG_ 498 HVCMS_EVSEPresentCurrent 0;
BA_ "GenSigTimeoutTime_ECM" SG_ 498 HVCMS_EVSEVoltageLimitAchieved 0;
BA_ "GenSigTimeoutTime_BPCM" SG_ 498 HVCMS_EVSEVoltageLimitAchieved 0;
BA_ "GenSigStartValue" SG_ 498 HVCMS_EVSEVoltageLimitAchieved 2;
BA_ "GenSigTimeoutTime_SGCP" SG_ 498 HVCMS_EVSEVoltageLimitAchieved 0;
BA_ "GenSigTimeoutTime_MCPB" SG_ 498 HVCMS_EVSEVoltageLimitAchieved 0;
BA_ "GenSigTimeoutTime_MCPA" SG_ 498 HVCMS_EVSEVoltageLimitAchieved 0;
BA_ "GenSigTimeoutTime_IDCM" SG_ 498 HVCMS_EVSEVoltageLimitAchieved 0;
BA_ "GenSigTimeoutTime_ECM" SG_ 498 HVCMS_EVSEPowerLimitAchieved 0;
BA_ "GenSigTimeoutTime_BPCM" SG_ 498 HVCMS_EVSEPowerLimitAchieved 0;
BA_ "GenSigStartValue" SG_ 498 HVCMS_EVSEPowerLimitAchieved 2;
BA_ "GenSigTimeoutTime_SGCP" SG_ 498 HVCMS_EVSEPowerLimitAchieved 0;
BA_ "GenSigTimeoutTime_MCPB" SG_ 498 HVCMS_EVSEPowerLimitAchieved 0;
BA_ "GenSigTimeoutTime_MCPA" SG_ 498 HVCMS_EVSEPowerLimitAchieved 0;
BA_ "GenSigTimeoutTime_IDCM" SG_ 498 HVCMS_EVSEPowerLimitAchieved 0;
BA_ "GenSigTimeoutTime_ECM" SG_ 498 OBCM_PLCTypeSts 0;
BA_ "GenSigTimeoutTime_BPCM" SG_ 498 OBCM_PLCTypeSts 0;
BA_ "GenSigTimeoutTime_SGCP" SG_ 498 OBCM_PLCTypeSts 0;
BA_ "GenSigTimeoutTime_MCPB" SG_ 498 OBCM_PLCTypeSts 0;
BA_ "GenSigTimeoutTime_MCPA" SG_ 498 OBCM_PLCTypeSts 0;
BA_ "GenSigTimeoutTime_IDCM" SG_ 498 OBCM_PLCTypeSts 0;
BA_ "GenSigTimeoutTime_ECM" SG_ 498 DC_Isolation_Disable_Cmd 0;
BA_ "GenSigTimeoutTime_BPCM" SG_ 498 DC_Isolation_Disable_Cmd 0;
BA_ "GenSigTimeoutTime_SGCP" SG_ 498 DC_Isolation_Disable_Cmd 0;
BA_ "GenSigTimeoutTime_MCPB" SG_ 498 DC_Isolation_Disable_Cmd 0;
BA_ "GenSigTimeoutTime_MCPA" SG_ 498 DC_Isolation_Disable_Cmd 0;
BA_ "GenSigTimeoutTime_IDCM" SG_ 498 DC_Isolation_Disable_Cmd 0;
BA_ "GenSigTimeoutTime_ECM" SG_ 498 EVSE_OfferedEnergyTransferType 0;
BA_ "GenSigTimeoutTime_BPCM" SG_ 498 EVSE_OfferedEnergyTransferType 0;
BA_ "GenSigTimeoutTime_SGCP" SG_ 498 EVSE_OfferedEnergyTransferType 0;
BA_ "GenSigTimeoutTime_MCPB" SG_ 498 EVSE_OfferedEnergyTransferType 0;
BA_ "GenSigTimeoutTime_MCPA" SG_ 498 EVSE_OfferedEnergyTransferType 0;
BA_ "GenSigTimeoutTime_IDCM" SG_ 498 EVSE_OfferedEnergyTransferType 0;
BA_ "GenSigTimeoutTime_ECM" SG_ 498 HVCMS_TxMessageStat 0;
BA_ "GenSigTimeoutTime_BPCM" SG_ 498 HVCMS_TxMessageStat 0;
BA_ "GenSigTimeoutTime_SGCP" SG_ 498 HVCMS_TxMessageStat 0;
BA_ "GenSigTimeoutTime_MCPB" SG_ 498 HVCMS_TxMessageStat 0;
BA_ "GenSigTimeoutTime_MCPA" SG_ 498 HVCMS_TxMessageStat 0;
BA_ "GenSigTimeoutTime_IDCM" SG_ 498 HVCMS_TxMessageStat 0;
BA_ "GenSigTimeoutTime_ECM" SG_ 498 HVCMS_ResponseCode 0;
BA_ "GenSigTimeoutTime_BPCM" SG_ 498 HVCMS_ResponseCode 0;
BA_ "GenSigTimeoutTime_SGCP" SG_ 498 HVCMS_ResponseCode 0;
BA_ "GenSigTimeoutTime_MCPB" SG_ 498 HVCMS_ResponseCode 0;
BA_ "GenSigTimeoutTime_MCPA" SG_ 498 HVCMS_ResponseCode 0;
BA_ "GenSigTimeoutTime_IDCM" SG_ 498 HVCMS_ResponseCode 0;
BA_ "GenSigTimeoutTime_ECM" SG_ 498 HVCMS_EVSEProcessing 0;
BA_ "GenSigTimeoutTime_BPCM" SG_ 498 HVCMS_EVSEProcessing 0;
BA_ "GenSigTimeoutTime_SGCP" SG_ 498 HVCMS_EVSEProcessing 0;
BA_ "GenSigTimeoutTime_MCPB" SG_ 498 HVCMS_EVSEProcessing 0;
BA_ "GenSigTimeoutTime_MCPA" SG_ 498 HVCMS_EVSEProcessing 0;
BA_ "GenSigTimeoutTime_IDCM" SG_ 498 HVCMS_EVSEProcessing 0;
BA_ "GenSigTimeoutTime_ECM" SG_ 498 EVSE_FreeService 0;
BA_ "GenSigTimeoutTime_BPCM" SG_ 498 EVSE_FreeService 0;
BA_ "GenSigTimeoutTime_SGCP" SG_ 498 EVSE_FreeService 0;
BA_ "GenSigTimeoutTime_MCPB" SG_ 498 EVSE_FreeService 0;
BA_ "GenSigTimeoutTime_MCPA" SG_ 498 EVSE_FreeService 0;
BA_ "GenSigTimeoutTime_IDCM" SG_ 498 EVSE_FreeService 0;
BA_ "GenSigTimeoutTime_ECM" SG_ 498 HVCMS_EVSEPresentVoltage 0;
BA_ "GenSigTimeoutTime_BPCM" SG_ 498 HVCMS_EVSEPresentVoltage 0;
BA_ "GenSigTimeoutTime_SGCP" SG_ 498 HVCMS_EVSEPresentVoltage 0;
BA_ "GenSigTimeoutTime_MCPB" SG_ 498 HVCMS_EVSEPresentVoltage 0;
BA_ "GenSigTimeoutTime_MCPA" SG_ 498 HVCMS_EVSEPresentVoltage 0;
BA_ "GenSigTimeoutTime_IDCM" SG_ 498 HVCMS_EVSEPresentVoltage 0;
BA_ "GenSigTimeoutTime_ECM" SG_ 498 HVCMS_EVSEPeakCurrentRipple 0;
BA_ "GenSigTimeoutTime_BPCM" SG_ 498 HVCMS_EVSEPeakCurrentRipple 0;
BA_ "GenSigStartValue" SG_ 498 HVCMS_EVSEPeakCurrentRipple 500;
BA_ "GenSigTimeoutTime_SGCP" SG_ 498 HVCMS_EVSEPeakCurrentRipple 0;
BA_ "GenSigTimeoutTime_MCPB" SG_ 498 HVCMS_EVSEPeakCurrentRipple 0;
BA_ "GenSigTimeoutTime_MCPA" SG_ 498 HVCMS_EVSEPeakCurrentRipple 0;
BA_ "GenSigTimeoutTime_IDCM" SG_ 498 HVCMS_EVSEPeakCurrentRipple 0;
BA_ "GenSigTimeoutTime_MCPB" SG_ 498 HVCMS_EVSEMinCurrentLimit 0;
BA_ "GenSigTimeoutTime_MCPA" SG_ 498 HVCMS_EVSEMinCurrentLimit 0;
BA_ "GenSigTimeoutTime_IDCM" SG_ 498 HVCMS_EVSEMinCurrentLimit 0;
BA_ "GenSigTimeoutTime_ECM" SG_ 498 HVCMS_EVSEMinCurrentLimit 0;
BA_ "GenSigTimeoutTime_BPCM" SG_ 498 HVCMS_EVSEMinCurrentLimit 0;
BA_ "GenSigTimeoutTime_SGCP" SG_ 498 HVCMS_EVSEMinCurrentLimit 0;
BA_ "GenSigTimeoutTime_ECM" SG_ 498 HVCMS_EVSEMaxPowerLimit 0;
BA_ "GenSigTimeoutTime_BPCM" SG_ 498 HVCMS_EVSEMaxPowerLimit 0;
BA_ "GenSigTimeoutTime_SGCP" SG_ 498 HVCMS_EVSEMaxPowerLimit 0;
BA_ "GenSigTimeoutTime_MCPB" SG_ 498 HVCMS_EVSEMaxPowerLimit 0;
BA_ "GenSigTimeoutTime_MCPA" SG_ 498 HVCMS_EVSEMaxPowerLimit 0;
BA_ "GenSigTimeoutTime_IDCM" SG_ 498 HVCMS_EVSEMaxPowerLimit 0;
BA_ "GenSigTimeoutTime_ECM" SG_ 498 HVCMS_EVSEMaxCurrentLimit 0;
BA_ "GenSigTimeoutTime_BPCM" SG_ 498 HVCMS_EVSEMaxCurrentLimit 0;
BA_ "GenSigTimeoutTime_SGCP" SG_ 498 HVCMS_EVSEMaxCurrentLimit 0;
BA_ "GenSigTimeoutTime_MCPB" SG_ 498 HVCMS_EVSEMaxCurrentLimit 0;
BA_ "GenSigTimeoutTime_MCPA" SG_ 498 HVCMS_EVSEMaxCurrentLimit 0;
BA_ "GenSigTimeoutTime_IDCM" SG_ 498 HVCMS_EVSEMaxCurrentLimit 0;
BA_ "GenSigTimeoutTime_ECM" SG_ 498 HVCMS_EVSECurrRegulationTol 0;
BA_ "GenSigTimeoutTime_BPCM" SG_ 498 HVCMS_EVSECurrRegulationTol 0;
BA_ "GenSigStartValue" SG_ 498 HVCMS_EVSECurrRegulationTol 500;
BA_ "GenSigTimeoutTime_SGCP" SG_ 498 HVCMS_EVSECurrRegulationTol 0;
BA_ "GenSigTimeoutTime_MCPB" SG_ 498 HVCMS_EVSECurrRegulationTol 0;
BA_ "GenSigTimeoutTime_MCPA" SG_ 498 HVCMS_EVSECurrRegulationTol 0;
BA_ "GenSigTimeoutTime_IDCM" SG_ 498 HVCMS_EVSECurrRegulationTol 0;
BA_ "GenSigTimeoutTime_ECM" SG_ 498 HVCMS_EnergyToBeDelivered 0;
BA_ "GenSigTimeoutTime_BPCM" SG_ 498 HVCMS_EnergyToBeDelivered 0;
BA_ "GenSigTimeoutTime_SGCP" SG_ 498 HVCMS_EnergyToBeDelivered 0;
BA_ "GenSigTimeoutTime_MCPB" SG_ 498 HVCMS_EnergyToBeDelivered 0;
BA_ "GenSigTimeoutTime_MCPA" SG_ 498 HVCMS_EnergyToBeDelivered 0;
BA_ "GenSigTimeoutTime_IDCM" SG_ 498 HVCMS_EnergyToBeDelivered 0;
BA_ "GenSigTimeoutTime_ECM" SG_ 498 EVSE_IsolationSts 0;
BA_ "GenSigTimeoutTime_BPCM" SG_ 498 EVSE_IsolationSts 0;
BA_ "GenSigTimeoutTime_SGCP" SG_ 498 EVSE_IsolationSts 0;
BA_ "GenSigTimeoutTime_MCPB" SG_ 498 EVSE_IsolationSts 0;
BA_ "GenSigTimeoutTime_MCPA" SG_ 498 EVSE_IsolationSts 0;
BA_ "GenSigTimeoutTime_IDCM" SG_ 498 EVSE_IsolationSts 0;
BA_ "GenSigTimeoutTime_ECM" SG_ 498 EVSE_Accepted_Protocol 0;
BA_ "GenSigTimeoutTime_BPCM" SG_ 498 EVSE_Accepted_Protocol 0;
BA_ "GenSigTimeoutTime_SGCP" SG_ 498 EVSE_Accepted_Protocol 0;
BA_ "GenSigTimeoutTime_MCPB" SG_ 498 EVSE_Accepted_Protocol 0;
BA_ "GenSigTimeoutTime_MCPA" SG_ 498 EVSE_Accepted_Protocol 0;
BA_ "GenSigTimeoutTime_IDCM" SG_ 498 EVSE_Accepted_Protocol 0;
BA_ "GenSigTimeoutTime_ECM" SG_ 498 DC_TimeOut 0;
BA_ "GenSigTimeoutTime_BPCM" SG_ 498 DC_TimeOut 0;
BA_ "GenSigTimeoutTime_SGCP" SG_ 498 DC_TimeOut 0;
BA_ "GenSigTimeoutTime_MCPB" SG_ 498 DC_TimeOut 0;
BA_ "GenSigTimeoutTime_MCPA" SG_ 498 DC_TimeOut 0;
BA_ "GenSigTimeoutTime_IDCM" SG_ 498 DC_TimeOut 0;
BA_ "GenSigTimeoutTime_MCPB" SG_ 498 HVCMS_EVSEMaximumVoltageLimit 0;
BA_ "GenSigTimeoutTime_MCPA" SG_ 498 HVCMS_EVSEMaximumVoltageLimit 0;
BA_ "GenSigTimeoutTime_IDCM" SG_ 498 HVCMS_EVSEMaximumVoltageLimit 0;
BA_ "GenSigTimeoutTime_ECM" SG_ 1578 OBC_EVServiceLampOn 0;
BA_ "GenSigTimeoutTime_BPCM" SG_ 1578 OBC_EVServiceLampOn 0;
BA_ "GenSigTimeoutTime_ECM" SG_ 1578 OBC_EVServiceLampFlash 0;
BA_ "GenSigTimeoutTime_BPCM" SG_ 1578 OBC_EVServiceLampFlash 0;
BA_ "GenSigTimeoutTime_SGCP" SG_ 1578 OBC_EVServiceLampFlash 0;
BA_ "GenSigTimeoutTime_MCPB" SG_ 1578 OBC_EVServiceLampFlash 0;
BA_ "GenSigTimeoutTime_MCPA" SG_ 1578 OBC_EVServiceLampFlash 0;
BA_ "GenSigTimeoutTime_IDCM" SG_ 1578 OBC_EVServiceLampFlash 0;
BA_ "GenSigTimeoutTime_ECM" SG_ 1578 OBC_CurrentFailureSts 0;
BA_ "GenSigTimeoutTime_BPCM" SG_ 1578 OBC_CurrentFailureSts 0;
BA_ "GenSigTimeoutTime_SGCP" SG_ 1578 OBC_CurrentFailureSts 0;
BA_ "GenSigTimeoutTime_MCPB" SG_ 1578 OBC_CurrentFailureSts 0;
BA_ "GenSigTimeoutTime_MCPA" SG_ 1578 OBC_CurrentFailureSts 0;
BA_ "GenSigTimeoutTime_IDCM" SG_ 1578 OBC_CurrentFailureSts 0;
BA_ "GenSigTimeoutTime_ECM" SG_ 1578 OBC_IdleTimeMin 0;
BA_ "GenSigTimeoutTime_BPCM" SG_ 1578 OBC_IdleTimeMin 0;
BA_ "GenSigTimeoutTime_SGCP" SG_ 1578 OBC_IdleTimeMin 0;
BA_ "GenSigTimeoutTime_MCPB" SG_ 1578 OBC_IdleTimeMin 0;
BA_ "GenSigTimeoutTime_MCPA" SG_ 1578 OBC_IdleTimeMin 0;
BA_ "GenSigTimeoutTime_IDCM" SG_ 1578 OBC_IdleTimeMin 0;
BA_ "GenSigTimeoutTime_ECM" SG_ 1578 OBC_ChargeTimeSec 0;
BA_ "GenSigTimeoutTime_BPCM" SG_ 1578 OBC_ChargeTimeSec 0;
BA_ "GenSigTimeoutTime_SGCP" SG_ 1578 OBC_ChargeTimeSec 0;
BA_ "GenSigTimeoutTime_MCPB" SG_ 1578 OBC_ChargeTimeSec 0;
BA_ "GenSigTimeoutTime_MCPA" SG_ 1578 OBC_ChargeTimeSec 0;
BA_ "GenSigTimeoutTime_IDCM" SG_ 1578 OBC_ChargeTimeSec 0;
BA_ "GenSigTimeoutTime_ECM" SG_ 1578 OBC_ChargeTimeMin 0;
BA_ "GenSigTimeoutTime_BPCM" SG_ 1578 OBC_ChargeTimeMin 0;
BA_ "GenSigTimeoutTime_SGCP" SG_ 1578 OBC_ChargeTimeMin 0;
BA_ "GenSigTimeoutTime_MCPB" SG_ 1578 OBC_ChargeTimeMin 0;
BA_ "GenSigTimeoutTime_MCPA" SG_ 1578 OBC_ChargeTimeMin 0;
BA_ "GenSigTimeoutTime_IDCM" SG_ 1578 OBC_ChargeTimeMin 0;
BA_ "GenSigTimeoutTime_ECM" SG_ 1578 Charging_WHr 0;
BA_ "GenSigTimeoutTime_BPCM" SG_ 1578 Charging_WHr 0;
BA_ "GenSigTimeoutTime_SGCP" SG_ 1578 Charging_WHr 0;
BA_ "GenSigTimeoutTime_MCPB" SG_ 1578 Charging_WHr 0;
BA_ "GenSigTimeoutTime_MCPA" SG_ 1578 Charging_WHr 0;
BA_ "GenSigTimeoutTime_IDCM" SG_ 1578 Charging_WHr 0;
BA_ "GenSigTimeoutTime_ECM" SG_ 1372 OBC_Temp4 0;
BA_ "GenSigTimeoutTime_BPCM" SG_ 1372 OBC_Temp4 0;
BA_ "GenSigTimeoutTime_SGCP" SG_ 1372 OBC_Temp4 0;
BA_ "GenSigTimeoutTime_MCPB" SG_ 1372 OBC_Temp4 0;
BA_ "GenSigTimeoutTime_MCPA" SG_ 1372 OBC_Temp4 0;
BA_ "GenSigTimeoutTime_IDCM" SG_ 1372 OBC_Temp4 0;
BA_ "GenSigTimeoutTime_BPCM" SG_ 1372 OBC_Temp3 0;
BA_ "GenSigTimeoutTime_SGCP" SG_ 1372 OBC_Temp3 0;
BA_ "GenSigTimeoutTime_MCPB" SG_ 1372 OBC_Temp3 0;
BA_ "GenSigTimeoutTime_MCPA" SG_ 1372 OBC_Temp3 0;
BA_ "GenSigTimeoutTime_IDCM" SG_ 1372 OBC_Temp3 0;
BA_ "GenSigTimeoutTime_ECM" SG_ 1372 OBC_Temp3 0;
BA_ "GenSigTimeoutTime_SGCP" SG_ 1372 OBC_Temp2 0;
BA_ "GenSigTimeoutTime_MCPB" SG_ 1372 OBC_Temp2 0;
BA_ "GenSigTimeoutTime_MCPA" SG_ 1372 OBC_Temp2 0;
BA_ "GenSigTimeoutTime_IDCM" SG_ 1372 OBC_Temp2 0;
BA_ "GenSigTimeoutTime_ECM" SG_ 1372 OBC_Temp2 0;
BA_ "GenSigTimeoutTime_BPCM" SG_ 1372 OBC_Temp2 0;
BA_ "GenSigTimeoutTime_ECM" SG_ 1372 OBC_Temp1 0;
BA_ "GenSigTimeoutTime_BPCM" SG_ 1372 OBC_Temp1 0;
BA_ "GenSigTimeoutTime_SGCP" SG_ 1372 OBC_Temp1 0;
BA_ "GenSigTimeoutTime_MCPB" SG_ 1372 OBC_Temp1 0;
BA_ "GenSigTimeoutTime_MCPA" SG_ 1372 OBC_Temp1 0;
BA_ "GenSigTimeoutTime_IDCM" SG_ 1372 OBC_Temp1 0;
BA_ "GenSigTimeoutTime_ECM" SG_ 1578 OBC_IdleTimeSec 0;
BA_ "GenSigTimeoutTime_BPCM" SG_ 1578 OBC_IdleTimeSec 0;
BA_ "GenSigTimeoutTime_SGCP" SG_ 1578 OBC_IdleTimeSec 0;
BA_ "GenSigTimeoutTime_MCPB" SG_ 1578 OBC_IdleTimeSec 0;
BA_ "GenSigTimeoutTime_MCPA" SG_ 1578 OBC_IdleTimeSec 0;
BA_ "GenSigTimeoutTime_IDCM" SG_ 1578 OBC_IdleTimeSec 0;
BA_ "GenSigTimeoutTime_ECM" SG_ 478 CurrentRequest 0;
BA_ "GenSigTimeoutTime_BPCM" SG_ 478 CurrentRequest 0;
BA_ "GenSigTimeoutTime_SGCP" SG_ 478 CurrentRequest 0;
BA_ "GenSigTimeoutTime_MCPB" SG_ 478 CurrentRequest 0;
BA_ "GenSigTimeoutTime_MCPA" SG_ 478 CurrentRequest 0;
BA_ "GenSigTimeoutTime_EVCU2" SG_ 478 CurrentRequest 0;
BA_ "GenSigTimeoutTime_ECM" SG_ 478 AC_Curr_Max_Thrsh 0;
BA_ "GenSigTimeoutTime_BPCM" SG_ 478 AC_Curr_Max_Thrsh 0;
BA_ "GenSigTimeoutTime_SGCP" SG_ 478 AC_Curr_Max_Thrsh 0;
BA_ "GenSigTimeoutTime_MCPB" SG_ 478 AC_Curr_Max_Thrsh 0;
BA_ "GenSigTimeoutTime_MCPA" SG_ 478 AC_Curr_Max_Thrsh 0;
BA_ "GenSigTimeoutTime_EVCU2" SG_ 478 AC_Curr_Max_Thrsh 0;
BA_ "GenSigTimeoutTime_ECM" SG_ 1579 HVBatteryVoltage_MinCal 0;
BA_ "GenSigTimeoutTime_SGCP" SG_ 1579 HVBatteryVoltage_MinCal 0;
BA_ "GenSigTimeoutTime_MCPB" SG_ 1579 HVBatteryVoltage_MinCal 0;
BA_ "GenSigTimeoutTime_MCPA" SG_ 1579 HVBatteryVoltage_MinCal 0;
BA_ "GenSigTimeoutTime_EVCU2" SG_ 1579 HVBatteryVoltage_MinCal 0;
BA_ "GenSigTimeoutTime_ECM" SG_ 1579 HVBatteryVoltage_MaxCal 0;
BA_ "GenSigTimeoutTime_SGCP" SG_ 1579 HVBatteryVoltage_MaxCal 0;
BA_ "GenSigTimeoutTime_MCPB" SG_ 1579 HVBatteryVoltage_MaxCal 0;
BA_ "GenSigTimeoutTime_MCPA" SG_ 1579 HVBatteryVoltage_MaxCal 0;
BA_ "GenSigTimeoutTime_EVCU2" SG_ 1579 HVBatteryVoltage_MaxCal 0;
BA_ "GenSigTimeoutTime_ECM" SG_ 1579 HVBatteryCurrent_MaxCal 0;
BA_ "GenSigTimeoutTime_SGCP" SG_ 1579 HVBatteryCurrent_MaxCal 0;
BA_ "GenSigTimeoutTime_MCPB" SG_ 1579 HVBatteryCurrent_MaxCal 0;
BA_ "GenSigTimeoutTime_MCPA" SG_ 1579 HVBatteryCurrent_MaxCal 0;
BA_ "GenSigTimeoutTime_EVCU2" SG_ 1579 HVBatteryCurrent_MaxCal 0;
BA_ "GenSigTimeoutTime_ECM" SG_ 1579 ChargeSystemFaultReason 0;
BA_ "GenSigTimeoutTime_BPCM" SG_ 1579 ChargeSystemFaultReason 0;
BA_ "GenSigTimeoutTime_SGCP" SG_ 1579 ChargeSystemFaultReason 0;
BA_ "GenSigTimeoutTime_MCPB" SG_ 1579 ChargeSystemFaultReason 0;
BA_ "GenSigTimeoutTime_MCPA" SG_ 1579 ChargeSystemFaultReason 0;
BA_ "GenSigTimeoutTime_EVCU2" SG_ 1579 ChargeSystemFaultReason 0;
BA_ "GenSigTimeoutTime_ECM" SG_ 1579 ACCurrent_MaxCal 0;
BA_ "GenSigTimeoutTime_SGCP" SG_ 1579 ACCurrent_MaxCal 0;
BA_ "GenSigTimeoutTime_MCPB" SG_ 1579 ACCurrent_MaxCal 0;
BA_ "GenSigTimeoutTime_MCPA" SG_ 1579 ACCurrent_MaxCal 0;
BA_ "GenSigTimeoutTime_EVCU2" SG_ 1579 ACCurrent_MaxCal 0;
BA_ "GenSigTimeoutTime_ECM" SG_ 1579 OBCM_PLUG_STS 0;
BA_ "GenSigTimeoutTime_BPCM" SG_ 1579 OBCM_PLUG_STS 0;
BA_ "GenSigTimeoutTime_SGCP" SG_ 1579 OBCM_PLUG_STS 0;
BA_ "GenSigTimeoutTime_MCPB" SG_ 1579 OBCM_PLUG_STS 0;
BA_ "GenSigTimeoutTime_ECM" SG_ 478 CRC_HYBRID_CHARGING_COMMAND 0;
BA_ "GenSigTimeoutTime_BPCM" SG_ 478 CRC_HYBRID_CHARGING_COMMAND 0;
BA_ "GenSigTimeoutTime_SGCP" SG_ 478 CRC_HYBRID_CHARGING_COMMAND 0;
BA_ "GenSigTimeoutTime_MCPB" SG_ 478 CRC_HYBRID_CHARGING_COMMAND 0;
BA_ "GenSigTimeoutTime_MCPA" SG_ 478 CRC_HYBRID_CHARGING_COMMAND 0;
BA_ "GenSigTimeoutTime_EVCU2" SG_ 478 CRC_HYBRID_CHARGING_COMMAND 0;
BA_ "GenSigTimeoutTime_MCPA" SG_ 478 VoltageRequest 0;
BA_ "GenSigTimeoutTime_EVCU2" SG_ 478 VoltageRequest 0;
BA_ "GenSigTimeoutTime_ECM" SG_ 478 VoltageRequest 0;
BA_ "GenSigTimeoutTime_BPCM" SG_ 478 VoltageRequest 0;
BA_ "GenSigTimeoutTime_SGCP" SG_ 478 VoltageRequest 0;
BA_ "GenSigTimeoutTime_MCPB" SG_ 478 VoltageRequest 0;
BA_ "GenSigTimeoutTime_SGCP" SG_ 258 LatAcceleration_BSM 0;
BA_ "GenSigTimeoutTime_IDCM" SG_ 258 LatAcceleration_BSM 0;
BA_ "GenSigTimeoutTime_EVCU2" SG_ 258 LatAcceleration_BSM 0;
BA_ "GenSigTimeoutTime_ECM" SG_ 258 ESCActive 0;
BA_ "GenSigTimeoutTime_BPCM" SG_ 258 ESCActive 0;
BA_ "GenSigTimeoutTime_SGCP" SG_ 258 ESCActive 0;
BA_ "GenSigTimeoutTime_IDCM" SG_ 258 ESCActive 0;
BA_ "GenSigTimeoutTime_EVCU2" SG_ 258 ESCActive 0;
BA_ "GenSigTimeoutTime_ECM" SG_ 258 CRC_BRAKE2 0;
BA_ "GenSigTimeoutTime_BPCM" SG_ 258 CRC_BRAKE2 0;
BA_ "GenSigTimeoutTime_SGCP" SG_ 258 CRC_BRAKE2 0;
BA_ "GenSigTimeoutTime_IDCM" SG_ 258 CRC_BRAKE2 0;
BA_ "GenSigTimeoutTime_EVCU2" SG_ 258 CRC_BRAKE2 0;
BA_ "GenSigTimeoutTime_ECM" SG_ 258 ABSActive 0;
BA_ "GenSigTimeoutTime_BPCM" SG_ 258 ABSActive 0;
BA_ "GenSigTimeoutTime_SGCP" SG_ 258 ABSActive 0;
BA_ "GenSigTimeoutTime_IDCM" SG_ 258 ABSActive 0;
BA_ "GenSigTimeoutTime_EVCU2" SG_ 258 ABSActive 0;
BA_ "GenSigTimeoutTime_IDCM" SG_ 276 PropulsionSystemActive 0;
BA_ "GenSigTimeoutTime_EVCU2" SG_ 276 PropulsionSystemActive 0;
BA_ "GenSigTimeoutTime_SGCP" SG_ 276 PropulsionSystemActive 0;
BA_ "GenSigTimeoutTime_MCPB" SG_ 276 PropulsionSystemActive 0;
BA_ "GenSigTimeoutTime_MCPA" SG_ 276 PropulsionSystemActive 0;
BA_ "GenSigTimeoutTime_ECM" SG_ 276 DriveReady 0;
BA_ "GenSigTimeoutTime_BPCM" SG_ 276 DriveReady 0;
BA_ "GenSigTimeoutTime_SGCP" SG_ 276 DriveReady 0;
BA_ "GenSigTimeoutTime_MCPB" SG_ 276 DriveReady 0;
BA_ "GenSigTimeoutTime_MCPA" SG_ 276 DriveReady 0;
BA_ "GenSigTimeoutTime_IDCM" SG_ 276 DriveReady 0;
BA_ "GenSigTimeoutTime_EVCU2" SG_ 276 DriveReady 0;
BA_ "GenSigTimeoutTime_MCPA" SG_ 1579 OBCM_PLUG_STS 0;
BA_ "GenSigTimeoutTime_EVCU2" SG_ 1579 OBCM_PLUG_STS 0;
BA_ "GenSigTimeoutTime_ECM" SG_ 478 AC_Curr_Min_Thrsh 0;
BA_ "GenSigTimeoutTime_BPCM" SG_ 478 AC_Curr_Min_Thrsh 0;
BA_ "GenSigTimeoutTime_SGCP" SG_ 478 AC_Curr_Min_Thrsh 0;
BA_ "GenSigTimeoutTime_MCPB" SG_ 478 AC_Curr_Min_Thrsh 0;
BA_ "GenSigTimeoutTime_MCPA" SG_ 478 AC_Curr_Min_Thrsh 0;
BA_ "GenSigTimeoutTime_EVCU2" SG_ 478 AC_Curr_Min_Thrsh 0;
BA_ "GenSigTimeoutTime_MCPB" SG_ 478 VDCM_StsWldgReq 0;
BA_ "GenSigTimeoutTime_MCPA" SG_ 478 VDCM_StsWldgReq 0;
BA_ "GenSigTimeoutTime_EVCU2" SG_ 478 VDCM_StsWldgReq 0;
BA_ "GenSigTimeoutTime_ECM" SG_ 478 VDCM_StsSWWldgReq 0;
BA_ "GenSigTimeoutTime_BPCM" SG_ 478 VDCM_StsSWWldgReq 0;
BA_ "GenSigTimeoutTime_SGCP" SG_ 478 VDCM_StsSWWldgReq 0;
BA_ "GenSigTimeoutTime_MCPB" SG_ 478 VDCM_StsSWWldgReq 0;
BA_ "GenSigTimeoutTime_MCPA" SG_ 478 VDCM_StsSWWldgReq 0;
BA_ "GenSigTimeoutTime_ECM" SG_ 478 VDCM_SessnStopReq 0;
BA_ "GenSigTimeoutTime_BPCM" SG_ 478 VDCM_SessnStopReq 0;
BA_ "GenSigTimeoutTime_SGCP" SG_ 478 VDCM_SessnStopReq 0;
BA_ "GenSigTimeoutTime_MCPB" SG_ 478 VDCM_SessnStopReq 0;
BA_ "GenSigTimeoutTime_MCPA" SG_ 478 VDCM_SessnStopReq 0;
BA_ "GenSigTimeoutTime_EVCU2" SG_ 478 VDCM_SessnStopReq 0;
BA_ "GenSigTimeoutTime_BPCM" SG_ 478 HVBatCoolantLevelLow 0;
BA_ "GenSigTimeoutTime_ECM" SG_ 478 OBC_OperativeModeReq 0;
BA_ "GenSigTimeoutTime_BPCM" SG_ 478 OBC_OperativeModeReq 0;
BA_ "GenSigStartValue" SG_ 478 OBC_OperativeModeReq 15;
BA_ "GenSigTimeoutTime_SGCP" SG_ 478 OBC_OperativeModeReq 0;
BA_ "GenSigTimeoutTime_MCPB" SG_ 478 OBC_OperativeModeReq 0;
BA_ "GenSigTimeoutTime_MCPA" SG_ 478 OBC_OperativeModeReq 0;
BA_ "GenSigTimeoutTime_EVCU2" SG_ 478 OBC_OperativeModeReq 0;
BA_ "GenSigTimeoutTime_ECM" SG_ 478 HV_Volt_Min_Thrsh 0;
BA_ "GenSigTimeoutTime_BPCM" SG_ 478 HV_Volt_Min_Thrsh 0;
BA_ "GenSigTimeoutTime_SGCP" SG_ 478 HV_Volt_Min_Thrsh 0;
BA_ "GenSigTimeoutTime_MCPB" SG_ 478 HV_Volt_Min_Thrsh 0;
BA_ "GenSigTimeoutTime_MCPA" SG_ 478 HV_Volt_Min_Thrsh 0;
BA_ "GenSigTimeoutTime_EVCU2" SG_ 478 HV_Volt_Min_Thrsh 0;
BA_ "GenSigTimeoutTime_ECM" SG_ 478 HV_Volt_Max_Thrsh 0;
BA_ "GenSigTimeoutTime_BPCM" SG_ 478 HV_Volt_Max_Thrsh 0;
BA_ "GenSigTimeoutTime_SGCP" SG_ 478 HV_Volt_Max_Thrsh 0;
BA_ "GenSigTimeoutTime_MCPB" SG_ 478 HV_Volt_Max_Thrsh 0;
BA_ "GenSigTimeoutTime_MCPA" SG_ 478 HV_Volt_Max_Thrsh 0;
BA_ "GenSigTimeoutTime_EVCU2" SG_ 478 HV_Volt_Max_Thrsh 0;
BA_ "GenSigTimeoutTime_ECM" SG_ 478 DC_Curr_Max_Thrsh 0;
BA_ "GenSigTimeoutTime_BPCM" SG_ 478 DC_Curr_Max_Thrsh 0;
BA_ "GenSigStartValue" SG_ 478 DC_Curr_Max_Thrsh 511;
BA_ "GenSigTimeoutTime_SGCP" SG_ 478 DC_Curr_Max_Thrsh 0;
BA_ "GenSigTimeoutTime_MCPB" SG_ 478 DC_Curr_Max_Thrsh 0;
BA_ "GenSigTimeoutTime_MCPA" SG_ 478 DC_Curr_Max_Thrsh 0;
BA_ "GenSigTimeoutTime_EVCU2" SG_ 478 DC_Curr_Max_Thrsh 0;
BA_ "GenSigTimeoutTime_ECM" SG_ 478 ChargeEnable 0;
BA_ "GenSigTimeoutTime_BPCM" SG_ 478 ChargeEnable 0;
BA_ "GenSigTimeoutTime_SGCP" SG_ 478 ChargeEnable 0;
BA_ "GenSigTimeoutTime_MCPB" SG_ 478 ChargeEnable 0;
BA_ "GenSigTimeoutTime_MCPA" SG_ 478 ChargeEnable 0;
BA_ "GenSigTimeoutTime_EVCU2" SG_ 478 ChargeEnable 0;
BA_ "GenSigTimeoutTime_ECM" SG_ 502 HVCMS_Protocol_Entry2 0;
BA_ "GenSigTimeoutTime_BPCM" SG_ 502 HVCMS_Protocol_Entry2 0;
BA_ "GenSigTimeoutTime_SGCP" SG_ 502 HVCMS_Protocol_Entry2 0;
BA_ "GenSigTimeoutTime_MCPB" SG_ 502 HVCMS_Protocol_Entry2 0;
BA_ "GenSigTimeoutTime_MCPA" SG_ 502 HVCMS_Protocol_Entry2 0;
BA_ "GenSigTimeoutTime_EVCU2" SG_ 502 HVCMS_Protocol_Entry2 0;
BA_ "GenSigTimeoutTime_ECM" SG_ 502 HVCMS_ReadyToChargeState 0;
BA_ "GenSigTimeoutTime_BPCM" SG_ 502 HVCMS_ReadyToChargeState 0;
BA_ "GenSigTimeoutTime_SGCP" SG_ 502 HVCMS_ReadyToChargeState 0;
BA_ "GenSigTimeoutTime_MCPB" SG_ 502 HVCMS_ReadyToChargeState 0;
BA_ "GenSigTimeoutTime_MCPA" SG_ 502 HVCMS_ReadyToChargeState 0;
BA_ "GenSigTimeoutTime_EVCU2" SG_ 502 HVCMS_ReadyToChargeState 0;
BA_ "GenSigTimeoutTime_ECM" SG_ 502 HVCMS_Protocol_Entry3 0;
BA_ "GenSigTimeoutTime_BPCM" SG_ 502 HVCMS_Protocol_Entry3 0;
BA_ "GenSigTimeoutTime_SGCP" SG_ 502 HVCMS_Protocol_Entry3 0;
BA_ "GenSigTimeoutTime_MCPB" SG_ 502 HVCMS_Protocol_Entry3 0;
BA_ "GenSigTimeoutTime_MCPA" SG_ 502 HVCMS_Protocol_Entry3 0;
BA_ "GenSigTimeoutTime_EVCU2" SG_ 502 HVCMS_Protocol_Entry3 0;
BA_ "GenSigTimeoutTime_ECM" SG_ 1460 FOTA_Status 0;
BA_ "GenSigTimeoutTime_BPCM" SG_ 1460 FOTA_Status 0;
BA_ "GenSigSendType" SG_ 1460 FOTA_Status 3;
BA_ "GenSigTimeoutTime_IDCM" SG_ 1460 FOTA_Status 0;
BA_ "GenSigTimeoutTime_EVCU2" SG_ 1460 FOTA_Status 0;
BA_ "GenSigTimeoutTime_ECM" SG_ 502 VDCM_OBCDischCurrentLim 0;
BA_ "GenSigTimeoutTime_BPCM" SG_ 502 VDCM_OBCDischCurrentLim 0;
BA_ "GenSigStartValue" SG_ 502 VDCM_OBCDischCurrentLim 815;
BA_ "GenSigTimeoutTime_SGCP" SG_ 502 VDCM_OBCDischCurrentLim 0;
BA_ "GenSigTimeoutTime_MCPB" SG_ 502 VDCM_OBCDischCurrentLim 0;
BA_ "GenSigTimeoutTime_MCPA" SG_ 502 VDCM_OBCDischCurrentLim 0;
BA_ "GenSigTimeoutTime_EVCU2" SG_ 502 VDCM_OBCDischCurrentLim 0;
BA_ "GenSigTimeoutTime_ECM" SG_ 502 VDCM_BattBulkSOC 0;
BA_ "GenSigTimeoutTime_BPCM" SG_ 502 VDCM_BattBulkSOC 0;
BA_ "GenSigTimeoutTime_SGCP" SG_ 502 VDCM_BattBulkSOC 0;
BA_ "GenSigTimeoutTime_MCPB" SG_ 502 VDCM_BattBulkSOC 0;
BA_ "GenSigTimeoutTime_MCPA" SG_ 502 VDCM_BattBulkSOC 0;
BA_ "GenSigTimeoutTime_EVCU2" SG_ 502 VDCM_BattBulkSOC 0;
BA_ "GenSigTimeoutTime_ECM" SG_ 502 HVCMS_ServiceScope 0;
BA_ "GenSigTimeoutTime_BPCM" SG_ 502 HVCMS_ServiceScope 0;
BA_ "GenSigTimeoutTime_SGCP" SG_ 502 HVCMS_ServiceScope 0;
BA_ "GenSigTimeoutTime_MCPB" SG_ 502 HVCMS_ServiceScope 0;
BA_ "GenSigTimeoutTime_MCPA" SG_ 502 HVCMS_ServiceScope 0;
BA_ "GenSigTimeoutTime_EVCU2" SG_ 502 HVCMS_ServiceScope 0;
BA_ "GenSigTimeoutTime_ECM" SG_ 502 HVCMS_EVMax_V_Limit 0;
BA_ "GenSigTimeoutTime_BPCM" SG_ 502 HVCMS_EVMax_V_Limit 0;
BA_ "GenSigTimeoutTime_SGCP" SG_ 502 HVCMS_EVMax_V_Limit 0;
BA_ "GenSigTimeoutTime_MCPB" SG_ 502 HVCMS_EVMax_V_Limit 0;
BA_ "GenSigTimeoutTime_MCPA" SG_ 502 HVCMS_EVMax_V_Limit 0;
BA_ "GenSigTimeoutTime_EVCU2" SG_ 502 HVCMS_EVMax_V_Limit 0;
BA_ "GenSigTimeoutTime_ECM" SG_ 502 HVCMS_EVMax_P_Limit 0;
BA_ "GenSigTimeoutTime_BPCM" SG_ 502 HVCMS_EVMax_P_Limit 0;
BA_ "GenSigTimeoutTime_SGCP" SG_ 502 HVCMS_EVMax_P_Limit 0;
BA_ "GenSigTimeoutTime_MCPB" SG_ 502 HVCMS_EVMax_P_Limit 0;
BA_ "GenSigTimeoutTime_MCPA" SG_ 502 HVCMS_EVMax_P_Limit 0;
BA_ "GenSigTimeoutTime_EVCU2" SG_ 502 HVCMS_EVMax_P_Limit 0;
BA_ "GenSigTimeoutTime_ECM" SG_ 502 HVCMS_EVMax_I_Limit 0;
BA_ "GenSigTimeoutTime_BPCM" SG_ 502 HVCMS_EVMax_I_Limit 0;
BA_ "GenSigTimeoutTime_SGCP" SG_ 502 HVCMS_EVMax_I_Limit 0;
BA_ "GenSigTimeoutTime_MCPB" SG_ 502 HVCMS_EVMax_I_Limit 0;
BA_ "GenSigTimeoutTime_MCPA" SG_ 502 HVCMS_EVMax_I_Limit 0;
BA_ "GenSigTimeoutTime_EVCU2" SG_ 502 HVCMS_EVMax_I_Limit 0;
BA_ "GenSigTimeoutTime_ECM" SG_ 502 HVCMS_BulkChargingComplete 0;
BA_ "GenSigTimeoutTime_BPCM" SG_ 502 HVCMS_BulkChargingComplete 0;
BA_ "GenSigTimeoutTime_ECM" SG_ 502 VDCM_TypeCNegotiationSts 0;
BA_ "GenSigTimeoutTime_BPCM" SG_ 502 VDCM_TypeCNegotiationSts 0;
BA_ "GenSigTimeoutTime_SGCP" SG_ 502 VDCM_TypeCNegotiationSts 0;
BA_ "GenSigTimeoutTime_MCPB" SG_ 502 VDCM_TypeCNegotiationSts 0;
BA_ "GenSigTimeoutTime_MCPA" SG_ 502 VDCM_TypeCNegotiationSts 0;
BA_ "GenSigTimeoutTime_EVCU2" SG_ 502 VDCM_TypeCNegotiationSts 0;
BA_ "GenSigTimeoutTime_ECM" SG_ 502 HVCMS_EVEnergyCapacity 0;
BA_ "GenSigTimeoutTime_BPCM" SG_ 502 HVCMS_EVEnergyCapacity 0;
BA_ "GenSigTimeoutTime_SGCP" SG_ 502 HVCMS_EVEnergyCapacity 0;
BA_ "GenSigTimeoutTime_MCPB" SG_ 502 HVCMS_EVEnergyCapacity 0;
BA_ "GenSigTimeoutTime_MCPA" SG_ 502 HVCMS_EVEnergyCapacity 0;
BA_ "GenSigTimeoutTime_EVCU2" SG_ 502 HVCMS_EVEnergyCapacity 0;
BA_ "GenSigTimeoutTime_ECM" SG_ 502 HVCMS_ChargingComplete 0;
BA_ "GenSigTimeoutTime_BPCM" SG_ 502 HVCMS_ChargingComplete 0;
BA_ "GenSigTimeoutTime_SGCP" SG_ 502 HVCMS_ChargingComplete 0;
BA_ "GenSigTimeoutTime_MCPB" SG_ 502 HVCMS_ChargingComplete 0;
BA_ "GenSigTimeoutTime_MCPA" SG_ 502 HVCMS_ChargingComplete 0;
BA_ "GenSigTimeoutTime_EVCU2" SG_ 502 HVCMS_ChargingComplete 0;
BA_ "GenSigTimeoutTime_ECM" SG_ 502 VDCM_GenChallenge 0;
BA_ "GenSigTimeoutTime_BPCM" SG_ 502 VDCM_GenChallenge 0;
BA_ "GenSigTimeoutTime_SGCP" SG_ 502 VDCM_GenChallenge 0;
BA_ "GenSigTimeoutTime_MCPB" SG_ 502 VDCM_GenChallenge 0;
BA_ "GenSigTimeoutTime_MCPA" SG_ 502 VDCM_GenChallenge 0;
BA_ "GenSigTimeoutTime_EVCU2" SG_ 502 VDCM_GenChallenge 0;
BA_ "GenSigTimeoutTime_ECM" SG_ 502 VDCM_ContractAuthenticationID 0;
BA_ "GenSigTimeoutTime_BPCM" SG_ 502 VDCM_ContractAuthenticationID 0;
BA_ "GenSigTimeoutTime_SGCP" SG_ 502 VDCM_ContractAuthenticationID 0;
BA_ "GenSigTimeoutTime_MCPB" SG_ 502 VDCM_ContractAuthenticationID 0;
BA_ "GenSigTimeoutTime_MCPA" SG_ 502 VDCM_ContractAuthenticationID 0;
BA_ "GenSigTimeoutTime_EVCU2" SG_ 502 VDCM_ContractAuthenticationID 0;
BA_ "GenSigTimeoutTime_ECM" SG_ 502 HVCMS_EVEnergyRequest 0;
BA_ "GenSigTimeoutTime_BPCM" SG_ 502 HVCMS_EVEnergyRequest 0;
BA_ "GenSigStartValue" SG_ 502 HVCMS_EVEnergyRequest 131071;
BA_ "GenSigTimeoutTime_SGCP" SG_ 502 HVCMS_EVEnergyRequest 0;
BA_ "GenSigTimeoutTime_MCPB" SG_ 502 HVCMS_EVEnergyRequest 0;
BA_ "GenSigTimeoutTime_MCPA" SG_ 502 HVCMS_EVEnergyRequest 0;
BA_ "GenSigTimeoutTime_EVCU2" SG_ 502 HVCMS_EVEnergyRequest 0;
BA_ "GenSigTimeoutTime_ECM" SG_ 502 OBCM_OutVoltageSyncTgt 0;
BA_ "GenSigTimeoutTime_BPCM" SG_ 502 OBCM_OutVoltageSyncTgt 0;
BA_ "GenSigTimeoutTime_SGCP" SG_ 502 OBCM_OutVoltageSyncTgt 0;
BA_ "GenSigTimeoutTime_MCPB" SG_ 502 OBCM_OutVoltageSyncTgt 0;
BA_ "GenSigTimeoutTime_MCPA" SG_ 502 OBCM_OutVoltageSyncTgt 0;
BA_ "GenSigTimeoutTime_EVCU2" SG_ 502 OBCM_OutVoltageSyncTgt 0;
BA_ "GenSigTimeoutTime_ECM" SG_ 502 HVCMS_EVErrorCode 0;
BA_ "GenSigTimeoutTime_BPCM" SG_ 502 HVCMS_EVErrorCode 0;
BA_ "GenSigTimeoutTime_SGCP" SG_ 502 HVCMS_EVErrorCode 0;
BA_ "GenSigTimeoutTime_MCPB" SG_ 502 HVCMS_EVErrorCode 0;
BA_ "GenSigTimeoutTime_MCPA" SG_ 502 HVCMS_EVErrorCode 0;
BA_ "GenSigTimeoutTime_EVCU2" SG_ 502 HVCMS_EVErrorCode 0;
BA_ "GenSigTimeoutTime_ECM" SG_ 502 HVCMS_RemaningTimeToFullSOC 0;
BA_ "GenSigTimeoutTime_BPCM" SG_ 502 HVCMS_RemaningTimeToFullSOC 0;
BA_ "GenSigTimeoutTime_SGCP" SG_ 502 HVCMS_RemaningTimeToFullSOC 0;
BA_ "GenSigTimeoutTime_MCPB" SG_ 502 HVCMS_RemaningTimeToFullSOC 0;
BA_ "GenSigTimeoutTime_MCPA" SG_ 502 HVCMS_RemaningTimeToFullSOC 0;
BA_ "GenSigTimeoutTime_EVCU2" SG_ 502 HVCMS_RemaningTimeToFullSOC 0;
BA_ "GenSigTimeoutTime_ECM" SG_ 502 HVCMS_RemaningTimeToBulkSOC 0;
BA_ "GenSigTimeoutTime_BPCM" SG_ 502 HVCMS_RemaningTimeToBulkSOC 0;
BA_ "GenSigTimeoutTime_SGCP" SG_ 502 HVCMS_RemaningTimeToBulkSOC 0;
BA_ "GenSigTimeoutTime_MCPB" SG_ 502 HVCMS_RemaningTimeToBulkSOC 0;
BA_ "GenSigTimeoutTime_MCPA" SG_ 502 HVCMS_RemaningTimeToBulkSOC 0;
BA_ "GenSigTimeoutTime_EVCU2" SG_ 502 HVCMS_RemaningTimeToBulkSOC 0;
BA_ "GenSigTimeoutTime_ECM" SG_ 502 HVCMS_ServiceCategory 0;
BA_ "GenSigTimeoutTime_BPCM" SG_ 502 HVCMS_ServiceCategory 0;
BA_ "GenSigTimeoutTime_SGCP" SG_ 502 HVCMS_ServiceCategory 0;
BA_ "GenSigTimeoutTime_MCPB" SG_ 502 HVCMS_ServiceCategory 0;
BA_ "GenSigTimeoutTime_MCPA" SG_ 502 HVCMS_ServiceCategory 0;
BA_ "GenSigTimeoutTime_EVCU2" SG_ 502 HVCMS_ServiceCategory 0;
BA_ "GenSigTimeoutTime_ECM" SG_ 502 HVCMS_SelectedServiceId 0;
BA_ "GenSigTimeoutTime_BPCM" SG_ 502 HVCMS_SelectedServiceId 0;
BA_ "GenSigTimeoutTime_SGCP" SG_ 502 HVCMS_SelectedServiceId 0;
BA_ "GenSigTimeoutTime_MCPB" SG_ 502 HVCMS_SelectedServiceId 0;
BA_ "GenSigTimeoutTime_MCPA" SG_ 502 HVCMS_SelectedServiceId 0;
BA_ "GenSigTimeoutTime_EVCU2" SG_ 502 HVCMS_SelectedServiceId 0;
BA_ "GenSigTimeoutTime_ECM" SG_ 502 HVCMS_SelectedPaymentOptn 0;
BA_ "GenSigTimeoutTime_BPCM" SG_ 502 HVCMS_SelectedPaymentOptn 0;
BA_ "GenSigTimeoutTime_SGCP" SG_ 502 HVCMS_SelectedPaymentOptn 0;
BA_ "GenSigTimeoutTime_MCPB" SG_ 502 HVCMS_SelectedPaymentOptn 0;
BA_ "GenSigTimeoutTime_MCPA" SG_ 502 HVCMS_SelectedPaymentOptn 0;
BA_ "GenSigTimeoutTime_EVCU2" SG_ 502 HVCMS_SelectedPaymentOptn 0;
BA_ "GenSigTimeoutTime_SGCP" SG_ 502 HVCMS_SelectedEnergyTransferType 0;
BA_ "GenSigTimeoutTime_MCPB" SG_ 502 HVCMS_SelectedEnergyTransferType 0;
BA_ "GenSigTimeoutTime_ECM" SG_ 2654486529 CBV_bit1_1E384001 0;
BA_ "GenSigTimeoutTime_BPCM" SG_ 2654486529 CBV_bit1_1E384001 0;
BA_ "GenSigTimeoutTime_SGCP" SG_ 2654486529 CBV_bit1_1E384001 0;
BA_ "GenSigTimeoutTime_MCPB" SG_ 2654486529 CBV_bit1_1E384001 0;
BA_ "GenSigTimeoutTime_MCPA" SG_ 2654486529 CBV_bit1_1E384001 0;
BA_ "GenSigTimeoutTime_IDCM" SG_ 2654486529 CBV_bit1_1E384001 0;
BA_ "GenSigTimeoutTime_EVCU2" SG_ 2654486529 CBV_bit1_1E384001 0;
BA_ "GenSigTimeoutTime_ECM" SG_ 2654486529 CBV_bit2_1E384001 0;
BA_ "GenSigTimeoutTime_BPCM" SG_ 2654486529 CBV_bit2_1E384001 0;
BA_ "GenSigTimeoutTime_SGCP" SG_ 2654486529 CBV_bit2_1E384001 0;
BA_ "GenSigTimeoutTime_MCPB" SG_ 2654486529 CBV_bit2_1E384001 0;
BA_ "GenSigTimeoutTime_MCPA" SG_ 2654486529 CBV_bit2_1E384001 0;
BA_ "GenSigTimeoutTime_IDCM" SG_ 2654486529 CBV_bit2_1E384001 0;
BA_ "GenSigTimeoutTime_EVCU2" SG_ 2654486529 CBV_bit2_1E384001 0;
BA_ "GenSigTimeoutTime_ECM" SG_ 2654486529 CBV_bit3_NMCoordinatorBit_1E384001 0;
BA_ "GenSigTimeoutTime_BPCM" SG_ 2654486529 CBV_bit3_NMCoordinatorBit_1E384001 0;
BA_ "GenSigTimeoutTime_SGCP" SG_ 2654486529 CBV_bit3_NMCoordinatorBit_1E384001 0;
BA_ "GenSigTimeoutTime_MCPB" SG_ 2654486529 CBV_bit3_NMCoordinatorBit_1E384001 0;
BA_ "GenSigTimeoutTime_MCPA" SG_ 2654486529 CBV_bit3_NMCoordinatorBit_1E384001 0;
BA_ "GenSigTimeoutTime_IDCM" SG_ 2654486529 CBV_bit3_NMCoordinatorBit_1E384001 0;
BA_ "GenSigTimeoutTime_EVCU2" SG_ 2654486529 CBV_bit3_NMCoordinatorBit_1E384001 0;
BA_ "GenSigTimeoutTime_ECM" SG_ 2654486529 CBV_bit4_ActiveWakeupBit_1E384001 0;
BA_ "GenSigTimeoutTime_BPCM" SG_ 2654486529 CBV_bit4_ActiveWakeupBit_1E384001 0;
BA_ "GenSigTimeoutTime_SGCP" SG_ 2654486529 CBV_bit4_ActiveWakeupBit_1E384001 0;
BA_ "GenSigTimeoutTime_MCPB" SG_ 2654486529 CBV_bit4_ActiveWakeupBit_1E384001 0;
BA_ "GenSigTimeoutTime_MCPA" SG_ 2654486529 CBV_bit4_ActiveWakeupBit_1E384001 0;
BA_ "GenSigTimeoutTime_IDCM" SG_ 2654486529 CBV_bit4_ActiveWakeupBit_1E384001 0;
BA_ "GenSigTimeoutTime_EVCU2" SG_ 2654486529 CBV_bit4_ActiveWakeupBit_1E384001 0;
BA_ "GenSigTimeoutTime_ECM" SG_ 2654486529 CBV_bit5_1E384001 0;
BA_ "GenSigTimeoutTime_BPCM" SG_ 2654486529 CBV_bit5_1E384001 0;
BA_ "GenSigTimeoutTime_SGCP" SG_ 2654486529 CBV_bit5_1E384001 0;
BA_ "GenSigTimeoutTime_MCPB" SG_ 2654486529 CBV_bit5_1E384001 0;
BA_ "GenSigTimeoutTime_MCPA" SG_ 2654486529 CBV_bit5_1E384001 0;
BA_ "GenSigTimeoutTime_IDCM" SG_ 2654486529 CBV_bit5_1E384001 0;
BA_ "GenSigTimeoutTime_EVCU2" SG_ 2654486529 CBV_bit5_1E384001 0;
BA_ "GenSigTimeoutTime_ECM" SG_ 2654486529 CBV_bit6_PartialNtwInfBit_1E384001 0;
BA_ "GenSigTimeoutTime_BPCM" SG_ 2654486529 CBV_bit6_PartialNtwInfBit_1E384001 0;
BA_ "GenSigTimeoutTime_SGCP" SG_ 2654486529 CBV_bit6_PartialNtwInfBit_1E384001 0;
BA_ "GenSigTimeoutTime_MCPB" SG_ 2654486529 CBV_bit6_PartialNtwInfBit_1E384001 0;
BA_ "GenSigTimeoutTime_MCPA" SG_ 2654486529 CBV_bit6_PartialNtwInfBit_1E384001 0;
BA_ "GenSigTimeoutTime_IDCM" SG_ 2654486529 CBV_bit6_PartialNtwInfBit_1E384001 0;
BA_ "GenSigTimeoutTime_EVCU2" SG_ 2654486529 CBV_bit6_PartialNtwInfBit_1E384001 0;
BA_ "GenSigTimeoutTime_ECM" SG_ 2654486529 CBV_bit7_1E384001 0;
BA_ "GenSigTimeoutTime_BPCM" SG_ 2654486529 CBV_bit7_1E384001 0;
BA_ "GenSigTimeoutTime_SGCP" SG_ 2654486529 CBV_bit7_1E384001 0;
BA_ "GenSigTimeoutTime_MCPB" SG_ 2654486529 CBV_bit7_1E384001 0;
BA_ "GenSigTimeoutTime_MCPA" SG_ 2654486529 CBV_bit7_1E384001 0;
BA_ "GenSigTimeoutTime_IDCM" SG_ 2654486529 CBV_bit7_1E384001 0;
BA_ "GenSigTimeoutTime_EVCU2" SG_ 2654486529 CBV_bit7_1E384001 0;
BA_ "GenSigTimeoutTime_ECM" SG_ 2654486529 SourceNodeIdentifier_1E384001 0;
BA_ "GenSigTimeoutTime_BPCM" SG_ 2654486529 SourceNodeIdentifier_1E384001 0;
BA_ "GenSigTimeoutTime_SGCP" SG_ 2654486529 SourceNodeIdentifier_1E384001 0;
BA_ "GenSigTimeoutTime_MCPB" SG_ 2654486529 SourceNodeIdentifier_1E384001 0;
BA_ "GenSigTimeoutTime_MCPA" SG_ 2654486529 SourceNodeIdentifier_1E384001 0;
BA_ "GenSigTimeoutTime_IDCM" SG_ 2654486529 SourceNodeIdentifier_1E384001 0;
BA_ "GenSigTimeoutTime_EVCU2" SG_ 2654486529 SourceNodeIdentifier_1E384001 0;
BA_ "GenSigTimeoutTime_BPCM" SG_ 2654486529 CBV_bit0_RepeatMessageRequestBit_1E384001 0;
BA_ "GenSigTimeoutTime_SGCP" SG_ 2654486529 CBV_bit0_RepeatMessageRequestBit_1E384001 0;
BA_ "GenSigTimeoutTime_MCPB" SG_ 2654486529 CBV_bit0_RepeatMessageRequestBit_1E384001 0;
BA_ "GenSigTimeoutTime_MCPA" SG_ 2654486529 CBV_bit0_RepeatMessageRequestBit_1E384001 0;
BA_ "GenSigTimeoutTime_IDCM" SG_ 2654486529 CBV_bit0_RepeatMessageRequestBit_1E384001 0;
BA_ "GenSigTimeoutTime_EVCU2" SG_ 2654486529 CBV_bit0_RepeatMessageRequestBit_1E384001 0;
BA_ "GenSigTimeoutTime_ECM" SG_ 2654486529 CBV_bit0_RepeatMessageRequestBit_1E384001 0;
BA_ "GenSigTimeoutTime_EVCU2" SG_ 2651930624 Digit_01 0;
BA_ "GenSigTimeoutTime_EVCU2" SG_ 2564502513 N_PDU_18DB33F1 0;
BA_ "GenSigTimeoutTime_BPCM" SG_ 2564502513 N_PDU_18DB33F1 0;
BA_ "GenSigTimeoutTime_MCPB" SG_ 2564502513 N_PDU_18DB33F1 0;
BA_ "GenSigTimeoutTime_MCPA" SG_ 2564502513 N_PDU_18DB33F1 0;
BA_ "GenSigTimeoutTime_IDCM" SG_ 2564502513 N_PDU_18DB33F1 0;
BA_ "GenSigTimeoutTime_ECM" SG_ 498 EVSE_Service2_Certificate 0;
BA_ "GenSigTimeoutTime_BPCM" SG_ 498 EVSE_Service2_Certificate 0;
BA_ "GenSigTimeoutTime_SGCP" SG_ 498 EVSE_Service2_Certificate 0;
BA_ "GenSigTimeoutTime_MCPB" SG_ 498 EVSE_Service2_Certificate 0;
BA_ "GenSigTimeoutTime_MCPA" SG_ 498 EVSE_Service2_Certificate 0;
BA_ "GenSigTimeoutTime_IDCM" SG_ 498 EVSE_Service2_Certificate 0;
BA_ "GenSigTimeoutTime_ECM" SG_ 498 EVSE_Supported_ISO1 0;
BA_ "GenSigTimeoutTime_ECM" SG_ 498 EVSE_OfferedService 0;
BA_ "GenSigTimeoutTime_BPCM" SG_ 498 EVSE_OfferedService 0;
BA_ "GenSigTimeoutTime_SGCP" SG_ 498 EVSE_OfferedService 0;
BA_ "GenSigTimeoutTime_MCPB" SG_ 498 EVSE_OfferedService 0;
BA_ "GenSigTimeoutTime_MCPA" SG_ 498 EVSE_OfferedService 0;
BA_ "GenSigTimeoutTime_IDCM" SG_ 498 EVSE_OfferedService 0;
BA_ "GenSigTimeoutTime_ECM" SG_ 498 EVSE_OfferedPaymentOptn 0;
BA_ "GenSigTimeoutTime_BPCM" SG_ 498 EVSE_OfferedPaymentOptn 0;
BA_ "GenSigTimeoutTime_SGCP" SG_ 498 EVSE_OfferedPaymentOptn 0;
BA_ "GenSigTimeoutTime_MCPB" SG_ 498 EVSE_OfferedPaymentOptn 0;
BA_ "GenSigTimeoutTime_MCPA" SG_ 498 EVSE_OfferedPaymentOptn 0;
BA_ "GenSigTimeoutTime_IDCM" SG_ 498 EVSE_OfferedPaymentOptn 0;
BA_ "GenSigTimeoutTime_ECM" SG_ 498 EVSE_OfferedPaymentEIM 0;
BA_ "GenSigTimeoutTime_BPCM" SG_ 498 EVSE_OfferedPaymentEIM 0;
BA_ "GenSigTimeoutTime_SGCP" SG_ 498 EVSE_OfferedPaymentEIM 0;
BA_ "GenSigTimeoutTime_MCPB" SG_ 498 EVSE_OfferedPaymentEIM 0;
BA_ "GenSigTimeoutTime_MCPA" SG_ 498 EVSE_OfferedPaymentEIM 0;
BA_ "GenSigTimeoutTime_IDCM" SG_ 498 EVSE_OfferedPaymentEIM 0;
BA_ "GenSigTimeoutTime_ECM" SG_ 498 EVSE_OfferedPaymentContract 0;
BA_ "GenSigTimeoutTime_BPCM" SG_ 498 EVSE_OfferedPaymentContract 0;
BA_ "GenSigTimeoutTime_SGCP" SG_ 498 EVSE_OfferedPaymentContract 0;
BA_ "GenSigTimeoutTime_MCPB" SG_ 498 EVSE_OfferedPaymentContract 0;
BA_ "GenSigTimeoutTime_MCPA" SG_ 498 EVSE_OfferedPaymentContract 0;
BA_ "GenSigTimeoutTime_IDCM" SG_ 498 EVSE_OfferedPaymentContract 0;
BA_ "GenSigTimeoutTime_ECM" SG_ 498 TxMessageResponse 0;
BA_ "GenSigTimeoutTime_BPCM" SG_ 498 TxMessageResponse 0;
BA_ "GenSigTimeoutTime_SGCP" SG_ 498 TxMessageResponse 0;
BA_ "GenSigTimeoutTime_MCPB" SG_ 498 TxMessageResponse 0;
BA_ "GenSigTimeoutTime_MCPA" SG_ 498 TxMessageResponse 0;
BA_ "GenSigTimeoutTime_IDCM" SG_ 498 TxMessageResponse 0;
BA_ "GenSigStartValue" SG_ 498 HVCMS_EVSEStatusCode 15;
BA_ "GenSigTimeoutTime_SGCP" SG_ 498 HVCMS_EVSEStatusCode 0;
BA_ "GenSigTimeoutTime_MCPB" SG_ 498 HVCMS_EVSEStatusCode 0;
BA_ "GenSigTimeoutTime_MCPA" SG_ 498 HVCMS_EVSEStatusCode 0;
BA_ "GenSigTimeoutTime_IDCM" SG_ 498 HVCMS_EVSEStatusCode 0;
BA_ "GenSigTimeoutTime_ECM" SG_ 498 HVCMS_EVSEStatusCode 0;
BA_ "GenSigTimeoutTime_BPCM" SG_ 498 HVCMS_EVSEStatusCode 0;
BA_ "GenSigTimeoutTime_ECM" SG_ 498 EVSE_ServiceId 0;
BA_ "GenSigTimeoutTime_BPCM" SG_ 498 EVSE_ServiceId 0;
BA_ "GenSigTimeoutTime_SGCP" SG_ 498 EVSE_ServiceId 0;
BA_ "GenSigTimeoutTime_MCPB" SG_ 498 EVSE_ServiceId 0;
BA_ "GenSigTimeoutTime_MCPA" SG_ 498 EVSE_ServiceId 0;
BA_ "GenSigTimeoutTime_IDCM" SG_ 498 EVSE_ServiceId 0;
BA_ "GenSigTimeoutTime_ECM" SG_ 498 HVCMS_EVSECurrentLimitAchieved 0;
BA_ "GenSigTimeoutTime_BPCM" SG_ 498 HVCMS_EVSECurrentLimitAchieved 0;
BA_ "GenSigStartValue" SG_ 498 HVCMS_EVSECurrentLimitAchieved 2;
BA_ "GenSigTimeoutTime_SGCP" SG_ 498 HVCMS_EVSECurrentLimitAchieved 0;
BA_ "GenSigTimeoutTime_MCPB" SG_ 498 HVCMS_EVSECurrentLimitAchieved 0;
BA_ "GenSigTimeoutTime_MCPA" SG_ 498 HVCMS_EVSECurrentLimitAchieved 0;
BA_ "GenSigTimeoutTime_IDCM" SG_ 498 HVCMS_EVSECurrentLimitAchieved 0;
BA_ "GenSigTimeoutTime_ECM" SG_ 498 HVCMS_EVSEMaximumVoltageLimit 0;
BA_ "GenSigTimeoutTime_BPCM" SG_ 498 HVCMS_EVSEMaximumVoltageLimit 0;
BA_ "GenSigTimeoutTime_SGCP" SG_ 498 HVCMS_EVSEMaximumVoltageLimit 0;
BA_ "GenSigTimeoutTime_ECM" SG_ 262 PowertrainPrplsnActv 0;
BA_ "GenSigTimeoutTime_BPCM" SG_ 262 PowertrainPrplsnActv 0;
BA_ "GenSigTimeoutTime_ECM" SG_ 1578 OnboardChargerReady 0;
BA_ "GenSigTimeoutTime_BPCM" SG_ 1578 OnboardChargerReady 0;
BA_ "GenSigStartValue" SG_ 1578 OnboardChargerReady 1;
BA_ "GenSigTimeoutTime_SGCP" SG_ 1578 OnboardChargerReady 0;
BA_ "GenSigTimeoutTime_MCPB" SG_ 1578 OnboardChargerReady 0;
BA_ "GenSigTimeoutTime_MCPA" SG_ 1578 OnboardChargerReady 0;
BA_ "GenSigTimeoutTime_IDCM" SG_ 1578 OnboardChargerReady 0;
BA_ "GenSigTimeoutTime_ECM" SG_ 1578 OnboardChargerMode 0;
BA_ "GenSigTimeoutTime_BPCM" SG_ 1578 OnboardChargerMode 0;
BA_ "GenSigSendType" SG_ 1578 OnboardChargerMode 4;
BA_ "GenSigTimeoutTime_SGCP" SG_ 1578 OnboardChargerMode 0;
BA_ "GenSigTimeoutTime_MCPB" SG_ 1578 OnboardChargerMode 0;
BA_ "GenSigTimeoutTime_MCPA" SG_ 1578 OnboardChargerMode 0;
BA_ "GenSigTimeoutTime_IDCM" SG_ 1578 OnboardChargerMode 0;
BA_ "GenSigTimeoutTime_ECM" SG_ 1578 OBC_WakeReason 0;
BA_ "GenSigTimeoutTime_BPCM" SG_ 1578 OBC_WakeReason 0;
BA_ "GenSigTimeoutTime_SGCP" SG_ 1578 OBC_WakeReason 0;
BA_ "GenSigTimeoutTime_MCPB" SG_ 1578 OBC_WakeReason 0;
BA_ "GenSigTimeoutTime_MCPA" SG_ 1578 OBC_WakeReason 0;
BA_ "GenSigTimeoutTime_IDCM" SG_ 1578 OBC_WakeReason 0;
BA_ "GenSigTimeoutTime_ECM" SG_ 1578 OBC_GenericFailSts 0;
BA_ "GenSigTimeoutTime_BPCM" SG_ 1578 OBC_GenericFailSts 0;
BA_ "GenSigTimeoutTime_SGCP" SG_ 1578 OBC_GenericFailSts 0;
BA_ "GenSigTimeoutTime_MCPB" SG_ 1578 OBC_GenericFailSts 0;
BA_ "GenSigTimeoutTime_MCPA" SG_ 1578 OBC_GenericFailSts 0;
BA_ "GenSigTimeoutTime_IDCM" SG_ 1578 OBC_GenericFailSts 0;
BA_ "GenSigTimeoutTime_SGCP" SG_ 1578 OBC_EVServiceLampOn 0;
BA_ "GenSigTimeoutTime_MCPB" SG_ 1578 OBC_EVServiceLampOn 0;
BA_ "GenSigTimeoutTime_MCPA" SG_ 1578 OBC_EVServiceLampOn 0;
BA_ "GenSigTimeoutTime_IDCM" SG_ 1578 OBC_EVServiceLampOn 0;
BA_ "GenSigTimeoutTime_ECM" SG_ 1578 OBC_FaultReason 0;
BA_ "GenSigTimeoutTime_BPCM" SG_ 1578 OBC_FaultReason 0;
BA_ "GenSigTimeoutTime_SGCP" SG_ 1578 OBC_FaultReason 0;
BA_ "GenSigTimeoutTime_MCPB" SG_ 1578 OBC_FaultReason 0;
BA_ "GenSigTimeoutTime_MCPA" SG_ 1578 OBC_FaultReason 0;
BA_ "GenSigTimeoutTime_IDCM" SG_ 1578 OBC_FaultReason 0;
BA_ "GenSigTimeoutTime_ECM" SG_ 1578 OBC_ChargingFaultSts 0;
BA_ "GenSigTimeoutTime_BPCM" SG_ 1578 OBC_ChargingFaultSts 0;
BA_ "GenSigTimeoutTime_ECM" SG_ 1578 OBC_ChargeFailure 0;
BA_ "GenSigTimeoutTime_BPCM" SG_ 1578 OBC_ChargeFailure 0;
BA_ "GenSigTimeoutTime_SGCP" SG_ 1578 OBC_ChargeFailure 0;
BA_ "GenSigTimeoutTime_MCPB" SG_ 1578 OBC_ChargeFailure 0;
BA_ "GenSigTimeoutTime_MCPA" SG_ 1578 OBC_ChargeFailure 0;
BA_ "GenSigTimeoutTime_IDCM" SG_ 1578 OBC_ChargeFailure 0;
BA_ "GenSigTimeoutTime_ECM" SG_ 1578 OBC_CaptureEnvironmentData 0;
BA_ "GenSigTimeoutTime_BPCM" SG_ 1578 OBC_CaptureEnvironmentData 0;
BA_ "GenSigTimeoutTime_SGCP" SG_ 1578 OBC_CaptureEnvironmentData 0;
BA_ "GenSigTimeoutTime_MCPB" SG_ 1578 OBC_CaptureEnvironmentData 0;
BA_ "GenSigTimeoutTime_MCPA" SG_ 1578 OBC_CaptureEnvironmentData 0;
BA_ "GenSigTimeoutTime_IDCM" SG_ 1578 OBC_CaptureEnvironmentData 0;
BA_ "GenSigTimeoutTime_ECM" SG_ 1578 ACplug_PwrMax 0;
BA_ "GenSigTimeoutTime_BPCM" SG_ 1578 ACplug_PwrMax 0;
BA_ "GenSigTimeoutTime_SGCP" SG_ 1578 ACplug_PwrMax 0;
BA_ "GenSigTimeoutTime_MCPB" SG_ 1578 ACplug_PwrMax 0;
BA_ "GenSigTimeoutTime_MCPA" SG_ 1578 ACplug_PwrMax 0;
BA_ "GenSigTimeoutTime_IDCM" SG_ 1578 ACplug_PwrMax 0;
BA_ "GenSigTimeoutTime_ECM" SG_ 753 IDCM_Wakeup_HCP 0;
BA_ "GenSigTimeoutTime_BPCM" SG_ 753 IDCM_Wakeup_HCP 0;
BA_ "GenSigTimeoutTime_SGCP" SG_ 753 IDCM_Wakeup_HCP 0;
BA_ "GenSigTimeoutTime_MCPB" SG_ 753 IDCM_Wakeup_HCP 0;
BA_ "GenSigTimeoutTime_MCPA" SG_ 753 IDCM_Wakeup_HCP 0;
BA_ "GenSigTimeoutTime_IDCM" SG_ 753 IDCM_Wakeup_HCP 0;
BA_ "GenSigTimeoutTime_ECM" SG_ 750 Battery_Volt_1 0;
BA_ "GenSigTimeoutTime_BPCM" SG_ 750 Battery_Volt_1 0;
BA_ "GenSigTimeoutTime_IDCM" SG_ 750 Battery_Volt_1 0;
BA_ "GenSigTimeoutTime_EVCU2" SG_ 750 Battery_Volt_1 0;
BA_ "GenSigTimeoutTime_BPCM" SG_ 276 MessageCounter_HYBRID_POWERTRAI_114 0;
BA_ "SystemSignalLongSymbol" SG_ 276 MessageCounter_HYBRID_POWERTRAI_114 "MessageCounter_HYBRID_POWERTRAIN1";
BA_ "GenSigTimeoutTime_SGCP" SG_ 276 MessageCounter_HYBRID_POWERTRAI_114 0;
BA_ "GenSigTimeoutTime_BPCM" SG_ 269 CRC_HYBRID_POWERTRAIN2 0;
BA_ "GenSigTimeoutTime_SGCP" SG_ 269 CRC_HYBRID_POWERTRAIN2 0;
BA_ "GenSigTimeoutTime_MCPB" SG_ 269 CRC_HYBRID_POWERTRAIN2 0;
BA_ "GenSigTimeoutTime_MCPA" SG_ 269 CRC_HYBRID_POWERTRAIN2 0;
BA_ "GenSigTimeoutTime_IDCM" SG_ 269 CRC_HYBRID_POWERTRAIN2 0;
BA_ "GenSigTimeoutTime_EVCU2" SG_ 269 CRC_HYBRID_POWERTRAIN2 0;
BA_ "GenSigTimeoutTime_BPCM" SG_ 269 MessageCounter_HYBRID_POWERTRAI_10D 0;
BA_ "SystemSignalLongSymbol" SG_ 269 MessageCounter_HYBRID_POWERTRAI_10D "MessageCounter_HYBRID_POWERTRAIN2";
BA_ "GenSigTimeoutTime_SGCP" SG_ 269 MessageCounter_HYBRID_POWERTRAI_10D 0;
BA_ "GenSigTimeoutTime_MCPB" SG_ 269 MessageCounter_HYBRID_POWERTRAI_10D 0;
BA_ "GenSigTimeoutTime_MCPA" SG_ 269 MessageCounter_HYBRID_POWERTRAI_10D 0;
BA_ "GenSigTimeoutTime_IDCM" SG_ 269 MessageCounter_HYBRID_POWERTRAI_10D 0;
BA_ "GenSigTimeoutTime_EVCU2" SG_ 269 MessageCounter_HYBRID_POWERTRAI_10D 0;
BA_ "GenSigTimeoutTime_ECM" SG_ 478 MessageCounter_HYBRID_CHARGING__1DE 0;
BA_ "GenSigTimeoutTime_BPCM" SG_ 478 MessageCounter_HYBRID_CHARGING__1DE 0;
BA_ "SystemSignalLongSymbol" SG_ 478 MessageCounter_HYBRID_CHARGING__1DE "MessageCounter_HYBRID_CHARGING_COMMAND";
BA_ "GenSigTimeoutTime_SGCP" SG_ 478 MessageCounter_HYBRID_CHARGING__1DE 0;
BA_ "GenSigTimeoutTime_MCPB" SG_ 478 MessageCounter_HYBRID_CHARGING__1DE 0;
BA_ "GenSigTimeoutTime_MCPA" SG_ 478 MessageCounter_HYBRID_CHARGING__1DE 0;
BA_ "GenSigTimeoutTime_EVCU2" SG_ 478 MessageCounter_HYBRID_CHARGING__1DE 0;
BA_ "GenSigTimeoutTime_ECM" SG_ 1579 MessageCounter_HYBRID_CHARGING__62B 0;
BA_ "GenSigTimeoutTime_BPCM" SG_ 1579 MessageCounter_HYBRID_CHARGING__62B 0;
BA_ "SystemSignalLongSymbol" SG_ 1579 MessageCounter_HYBRID_CHARGING__62B "MessageCounter_HYBRID_CHARGING_STATUS";
BA_ "GenSigTimeoutTime_SGCP" SG_ 1579 MessageCounter_HYBRID_CHARGING__62B 0;
BA_ "GenSigTimeoutTime_MCPB" SG_ 1579 MessageCounter_HYBRID_CHARGING__62B 0;
BA_ "GenSigTimeoutTime_MCPA" SG_ 1579 MessageCounter_HYBRID_CHARGING__62B 0;
BA_ "GenSigTimeoutTime_EVCU2" SG_ 1579 MessageCounter_HYBRID_CHARGING__62B 0;
BA_ "GenSigTimeoutTime_ECM" SG_ 1579 CRC_HYBRID_CHARGING_STATUS 0;
BA_ "GenSigTimeoutTime_BPCM" SG_ 1579 CRC_HYBRID_CHARGING_STATUS 0;
BA_ "GenSigTimeoutTime_SGCP" SG_ 1579 CRC_HYBRID_CHARGING_STATUS 0;
BA_ "GenSigTimeoutTime_MCPB" SG_ 1579 CRC_HYBRID_CHARGING_STATUS 0;
BA_ "GenSigTimeoutTime_MCPA" SG_ 1579 CRC_HYBRID_CHARGING_STATUS 0;
BA_ "GenSigTimeoutTime_EVCU2" SG_ 1579 CRC_HYBRID_CHARGING_STATUS 0;
BA_ "GenSigTimeoutTime_ECM" SG_ 1579 ChargeSystemSts 0;
BA_ "GenSigTimeoutTime_SGCP" SG_ 1579 ChargeSystemSts 0;
BA_ "GenSigTimeoutTime_MCPB" SG_ 1579 ChargeSystemSts 0;
BA_ "GenSigTimeoutTime_MCPA" SG_ 1579 ChargeSystemSts 0;
BA_ "GenSigTimeoutTime_EVCU2" SG_ 1579 ChargeSystemSts 0;
BA_ "GenSigTimeoutTime_ECM" SG_ 1579 ChargeSystemFault 0;
BA_ "GenSigTimeoutTime_BPCM" SG_ 1579 ChargeSystemFault 0;
BA_ "GenSigTimeoutTime_SGCP" SG_ 1579 ChargeSystemFault 0;
BA_ "GenSigTimeoutTime_MCPB" SG_ 1579 ChargeSystemFault 0;
BA_ "GenSigTimeoutTime_MCPA" SG_ 1579 ChargeSystemFault 0;
BA_ "GenSigTimeoutTime_EVCU2" SG_ 1579 ChargeSystemFault 0;
BA_ "GenSigTimeoutTime_ECM" SG_ 1579 ChargingLevel 0;
BA_ "GenSigTimeoutTime_BPCM" SG_ 1579 ChargingLevel 0;
BA_ "GenSigTimeoutTime_SGCP" SG_ 1579 ChargingLevel 0;
BA_ "GenSigTimeoutTime_MCPB" SG_ 1579 ChargingLevel 0;
BA_ "GenSigTimeoutTime_MCPA" SG_ 1579 ChargingLevel 0;
BA_ "GenSigTimeoutTime_EVCU2" SG_ 1579 ChargingLevel 0;
BA_ "GenSigTimeoutTime_ECM" SG_ 478 VDCM_StsWldgReq 0;
BA_ "GenSigTimeoutTime_BPCM" SG_ 478 VDCM_StsWldgReq 0;
BA_ "GenSigTimeoutTime_SGCP" SG_ 478 VDCM_StsWldgReq 0;
BA_ "GenSigTimeoutTime_ECM" SG_ 478 OBC_ControlMethod 0;
BA_ "GenSigTimeoutTime_BPCM" SG_ 478 OBC_ControlMethod 0;
BA_ "GenSigTimeoutTime_SGCP" SG_ 478 OBC_ControlMethod 0;
BA_ "GenSigTimeoutTime_MCPB" SG_ 478 OBC_ControlMethod 0;
BA_ "GenSigTimeoutTime_MCPA" SG_ 478 OBC_ControlMethod 0;
BA_ "GenSigTimeoutTime_EVCU2" SG_ 478 OBC_ControlMethod 0;
BA_ "GenSigTimeoutTime_ECM" SG_ 478 J1772_CloseS2 0;
BA_ "GenSigTimeoutTime_BPCM" SG_ 478 J1772_CloseS2 0;
BA_ "GenSigTimeoutTime_SGCP" SG_ 478 J1772_CloseS2 0;
BA_ "GenSigTimeoutTime_MCPB" SG_ 478 J1772_CloseS2 0;
BA_ "GenSigTimeoutTime_MCPA" SG_ 478 J1772_CloseS2 0;
BA_ "GenSigTimeoutTime_EVCU2" SG_ 478 J1772_CloseS2 0;
BA_ "GenSigTimeoutTime_ECM" SG_ 478 HVBatCoolantLevelLow 0;
BA_ "GenSigStartValue" SG_ 478 HVBatCoolantLevelLow 3;
BA_ "GenSigTimeoutTime_SGCP" SG_ 478 HVBatCoolantLevelLow 0;
BA_ "GenSigTimeoutTime_MCPB" SG_ 478 HVBatCoolantLevelLow 0;
BA_ "GenSigTimeoutTime_MCPA" SG_ 478 HVBatCoolantLevelLow 0;
BA_ "GenSigTimeoutTime_IDCM" SG_ 478 HVBatCoolantLevelLow 0;
BA_ "GenSigTimeoutTime_EVCU2" SG_ 478 HVBatCoolantLevelLow 0;
BA_ "GenSigTimeoutTime_BPCM" SG_ 276 Hybrid_Remedial_Stop 0;
BA_ "GenSigTimeoutTime_SGCP" SG_ 276 Hybrid_Remedial_Stop 0;
BA_ "GenSigTimeoutTime_MCPB" SG_ 276 Hybrid_Remedial_Stop 0;
BA_ "GenSigTimeoutTime_MCPA" SG_ 276 Hybrid_Remedial_Stop 0;
BA_ "GenSigTimeoutTime_IDCM" SG_ 276 Hybrid_Remedial_Stop 0;
BA_ "GenSigTimeoutTime_EVCU2" SG_ 276 Hybrid_Remedial_Stop 0;
BA_ "GenSigTimeoutTime_BPCM" SG_ 276 HybCrnkAbrted 0;
BA_ "GenSigTimeoutTime_SGCP" SG_ 276 HybCrnkAbrted 0;
BA_ "GenSigTimeoutTime_MCPB" SG_ 276 HybCrnkAbrted 0;
BA_ "GenSigTimeoutTime_MCPA" SG_ 276 HybCrnkAbrted 0;
BA_ "GenSigTimeoutTime_IDCM" SG_ 276 HybCrnkAbrted 0;
BA_ "GenSigTimeoutTime_EVCU2" SG_ 276 HybCrnkAbrted 0;
BA_ "GenSigTimeoutTime_MCPB" SG_ 276 MessageCounter_HYBRID_POWERTRAI_114 0;
BA_ "GenSigTimeoutTime_MCPA" SG_ 502 HVCMS_SelectedEnergyTransferType 0;
BA_ "GenSigTimeoutTime_EVCU2" SG_ 502 HVCMS_SelectedEnergyTransferType 0;
BA_ "GenSigTimeoutTime_ECM" SG_ 502 HVCMS_SelectedEnergyTransferType 0;
BA_ "GenSigTimeoutTime_BPCM" SG_ 502 HVCMS_SelectedEnergyTransferType 0;
BA_ "GenSigTimeoutTime_EVCU2" SG_ 1032 MessageCounter_HYBRID_THERMAL_C 0;
BA_ "GenSigTimeoutTime_MCPA" SG_ 1032 CRC_HYBRID_THERMAL_COMMAND 0;
BA_ "GenSigTimeoutTime_IDCM" SG_ 1032 CRC_HYBRID_THERMAL_COMMAND 0;
BA_ "GenSigTimeoutTime_EVCU2" SG_ 1032 CRC_HYBRID_THERMAL_COMMAND 0;
BA_ "GenSigTimeoutTime_IDCM" SG_ 1032 EOPA_OIL_TEMP 0;
BA_ "GenSigTimeoutTime_EVCU2" SG_ 1032 EOPA_OIL_TEMP 0;
BA_ "GenSigTimeoutTime_ECM" SG_ 1032 EOPB_OIL_TEMP 0;
BA_ "GenSigTimeoutTime_BPCM" SG_ 1032 EOPB_OIL_TEMP 0;
BA_ "GenSigTimeoutTime_SGCP" SG_ 1032 EOPB_OIL_TEMP 0;
BA_ "GenSigTimeoutTime_MCPA" SG_ 1032 EOPB_OIL_TEMP 0;
BA_ "GenSigTimeoutTime_IDCM" SG_ 1032 EOPB_OIL_TEMP 0;
BA_ "GenSigTimeoutTime_EVCU2" SG_ 1032 EOPB_OIL_TEMP 0;
BA_ "GenSigTimeoutTime_ECM" SG_ 1032 SGCP_OIL_TEMP 0;
BA_ "GenSigTimeoutTime_BPCM" SG_ 1032 SGCP_OIL_TEMP 0;
BA_ "GenSigTimeoutTime_MCPB" SG_ 1032 SGCP_OIL_TEMP 0;
BA_ "GenSigTimeoutTime_MCPA" SG_ 1032 SGCP_OIL_TEMP 0;
BA_ "GenSigTimeoutTime_IDCM" SG_ 1032 SGCP_OIL_TEMP 0;
BA_ "GenSigTimeoutTime_EVCU2" SG_ 1032 SGCP_OIL_TEMP 0;
BA_ "GenSigTimeoutTime_ECM" SG_ 1032 SGCP_OIL_FlwRate 0;
BA_ "GenSigTimeoutTime_BPCM" SG_ 1032 SGCP_OIL_FlwRate 0;
BA_ "GenSigTimeoutTime_MCPB" SG_ 1032 SGCP_OIL_FlwRate 0;
BA_ "GenSigTimeoutTime_MCPA" SG_ 1032 SGCP_OIL_FlwRate 0;
BA_ "GenSigTimeoutTime_IDCM" SG_ 1032 SGCP_OIL_FlwRate 0;
BA_ "GenSigTimeoutTime_EVCU2" SG_ 1032 SGCP_OIL_FlwRate 0;
BA_ "GenSigTimeoutTime_ECM" SG_ 1032 EOPB_OIL_FlwRate 0;
BA_ "GenSigTimeoutTime_BPCM" SG_ 1032 EOPB_OIL_FlwRate 0;
BA_ "GenSigTimeoutTime_SGCP" SG_ 1032 EOPB_OIL_FlwRate 0;
BA_ "GenSigTimeoutTime_MCPA" SG_ 1032 EOPB_OIL_FlwRate 0;
BA_ "GenSigTimeoutTime_IDCM" SG_ 1032 EOPB_OIL_FlwRate 0;
BA_ "GenSigTimeoutTime_EVCU2" SG_ 1032 EOPB_OIL_FlwRate 0;
BA_ "GenSigTimeoutTime_ECM" SG_ 498 MC_OBCM_VDCM 0;
BA_ "GenSigTimeoutTime_BPCM" SG_ 498 MC_OBCM_VDCM 0;
BA_ "GenSigTimeoutTime_SGCP" SG_ 498 MC_OBCM_VDCM 0;
BA_ "GenSigTimeoutTime_MCPB" SG_ 498 MC_OBCM_VDCM 0;
BA_ "GenSigTimeoutTime_MCPA" SG_ 498 MC_OBCM_VDCM 0;
BA_ "GenSigTimeoutTime_IDCM" SG_ 498 MC_OBCM_VDCM 0;
BA_ "GenSigTimeoutTime_BPCM" SG_ 498 EVSE_Supported_ISO1 0;
BA_ "GenSigTimeoutTime_SGCP" SG_ 498 EVSE_Supported_ISO1 0;
BA_ "GenSigTimeoutTime_MCPB" SG_ 498 EVSE_Supported_ISO1 0;
BA_ "GenSigTimeoutTime_MCPA" SG_ 498 EVSE_Supported_ISO1 0;
BA_ "GenSigTimeoutTime_IDCM" SG_ 498 EVSE_Supported_ISO1 0;
BA_ "GenSigTimeoutTime_ECM" SG_ 498 EVSE_Supported_DIN 0;
BA_ "GenSigTimeoutTime_BPCM" SG_ 498 EVSE_Supported_DIN 0;
BA_ "GenSigTimeoutTime_SGCP" SG_ 498 EVSE_Supported_DIN 0;
BA_ "GenSigTimeoutTime_MCPB" SG_ 498 EVSE_Supported_DIN 0;
BA_ "GenSigTimeoutTime_MCPA" SG_ 498 EVSE_Supported_DIN 0;
BA_ "GenSigTimeoutTime_IDCM" SG_ 498 EVSE_Supported_DIN 0;
BA_ "GenSigTimeoutTime_ECM" SG_ 498 CRC_OBCM_VDCM 0;
BA_ "GenSigTimeoutTime_BPCM" SG_ 498 CRC_OBCM_VDCM 0;
BA_ "GenSigTimeoutTime_SGCP" SG_ 498 CRC_OBCM_VDCM 0;
BA_ "GenSigTimeoutTime_MCPB" SG_ 498 CRC_OBCM_VDCM 0;
BA_ "GenSigTimeoutTime_MCPA" SG_ 498 CRC_OBCM_VDCM 0;
BA_ "GenSigTimeoutTime_IDCM" SG_ 498 CRC_OBCM_VDCM 0;
BA_ "GenSigTimeoutTime_ECM" SG_ 498 EVSE_Supported_SAE 0;
BA_ "GenSigTimeoutTime_BPCM" SG_ 498 EVSE_Supported_SAE 0;
BA_ "GenSigTimeoutTime_SGCP" SG_ 498 EVSE_Supported_SAE 0;
BA_ "GenSigTimeoutTime_MCPB" SG_ 498 EVSE_Supported_SAE 0;
BA_ "GenSigTimeoutTime_MCPA" SG_ 498 EVSE_Supported_SAE 0;
BA_ "GenSigTimeoutTime_IDCM" SG_ 498 EVSE_Supported_SAE 0;
BA_ "GenSigTimeoutTime_ECM" SG_ 1578 OBC_Prox 0;
BA_ "GenSigTimeoutTime_BPCM" SG_ 1578 OBC_Prox 0;
BA_ "GenSigTimeoutTime_SGCP" SG_ 1578 OBC_Prox 0;
BA_ "GenSigTimeoutTime_MCPB" SG_ 1578 OBC_Prox 0;
BA_ "GenSigTimeoutTime_MCPA" SG_ 1578 OBC_Prox 0;
BA_ "GenSigTimeoutTime_IDCM" SG_ 1578 OBC_Prox 0;
BA_ "GenSigTimeoutTime_ECM" SG_ 1578 OBC_Pilot 0;
BA_ "GenSigTimeoutTime_BPCM" SG_ 1578 OBC_Pilot 0;
BA_ "GenSigTimeoutTime_SGCP" SG_ 1578 OBC_Pilot 0;
BA_ "GenSigTimeoutTime_MCPB" SG_ 1578 OBC_Pilot 0;
BA_ "GenSigTimeoutTime_MCPA" SG_ 1578 OBC_Pilot 0;
BA_ "GenSigTimeoutTime_IDCM" SG_ 1578 OBC_Pilot 0;
BA_ "GenSigTimeoutTime_ECM" SG_ 1578 OBCM_PrechargeSts 0;
BA_ "GenSigTimeoutTime_BPCM" SG_ 1578 OBCM_PrechargeSts 0;
BA_ "GenSigTimeoutTime_SGCP" SG_ 1578 OBCM_PrechargeSts 0;
BA_ "GenSigTimeoutTime_MCPB" SG_ 1578 OBCM_PrechargeSts 0;
BA_ "GenSigTimeoutTime_MCPA" SG_ 1578 OBCM_PrechargeSts 0;
BA_ "GenSigTimeoutTime_IDCM" SG_ 1578 OBCM_PrechargeSts 0;
BA_ "GenSigTimeoutTime_ECM" SG_ 1578 ChrgFailSts 0;
BA_ "GenSigTimeoutTime_BPCM" SG_ 1578 ChrgFailSts 0;
BA_ "GenSigTimeoutTime_SGCP" SG_ 1578 ChrgFailSts 0;
BA_ "GenSigTimeoutTime_MCPB" SG_ 1578 ChrgFailSts 0;
BA_ "GenSigTimeoutTime_MCPA" SG_ 1578 ChrgFailSts 0;
BA_ "GenSigTimeoutTime_IDCM" SG_ 1578 ChrgFailSts 0;
BA_ "GenSigTimeoutTime_ECM" SG_ 2654486653 CBV_bit1_1E38407D 0;
BA_ "GenSigTimeoutTime_BPCM" SG_ 2654486653 CBV_bit1_1E38407D 0;
BA_ "GenSigTimeoutTime_SGCP" SG_ 2654486653 CBV_bit1_1E38407D 0;
BA_ "GenSigTimeoutTime_MCPB" SG_ 2654486653 CBV_bit1_1E38407D 0;
BA_ "GenSigTimeoutTime_MCPA" SG_ 2654486653 CBV_bit1_1E38407D 0;
BA_ "GenSigTimeoutTime_IDCM" SG_ 2654486653 CBV_bit1_1E38407D 0;
BA_ "GenSigTimeoutTime_EVCU2" SG_ 2654486653 CBV_bit1_1E38407D 0;
BA_ "GenSigTimeoutTime_ECM" SG_ 2654486653 CBV_bit2_1E38407D 0;
BA_ "GenSigTimeoutTime_BPCM" SG_ 2654486653 CBV_bit2_1E38407D 0;
BA_ "GenSigTimeoutTime_SGCP" SG_ 2654486653 CBV_bit2_1E38407D 0;
BA_ "GenSigTimeoutTime_MCPB" SG_ 2654486653 CBV_bit2_1E38407D 0;
BA_ "GenSigTimeoutTime_MCPA" SG_ 2654486653 CBV_bit2_1E38407D 0;
BA_ "GenSigTimeoutTime_IDCM" SG_ 2654486653 CBV_bit2_1E38407D 0;
BA_ "GenSigTimeoutTime_EVCU2" SG_ 2654486653 CBV_bit2_1E38407D 0;
BA_ "GenSigTimeoutTime_ECM" SG_ 2654486653 CBV_bit5_1E38407D 0;
BA_ "GenSigTimeoutTime_BPCM" SG_ 2654486653 CBV_bit5_1E38407D 0;
BA_ "GenSigTimeoutTime_SGCP" SG_ 2654486653 CBV_bit5_1E38407D 0;
BA_ "GenSigTimeoutTime_MCPB" SG_ 2654486653 CBV_bit5_1E38407D 0;
BA_ "GenSigTimeoutTime_MCPA" SG_ 2654486653 CBV_bit5_1E38407D 0;
BA_ "GenSigTimeoutTime_IDCM" SG_ 2654486653 CBV_bit5_1E38407D 0;
BA_ "GenSigTimeoutTime_EVCU2" SG_ 2654486653 CBV_bit5_1E38407D 0;
BA_ "GenSigTimeoutTime_ECM" SG_ 2654486653 CBV_bit0_RepeatMessageRequestBit_1E38407D 0;
BA_ "GenSigTimeoutTime_BPCM" SG_ 2654486653 CBV_bit0_RepeatMessageRequestBit_1E38407D 0;
BA_ "GenSigTimeoutTime_SGCP" SG_ 2654486653 CBV_bit0_RepeatMessageRequestBit_1E38407D 0;
BA_ "GenSigTimeoutTime_MCPB" SG_ 2654486653 CBV_bit0_RepeatMessageRequestBit_1E38407D 0;
BA_ "GenSigTimeoutTime_MCPA" SG_ 2654486653 CBV_bit0_RepeatMessageRequestBit_1E38407D 0;
BA_ "GenSigTimeoutTime_IDCM" SG_ 2654486653 CBV_bit0_RepeatMessageRequestBit_1E38407D 0;
BA_ "GenSigTimeoutTime_EVCU2" SG_ 2654486653 CBV_bit0_RepeatMessageRequestBit_1E38407D 0;
BA_ "GenSigTimeoutTime_MCPA" SG_ 2654486653 SourceNodeIdentifier_1E38407D 0;
BA_ "GenSigTimeoutTime_IDCM" SG_ 2654486653 SourceNodeIdentifier_1E38407D 0;
BA_ "GenSigTimeoutTime_EVCU2" SG_ 2654486653 SourceNodeIdentifier_1E38407D 0;
BA_ "GenSigTimeoutTime_ECM" SG_ 2654486653 CBV_bit3_NMCoordinatorBit_1E38407D 0;
BA_ "GenSigTimeoutTime_BPCM" SG_ 2654486653 CBV_bit3_NMCoordinatorBit_1E38407D 0;
BA_ "GenSigTimeoutTime_SGCP" SG_ 2654486653 CBV_bit3_NMCoordinatorBit_1E38407D 0;
BA_ "GenSigTimeoutTime_MCPB" SG_ 2654486653 CBV_bit3_NMCoordinatorBit_1E38407D 0;
BA_ "GenSigTimeoutTime_MCPA" SG_ 2654486653 CBV_bit3_NMCoordinatorBit_1E38407D 0;
BA_ "GenSigTimeoutTime_IDCM" SG_ 2654486653 CBV_bit3_NMCoordinatorBit_1E38407D 0;
BA_ "GenSigTimeoutTime_EVCU2" SG_ 2654486653 CBV_bit3_NMCoordinatorBit_1E38407D 0;
BA_ "GenSigTimeoutTime_SGCP" SG_ 2654486653 CBV_bit4_ActiveWakeupBit_1E38407D 0;
BA_ "GenSigTimeoutTime_MCPB" SG_ 2654486653 CBV_bit4_ActiveWakeupBit_1E38407D 0;
BA_ "GenSigTimeoutTime_MCPA" SG_ 2654486653 CBV_bit4_ActiveWakeupBit_1E38407D 0;
BA_ "GenSigTimeoutTime_IDCM" SG_ 2654486653 CBV_bit4_ActiveWakeupBit_1E38407D 0;
BA_ "GenSigTimeoutTime_EVCU2" SG_ 2654486653 CBV_bit4_ActiveWakeupBit_1E38407D 0;
BA_ "GenSigTimeoutTime_ECM" SG_ 2654486653 CBV_bit4_ActiveWakeupBit_1E38407D 0;
BA_ "GenSigTimeoutTime_BPCM" SG_ 2654486653 CBV_bit4_ActiveWakeupBit_1E38407D 0;
BA_ "GenSigTimeoutTime_ECM" SG_ 2654486653 CBV_bit6_PartialNtwInfBit_1E38407D 0;
BA_ "GenSigTimeoutTime_BPCM" SG_ 2654486653 CBV_bit6_PartialNtwInfBit_1E38407D 0;
BA_ "GenSigTimeoutTime_SGCP" SG_ 2654486653 CBV_bit6_PartialNtwInfBit_1E38407D 0;
BA_ "GenSigTimeoutTime_MCPB" SG_ 2654486653 CBV_bit6_PartialNtwInfBit_1E38407D 0;
BA_ "GenSigTimeoutTime_MCPA" SG_ 2654486653 CBV_bit6_PartialNtwInfBit_1E38407D 0;
BA_ "GenSigTimeoutTime_IDCM" SG_ 2654486653 CBV_bit6_PartialNtwInfBit_1E38407D 0;
BA_ "GenSigTimeoutTime_EVCU2" SG_ 2654486653 CBV_bit6_PartialNtwInfBit_1E38407D 0;
VAL_ 1328 EngTorqCapbltyMinTorq 4095 "SNA";
VAL_ 1328 EngTorqCapbltyMaxTorq 4095 "SNA";
VAL_ 1328 EngTorqCapbltyMaxOffTorq 4095 "SNA";
VAL_ 1053 VIN_MSG 0 "VIN_LO" 1 "VIN_MID" 2 "VIN_HI" 3 "SNA";
VAL_ 1626 IMPACTConfirm 0 "Actuate" 1 "Do_Not_Actuate";
VAL_ 1626 IMPACTCommand 0 "Do_Not_Actuate" 1 "Actuate";
VAL_ 1155 ESCFailSts 0 "Fail_Not_Present" 1 "Fail_Present";
VAL_ 1155 ABSFailSts 0 "Fail_Not_Present" 1 "Fail_Present";
VAL_ 609 EPBSts 0 "Released" 1 "Applied" 2 "DynamicBrkESC" 3 "DynamicBrkEPB" 4 "Emergency_Braking" 5 "Applying" 6 "Maintenance_Mode" 7 "Assembly_Check" 8 "Inspection_Mode" 9 "Re_Clamping" 10 "Adjuste_Mode" 11 "Releasing" 12 "Fault_EPB_Released" 13 "Fault_EPB_Applied" 14 "Fault_Present" 15 "SNA";
VAL_ 256 OperationalModeSts 0 "Initialization" 1 "Ignition_Off_WithoutKey" 2 "Ignition_Off" 3 "Ignition_Acc" 4 "Ignition_On" 5 "Ignition_Pre_Start" 6 "Ignition_Start" 7 "Ignition_Cranking" 8 "Ignition_On_EngOn" 9 "Ignition_Pre_Acc" 10 "Ignition_Pre_Off" 11 "Automatic_Cranking" 12 "Automatic_Stop" 13 "Key_Authenticated" 14 "Not_Used" 15 "SNA";
VAL_ 1153 ExternalTemperatureC 511 "SNA";
VAL_ 1153 CmdIgnSts 0 "Initialization" 1 "IGN_LK" 3 "ACC" 4 "RUN" 5 "START" 7 "SNA";
VAL_ 1033 IdleCLoopTrq 1023 "SNA";
VAL_ 1033 HCPMaxEngRPM 255 "SNA";
VAL_ 1328 EngTorqCapbltyMinRunTorq 4095 "SNA";
VAL_ 1328 EngTorqACCCapability 255 "SNA";
VAL_ 518 RPMOverRev_W 0 "FALSE" 1 "TRUE";
VAL_ 1054 ThermalManagementActive_W 0 "Not_active" 1 "Active";
VAL_ 1066 ExternalTemperature 511 "SNA";
VAL_ 750 Battery_Volt_1 511 "SNA";
VAL_ 262 PowertrainPrplsnActv 0 "Off" 1 "Active";
VAL_ 262 EngineSpeedFailSts_W 0 "Fail_not_present" 1 "Fail_present";
VAL_ 262 EngineSpeed_W 16383 "SNA";
VAL_ 258 VehicleSpeedVSOSig 8191 "SNA";
VAL_ 258 LongAccelerationFailSts_BSM 0 "Fail_Not_Present" 1 "Fail_Present";
VAL_ 258 LongAcceleration_BSM 4095 "SNA";
VAL_ 258 LatAccelerationFailSts_BSM 0 "Fail_Not_Present" 1 "Fail_Present";
VAL_ 258 LatAcceleration_BSM 4095 "SNA";
VAL_ 258 ESCActive 0 "Not_active" 1 "Active";
VAL_ 258 ABSActive 0 "Not_active" 1 "Active";
VAL_ 1579 HVBatteryVoltage_MinCal 511 "SNA";
VAL_ 1579 HVBatteryVoltage_MaxCal 511 "SNA";
VAL_ 1579 HVBatteryCurrent_MaxCal 255 "SNA";
VAL_ 156 GPS_Date_Day 255 "SNA";
VAL_ 276 PropulsionSystemActive 0 "Not_Active" 1 "Active";
VAL_ 1460 FOTA_Status 0 "No FOTA Event" 1 "Downloading Package from Backend" 2 "Passing Images to Big Target ECUs" 3 "Waiting for HMI Acceptance" 4 "Installing FOTA Updated" 5 "Successful FOTA Update" 6 "FOTA Failure Rollback Successful" 7 "FOTA Failure Complete" 8 "Build Vehicle Library" 9 "Check Campaign Availability" 10 "Check Download Conditions" 11 "Validate Vehicle Package" 12 "Double Check Manifest" 13 "Initiate Authenticated Diagnostic session" 14 "Ready_State" 15 "Rollback";
VAL_ 1579 ChargingLevel 0 "Default_NoLevel" 1 "Level_1_AC" 2 "Level_2_AC" 3 "Level_3_AC" 4 "Level_1_DC" 5 "Level_2_DC" 6 "PlugInNotDet" 7 "PPI_1_No_Drive" 8 "PPI_2_OK_Drive" 15 "SNA";
VAL_ 478 OBC_ControlMethod 0 "CURRENT" 1 "VOLTAGE" 2 "POWER" 3 "SNA";
VAL_ 478 J1772_CloseS2 0 "OPN" 1 "CLS";
VAL_ 478 HVBatCoolantLevelLow 0 "FALSE" 1 "TRUE" 3 "SNA";
VAL_ 502 HVCMS_ServiceScope 65535 "SNA";
VAL_ 502 HVCMS_ReadyToChargeState 0 "Not_Ready" 1 "Ready";
VAL_ 502 HVCMS_Protocol_Entry3 65535 "SNA";
VAL_ 502 HVCMS_Protocol_Entry2 65535 "SNA";
VAL_ 502 HVCMS_Protocol_Entry1 65535 "SNA";
VAL_ 502 HVCMS_EVTargetVoltage 16383 "SNA";
VAL_ 502 HVCMS_EVTargetCurrent 1023 "SNA";
VAL_ 502 HVCMS_EVRESS_SOC 4095 "SNA";
VAL_ 502 HVCMS_EVReady 0 "Not_Ready" 1 "Ready";
VAL_ 502 HVCMS_EVMax_V_Limit 16383 "SNA";
VAL_ 502 HVCMS_EVMax_P_Limit 16777215 "SNA";
VAL_ 502 HVCMS_EVMax_I_Limit 1023 "SNA";
VAL_ 502 HVCMS_EVEnergyCapacity 131071 "SNA";
VAL_ 502 HVCMS_ChargingComplete 0 "Not_Completed" 1 "Completed";
VAL_ 502 HVCMS_BulkChargingComplete 0 "Not_Completed" 1 "Completed";
VAL_ 242 INVFInterlockSts 0 "Not_Performed" 1 "OK" 2 "Fail" 3 "Invalid";
VAL_ 242 InvF_DC_Voltage 1023 "SNA";
VAL_ 498 HVCMS_EVSEPresentVoltage 16383 "SNA";
VAL_ 498 HVCMS_EVSEPeakCurrentRipple 1023 "SNA";
VAL_ 498 HVCMS_EVSEMinCurrentLimit 1023 "SNA";
VAL_ 498 HVCMS_EVSEMaxPowerLimit 16777215 "SNA";
VAL_ 498 HVCMS_EVSEMaxCurrentLimit 1023 "SNA";
VAL_ 498 HVCMS_EVSECurrRegulationTol 1023 "SNA";
VAL_ 498 HVCMS_EnergyToBeDelivered 131071 "SNA";
VAL_ 1579 ChargeSystemFaultReason 0 "No_Failure" 1 "Failure1" 2 "Failure2" 3 "Failure3" 4 "Failure4" 5 "Failure5" 6 "Failure6" 7 "Failure7" 8 "Failure8" 9 "Failure9" 10 "Failure10" 11 "Failure11" 12 "Failure12" 13 "Failure13" 14 "Failure14" 15 "Failure15" 16 "Failure16" 17 "Failure17" 18 "Failure18" 19 "Failure19" 20 "Failure20" 21 "Failure21" 22 "Failure22" 23 "Failure23" 24 "Failure24" 25 "Failure25" 26 "Failure26" 27 "Failure27" 28 "Failure28" 29 "Failure29" 30 "Failure30" 31 "Failure31" 32 "Failure32" 33 "Failure33" 34 "Failure34" 35 "Failure35" 36 "Failure36" 37 "Failure37" 38 "Failure38" 39 "Failure39" 40 "Failure40" 41 "Failure41" 42 "Failure42" 43 "Failure43" 44 "Failure44" 45 "Failure45" 46 "Failure46" 47 "Failure47" 48 "Failure48" 49 "Failure49" 50 "Failure50" 51 "Failure51" 52 "Failure52" 53 "Failure53" 54 "Failure54" 55 "Failure55" 56 "Failure56" 57 "Failure57" 58 "Failure58" 59 "Failure59" 60 "Failure60" 61 "Failure61" 62 "Failure62" 63 "Failure63" 64 "Failure64" 65 "Failure65" 66 "Failure66" 67 "Failure67" 68 "Failure68" 69 "Failure69" 70 "Failure70" 71 "Failure71" 72 "Failure72" 73 "Failure73" 74 "Failure74" 75 "Failure75" 76 "Failure76" 77 "Failure77" 78 "Failure78" 79 "Failure79" 80 "Failure80" 81 "Failure81" 82 "Failure82" 83 "Failure83" 84 "Failure84" 85 "Failure85" 86 "Failure86" 87 "Failure87" 88 "Failure88" 89 "Failure89" 90 "Failure90" 91 "Failure91" 92 "Failure92" 93 "Failure93" 94 "Failure94" 95 "Failure95" 96 "Failure96" 97 "Failure97" 98 "Failure98" 99 "Failure99" 100 "Failure100" 101 "Failure101" 102 "Failure102" 103 "Failure103" 104 "Failure104" 105 "Failure105" 106 "Failure106" 107 "Failure107" 108 "Failure108" 109 "Failure109" 110 "Failure110" 111 "Failure111" 112 "Failure112" 113 "Failure113" 114 "Failure114" 115 "Failure115" 116 "Failure116" 117 "Failure117" 118 "Failure118" 119 "Failure119" 120 "Failure120" 121 "Failure121" 122 "Failure122" 123 "Failure123" 124 "Failure124" 125 "Failure125" 126 "Failure126" 127 "Failure127" 128 "Failure128" 129 "Failure129" 130 "Failure130" 131 "Failure131" 132 "Failure132" 133 "Failure133" 134 "Failure134" 135 "Failure135" 136 "Failure136" 137 "Failure137" 138 "Failure138" 139 "Failure139" 140 "Failure140" 141 "Failure141" 142 "Failure142" 143 "Failure143" 144 "Failure144" 145 "Failure145" 146 "Failure146" 147 "Failure147" 148 "Failure148" 149 "Failure149" 150 "Failure150" 151 "Failure151" 152 "Failure152" 153 "Failure153" 154 "Failure154" 155 "Failure155" 156 "Failure156" 157 "Failure157" 158 "Failure158" 159 "Failure159" 160 "Failure160" 161 "Failure161" 162 "Failure162" 163 "Failure163" 164 "Failure164" 165 "Failure165" 166 "Failure166" 167 "Failure167" 168 "Failure168" 169 "Failure169" 170 "Failure170" 171 "Failure171" 172 "Failure172" 173 "Failure173" 174 "Failure174" 175 "Failure175" 176 "Failure176" 177 "Failure177" 178 "Failure178" 179 "Failure179" 180 "Failure180" 181 "Failure181" 182 "Failure182" 183 "Failure183" 184 "Failure184" 185 "Failure185" 186 "Failure186" 187 "Failure187" 188 "Failure188" 189 "Failure189" 190 "Failure190" 191 "Failure191" 192 "Failure192" 193 "Failure193" 194 "Failure194" 195 "Failure195" 196 "Failure196" 197 "Failure197" 198 "Failure198" 199 "Failure199" 200 "Failure200" 201 "Failure201" 202 "Failure202" 203 "Failure203" 204 "Failure204" 205 "Failure205" 206 "Failure206" 207 "Failure207" 208 "Failure208" 209 "Failure209" 210 "Failure210" 211 "Failure211" 212 "Failure212" 213 "Failure213" 214 "Failure214" 215 "Failure215" 216 "Failure216" 217 "Failure217" 218 "Failure218" 219 "Failure219" 220 "Failure220" 221 "Failure221" 222 "Failure222" 223 "Failure223" 224 "Failure224" 225 "Failure225" 226 "Failure226" 227 "Failure227" 228 "Failure228" 229 "Failure229" 230 "Failure230" 231 "Failure231" 232 "Failure232" 233 "Failure233" 234 "Failure234" 235 "Failure235" 236 "Failure236" 237 "Failure237" 238 "Failure238" 239 "Failure239" 240 "Failure240" 241 "Failure241" 242 "Failure242" 243 "Failure243" 244 "Failure244" 245 "Failure245" 246 "Failure246" 247 "Failure247" 248 "Failure248" 249 "Failure249" 250 "Failure250" 251 "Failure251" 252 "Failure252" 253 "Failure253" 254 "Failure254" 255 "SNA";
VAL_ 1579 ACCurrent_MaxCal 511 "SNA";
VAL_ 1034 HVBatSleepTime 255 "SNA";
VAL_ 1578 OBC_IdleTimeSec 65535 "SNA";
VAL_ 1578 OBC_IdleTimeMin 65535 "SNA";
VAL_ 1578 OBC_ChargeTimeSec 65535 "SNA";
VAL_ 1578 OBC_ChargeTimeMin 65535 "SNA";
VAL_ 1578 Charging_WHr 65535 "SNA";
VAL_ 1372 OBC_Temp4 255 "SNA";
VAL_ 1372 OBC_Temp3 255 "SNA";
VAL_ 1372 OBC_Temp2 255 "SNA";
VAL_ 1372 OBC_Temp1 255 "SNA";
VAL_ 520 GearEngagedForDisplay 0 "Initialize" 1 "1st_gear" 2 "2nd_gear" 3 "3rd_gear" 4 "4th_gear" 5 "5th_gear" 6 "6th_gear" 7 "7th_gear" 8 "8th_gear " 9 "9th_gear" 10 "Not_used1" 11 "Not_Used2" 12 "P" 13 "N" 14 "R" 15 "D" 16 "L" 17 "M" 18 "S" 31 "SNA";
VAL_ 156 GPS_UTC_Second 65535 "SNA";
VAL_ 156 GPS_UTC_Minute 255 "SNA";
VAL_ 156 GPS_UTC_Hour 255 "SNA";
VAL_ 156 GPS_Date_Year 65535 "SNA";
VAL_ 156 GPS_Date_Month 255 "SNA";
VAL_ 498 EVSE_IsolationSts 0 "GFD_Not_Performed" 1 "GFD_Ok" 2 "GFD_Fail" 3 "GFD_Invalid" 4 "GFD_Warning" 7 "SNA";
VAL_ 498 DC_TimeOut 0 "FALSE" 1 "TRUE";
VAL_ 498 DC_Isolation_Disable_Cmd 0 "FALSE" 1 "TRUE";
VAL_ 1579 OBCM_PLUG_STS 0 "NOT_PLUG_IN" 1 "PLUG_IN";
VAL_ 478 OBC_OperativeModeReq 0 "IDLE" 1 "HEATER" 2 "CHARGE" 3 "Discharge" 4 "AC_GRD_Sync" 5 "AC_GRD_Synth" 6 "CHARGE_INTERRUPTED" 7 "NOT_CHARGING" 15 "SNA";
VAL_ 478 HV_Volt_Min_Thrsh 2047 "SNA";
VAL_ 478 HV_Volt_Max_Thrsh 2047 "SNA";
VAL_ 478 DC_Curr_Max_Thrsh 1023 "SNA";
VAL_ 478 ChargeEnable 0 "Charge_Not_Enabled" 1 "Charge_Enabled" 3 "SNA";
VAL_ 478 AC_Curr_Min_Thrsh 1023 "SNA";
VAL_ 478 AC_Curr_Max_Thrsh 1023 "SNA";
VAL_ 1578 OnboardChargerReady 0 "WU_FLT" 1 "OFF" 2 "ON" 3 "SNA";
VAL_ 1578 OnboardChargerMode 0 "IDLE" 1 "HEATER" 2 "CHARGE" 3 "Discharge" 4 "AC_GRD" 5 "UTC" 6 "STOP" 7 "FORCED_SHUTDOWN" 8 "CHARGE_INTERRUPTED" 9 "NOT_CHARGING";
VAL_ 1578 OBC_WakeReason 0 "NOT_DETECTED" 1 "Master_WU" 2 "EVSE_PlugIn" 3 "Pilot_PWM" 4 "Prox_in" 5 "EVSE_UnPlug" 6 "s3_open" 7 "BPCM_WU";
VAL_ 1578 OBC_GenericFailSts 0 "Fail_Not_Present" 1 "Fail_Present";
VAL_ 1578 OBC_FaultReason 0 "No_Fault" 1 "COMM_FAULT" 2 "EVSE_InputCirFault" 3 "Batt_12vFault" 4 "OBCM_LV_Fault" 5 "OBCM_HV_Fault" 6 "Extern_Dev_Fault" 7 "WakeupCircuitFault" 8 "Impact" 9 "DischargeFault" 127 "SNA";
VAL_ 1578 OBC_ChargingFaultSts 0 "No_Performed" 1 "No_Fault" 2 "OBCM_ECU_HW_Error" 3 "OBCM_Modules_Error" 4 "Gnd_Fault" 5 "Temperature_Error" 6 "OverCurrent_Error" 7 "OverVoltage_Error";
VAL_ 1578 ACplug_PwrMax 65535 "SNA";
VAL_ 276 DriveReady 0 "Default" 1 "Vehicle is allowed to shift out of park or neutral";
VAL_ 502 VDCM_TypeCNegotiationSts 0 "Not_Requested" 1 "Ongoing" 2 "OK" 3 "Not_OK";
VAL_ 502 HVCMS_EVEnergyRequest 131071 "SNA";
VAL_ 242 InvF_DerateReason 0 "Reason1" 1 "Reason2" 2 "Reason3" 3 "Reason4" 4 "Reason5" 5 "Reason6" 6 "Reason7" 7 "Reason8" 8 "Reason9" 9 "Reason10" 10 "Reason11" 11 "Reason12" 12 "Reason13" 13 "Reason14" 14 "Reason15" 15 "Reason16";
VAL_ 498 OBCM_PLCTypeSts 0 "Not determinated" 1 "Basic signaling communication" 2 "HLC" 7 "SNA";
VAL_ 498 HVCMS_EVSEVoltageLimitAchieved 0 "No_limit_ach" 1 "Limit_ach" 2 "Init" 3 "SNA";
VAL_ 498 HVCMS_EVSEPowerLimitAchieved 0 "No_limit_ach" 1 "Limit_ach" 2 "Init" 3 "SNA";
VAL_ 498 HVCMS_EVSEMinimumVoltageLimit 65535 "SNA";
VAL_ 498 HVCMS_EVSEMaximumVoltageLimit 65535 "SNA";
VAL_ 498 HVCMS_EVSECurrentLimitAchieved 0 "No_limit_ach" 1 "Limit_ach" 2 "Init" 3 "SNA";
VAL_ 1579 ChargeSystemSts 0 "NotCharging" 1 "Charging" 2 "ChargeInterrupted" 3 "ChargeComplete" 4 "ChargeError" 7 "SNA";
VAL_ 1579 ChargeSystemFault 0 "No_Fail" 1 "Fail";
VAL_ 753 IDCM_Wakeup_HCP 0 "No_Event" 1 "WakeUp_Event";
VAL_ 502 OBCM_OutVoltageSyncTgt 1023 "SNA";
VAL_ 242 MCPA_TorqAchieved_AEMD_V 0 "Valid" 1 "Invalid";
VAL_ 242 MCPA_RPM_V 0 "Valid" 1 "Invalid";
VAL_ 242 MCPA_MtrMinCpbltyTrq 8191 "SNA";
VAL_ 242 MCPA_MtrMaxCpbltyTrq 8191 "SNA";
VAL_ 242 MCPA_MtrIndex 31 "SNA";
VAL_ 242 MCPA_MinTorq 8191 "SNA";
VAL_ 242 MCPA_MaxTorq 8191 "SNA";
VAL_ 242 MCPA_Invrtr_State 0 "NORMAL_POWER_STAGE_OFF " 1 "NORMAL_POWER_STAGE_ON " 2 "NORMAL_POWER_STAGE_OVERRIDE" 3 "ACTIVE_DISCHARGE " 4 "INVERTER_FAULTED " 5 "NORMAL_POWER_STAGE_OFF_HV_RQD" 6 "NORMAL_VC_PRIMING" 7 "NORMAL_VC_ON";
VAL_ 242 MCPA_HV_CnctrOpn_Req 0 "False" 1 "True";
VAL_ 242 MCPA_Dschrge_Status 0 "AD_INDETERMINATE" 1 "AD_INPROGRESS" 2 "AD_COMPLETE" 3 "AD_FAILED";
VAL_ 242 MCPA_DeratingFactor 63 "SNA";
VAL_ 242 MCPA_DC_Volt_V 0 "Valid" 1 "Invalid";
VAL_ 242 MCPA_DC_Current_V 0 "Valid" 1 "Invalid";
VAL_ 242 MCPA_CpbltySpdDivVolt 65535 "SNA";
VAL_ 242 MCPA_AccelRawV 0 "Valid" 1 "Invalid";
VAL_ 242 MCPA_6SO_Status 0 "3PS" 1 "6SO" 2 "Switching" 3 "SNA";
VAL_ 242 MCPA_3PS_Pos 0 "False" 1 "True";
VAL_ 498 HVCMS_EVSEPresentCurrent 65535 "SNA";
VAL_ 498 EVSE_OfferedEnergyTransferType 0 "NotAvailable" 1 "AC_single_phase_core" 2 "AC_three_phase_core" 3 "DC_core" 4 "DC_extended" 5 "DC_combo_core" 6 "DC_unique";
VAL_ 478 VDCM_StsWldgReq 0 "No_WeldingCheck_Req" 1 "WeldingCheck_Req";
VAL_ 478 VDCM_SessnStopReq 0 "No_SessStop_Req" 1 "SessStop_Req";
VAL_ 2654486653 CBV_bit0_RepeatMessageRequestBit_1E38407D 0 "Repeat Message State not requested" 1 "Repeat Message State requested";
VAL_ 2654486653 CBV_bit3_NMCoordinatorBit_1E38407D 0 "Start of synchronized shutdown is not requested by main coordinator" 1 "Start of synchronized shutdown is requested by main coordinator";
VAL_ 2654486653 CBV_bit4_ActiveWakeupBit_1E38407D 0 "PassiveWakeup" 1 "ActiveWakeup";
VAL_ 2654486653 CBV_bit6_PartialNtwInfBit_1E38407D 0 "NM PDU contains no Partial Network request information" 1 "NM PDU contains Partial Network request information";
VAL_ 2654486529 CBV_bit0_RepeatMessageRequestBit_1E384001 0 "Repeat_Message_State_not_requested" 1 "Repeat_Message_State_requested";
VAL_ 2654486529 CBV_bit3_NMCoordinatorBit_1E384001 0 "Start_of_synchronized_shutdown_is_not_requested_by_main_coordinator" 1 "Start_of_synchronized_shutdown_is_requested_by_main_coordinator";
VAL_ 2654486529 CBV_bit4_ActiveWakeupBit_1E384001 0 "PassiveWakeup" 1 "ActiveWakeup";
VAL_ 2654486529 CBV_bit6_PartialNtwInfBit_1E384001 0 "NM_PDU_contains_no_Partial_Network_request_information" 1 "NM_PDU_contains_Partial_Network_request_information";
VAL_ 2654486598 CBV_bit0_RepeatMessageRequestBit_1E384046 0 "Repeat Message State not requested" 1 "Repeat Message State requested";
VAL_ 2654486598 CBV_bit3_NMCoordinatorBit_1E384046 0 "Start of synchronized shutdown is not requested by main coordinator" 1 "Start of synchronized shutdown is requested by main coordinator";
VAL_ 2654486598 CBV_bit4_ActiveWakeupBit_1E384046 0 "PassiveWakeup" 1 "ActiveWakeup";
VAL_ 2654486598 CBV_bit6_PartialNtwInfBit_1E384046 0 "NM PDU contains no Partial Network request information" 1 "NM PDU contains Partial Network request information";
VAL_ 242 InvF_CoolantTemp 2047 "SNA";
VAL_ 498 HVCMS_TxMessageStat 0 "NoRequest" 1 "SupportedAppProtocolReq" 2 "SessionSetupReq" 3 "ServiceDiscoveryReq" 4 "ServiceDetailReq" 5 "PaymentServiceSelectionReq" 6 "PaymentDetailsReq" 7 "AuthorizationReq" 8 "ChargeParameterDiscoveryReq" 9 "PowerDeliveryReq" 10 "CertificateUpdateReq" 11 "CertificateInstallationReq" 12 "SessionStopReq" 13 "MeteringReceiptReq" 14 "ChargingStatusReq" 15 "CableCheckReq" 16 "PreChargeReq" 17 "CurrentDemandReq" 18 "WeldingDetectionReq" 19 "Contract_AuthenticationReq" 20 "PowerDeliveryReq_Precharge" 21 "PowerDeliveryReq_EnergyTransfer" 22 "DC_BidirectionalControlReq" 23 "PowerDeliveryReq_Renegotiation" 24 "ChargeParameterDiscovery_Reneg" 31 "SNA";
VAL_ 498 HVCMS_ResponseCode 0 "OK" 1 "OK_CertificateExpiresSoon" 2 "OK_NewSessionEstablished" 3 "OK_OldSessionJoined" 4 "FAILED" 5 "FAILED_SequenceError" 6 "FAILED_SignatureError" 7 "FAILED_UnknownSession" 8 "FAILED_ServiceIDInvalid" 9 "FAILED_PaymentSelectionInvalid" 10 "FAILED_ServiceSelectionInvalid" 11 "FAILED_CertificateExpired" 12 "FAILED_NoCertificateAvailable" 13 "FAILED_CertChainError" 14 "FAILED_ContractCanceled" 15 "FAILED_ChallengeInvalid" 16 "FAILED_WrongEnergyTransferType" 17 "FAILED_WrongChargeParameter" 18 "FAILED_ChargingProfileInvalid" 19 "FAILED_TariffSelectionInvalid" 20 "FAILED_EVSEPresentVoltageToLow" 21 "FAILED_PowerDeliveryNotApplied" 22 "FAILED_MeteringSignatureNotValid" 23 "OK_SuccessfullNegotiation" 24 "OK_SucceedNegotiatnMinorDeviatn" 25 "Failed_NoNegotiation" 31 "SNA";
VAL_ 498 HVCMS_EVSEProcessing 0 "Ongoing" 1 "Finished";
VAL_ 498 EVSE_FreeService 0 "Paid_Service" 1 "Free_Service";
VAL_ 478 VDCM_StsSWWldgReq 0 "No_SWWeldingCheck_Req" 1 "SWWeldingCheck_Req";
VAL_ 1578 OBCM_PrechargeSts 0 "Not_Requested" 1 "Ongoing" 2 "Completed" 3 "Fail";
VAL_ 502 HVCMS_ServiceCategory 0 "No_Service" 1 "EV_charging" 2 "Internet" 3 "VAS" 4 "BPT_Service" 5 "WPT_Service" 6 "ACDC_Service" 7 "Contract_Certificate" 8 "EVSEInformation" 15 "SNA";
VAL_ 502 HVCMS_SelectedPaymentOptn 0 "No payment selected" 1 "External Payment" 2 "Contract" 3 "SNA";
VAL_ 502 HVCMS_SelectedEnergyTransferType 0 "No_energy_transfer_type" 1 "AC_single_phase_core" 2 "AC_three_phase_core" 3 "DC_core" 4 "DC_Extended" 5 "DC_combo_core" 6 "DC_unique" 15 "SNA";
VAL_ 502 HVCMS_RemaningTimeToFullSOC 65535 "SNA";
VAL_ 502 HVCMS_RemaningTimeToBulkSOC 65535 "SNA";
VAL_ 502 HVCMS_EVErrorCode 0 "No_error" 1 "FAILED_RESSTTemperatureInhibit" 2 "FAILED_EVShiftPosition" 3 "FAILED_ChargerConnectorLockFault" 4 "FAILED_EVRESSMalfunction" 5 "FAILED_ChargingCurrentDifferential" 6 "FAILED_ChargingcurrentvoltageOutOfRange" 7 "Failed_InletHot" 8 "FAILED_ChargingSystemIncompatibility" 15 "SNA";
VAL_ 242 MCPA_Torque_Achieved_V 0 "Valid" 1 "Invalid";
VAL_ 242 MCPA_SPT_Stat 0 "Undetermined " 1 "Passed" 2 "Failed";
VAL_ 498 TxMessageResponse 0 "No_V2G_communication_initialized" 1 "SupportedAppProtocolRes" 2 "SessionSetupRes" 3 "ServiceDiscoveryRes" 4 "ServicePaymentSelectionRes" 5 "Contract_AuthenticationRes" 6 "ChargeParameterDiscoveryRes" 7 "CableCheckRes" 8 "Pre_chargeRes" 9 "PowerDeliveryRes_Precharge" 10 "CurrentDemandRes" 11 "PowerDeliveryRes_EnergyTransfer" 12 "WeldingDetectionRes" 13 "SessionStopRes" 14 "DC_BidirectionalControlRes" 15 "ServiceDetailRes" 16 "PaymentDetailsRes" 17 "AuthorizationRes" 18 "CertificateInstallationRes" 19 "CertificateUpdateRes" 20 "MeteringReceiptRes" 21 "PowerDeliveryReq_Renegotiation" 22 "ChargeParameterDiscovery_Reneg" 31 "SNA";
VAL_ 498 HVCMS_EVSEStatusCode 0 "Charger_standby not ready" 1 "Charger ready charging" 2 "Charger prepaid limits exceeded" 3 "Charger shutdown" 4 "Utility interrupt event" 5 "Isolation monitoring internal" 6 "Isolation monitoring active" 7 "Charger emergency shutdown" 8 "Reserved" 9 "Reserved" 10 "Reserved" 11 "Reserved" 12 "Reserved" 13 "Charging system incompatibility" 14 "Charger malfunction" 15 "No_Data";
VAL_ 498 EVSE_OfferedService 0 "None" 1 "AC_DC_Charging" 2 "Certificate" 3 "InternetAccess" 4 "UseCaseInformation" 5 "Other";
VAL_ 498 EVSE_OfferedPaymentOptn 0 "No payment selected" 1 "External Payment" 2 "Contract" 3 "SNA";
VAL_ 1578 ChrgFailSts 0 "No_Fault" 1 "Flt_charging_allowed" 2 "Flt_charging_inhibited" 3 "Flt_charging_terminated" 4 "Flt_AC_failure_DC_chg_allwd" 7 "SNA";
VAL_ 1033 HCP_HoodAjar 0 "Closed" 1 "Ajar" 2 "Faulted" 3 "SNA";
VAL_ 271 RedSpkAuthorityAvbl 0 "Not_Available" 1 "Available";
VAL_ 271 EngMinSparkNomCurrAirTorqCap 2047 "SNA";
VAL_ 1032 SGCP_OIL_TEMP 255 "SNA";
VAL_ 1032 SGCP_OIL_FlwRate 255 "SNA";
VAL_ 1032 EOPB_OIL_TEMP 255 "SNA";
VAL_ 1032 EOPB_OIL_FlwRate 255 "SNA";
VAL_ 1032 EOPA_OIL_TEMP 255 "SNA";
VAL_ 1032 EOPA_OIL_FlwRate 255 "SNA";
VAL_ 498 EVSE_Supported_ISO1 0 "FALSE" 1 "TRUE";
VAL_ 498 EVSE_Supported_DIN 0 "FALSE" 1 "TRUE";
VAL_ 498 EVSE_Supported_SAE 0 "FALSE" 1 "TRUE";
VAL_ 498 EVSE_Service2_Certificate 0 "Not_Available" 1 "Available";
VAL_ 498 EVSE_OfferedPaymentEIM 0 "FALSE" 1 "TRUE";
VAL_ 498 EVSE_OfferedPaymentContract 0 "FALSE" 1 "TRUE";
VAL_ 498 EVSE_Notification 0 "None" 1 "StopCharging" 2 "ReNegotiation";

SIG_GROUP_ 1053 VIN_Pkt 1 : VIN_MSG VIN_DATA;
SIG_GROUP_ 520 TRANSM_FD_2_Pkt 1 : GearEngagedForDisplay;
SIG_GROUP_ 518 ENGINE_FD_5_Pkt 1 : RPMOverRev_W MessageCounter_ENGINE5 CRC_ENGINE5;
SIG_GROUP_ 1054 ENGINE_FD_1_Pkt 1 : ThermalManagementActive_W MessageCounter_ENGINE1 CRC_ENGINE1;
SIG_GROUP_ 753 LV_CHARGER1_Pkt 1 : IDCM_Wakeup_HCP;
SIG_GROUP_ 1033 HYBRID_POWERTRAIN5_Pkt 1 : IdleCLoopTrq HEV_HybPwrtrnRdcdPerfCmnd HCPMaxEngRPM CRC_HYBRID_POWERTRAIN5 MessageCounter_HYBRID_POWERTRAI_409 HCP_HoodAjar;
SIG_GROUP_ 1328 ENGINE_HYBD_FD_4_Pkt 1 : EngTorqCapbltyMinTorq EngTorqCapbltyMaxTorq EngTorqCapbltyMaxOffTorq EngTorqCapbltyRefEngSpd EngTorqCapbltyMinRunTorq EngTorqCapbltyFrmCntr EngTorqCapbltyEngOpMd EngTorqACCCapability MessageCounter_ENGINE_HYBD_FD_4 CRC_ENGINE_HYBD_FD_4;
SIG_GROUP_ 1035 ENGINE_HYBD_FD_3_Pkt 1 : MaxEngSpdCap MinEngSpdCap EngSpd MessageCounter_ENGINE_HYBD_FD_3 CRC_ENGINE_HYBD_FD_3;
SIG_GROUP_ 269 HYBRID_POWERTRAIN2_Pkt 1 : CRC_HYBRID_POWERTRAIN2 MessageCounter_HYBRID_POWERTRAI_10D;
SIG_GROUP_ 276 HYBRID_POWERTRAIN1_Pkt 1 : Hybrid_Remedial_Stop HybCrnkAbrted CRC_HYBRID_POWERTRAIN1 PropulsionSystemActive DriveReady MessageCounter_HYBRID_POWERTRAI_114;
SIG_GROUP_ 271 ENGINE_HYBD_FD_1_Pkt 1 : MessageCounter_ENGINE_HYBD_FD_1 CRC_ENGINE_HYBD_FD_1 RedSpkAuthorityAvbl EngMinSparkNomCurrAirTorqCap;
SIG_GROUP_ 262 ENGINE_FD_2_Pkt 1 : PowertrainPrplsnActv MessageCounter_ENGINE2 EngineSpeedFailSts_W EngineSpeed_W CRC_ENGINE2;
SIG_GROUP_ 1579 HYBRID_CHARGING_STATUS_Pkt 1 : HVBatteryVoltage_MinCal HVBatteryVoltage_MaxCal HVBatteryCurrent_MaxCal ChargeSystemFaultReason ACCurrent_MaxCal ChargingLevel OBCM_PLUG_STS ChargeSystemSts ChargeSystemFault CRC_HYBRID_CHARGING_STATUS MessageCounter_HYBRID_CHARGING__62B;
SIG_GROUP_ 478 HYBRID_CHARGING_COMMAND_Pkt 1 : CRC_HYBRID_CHARGING_COMMAND VoltageRequest OBC_ControlMethod J1772_CloseS2 HVBatCoolantLevelLow OBC_OperativeModeReq HV_Volt_Min_Thrsh HV_Volt_Max_Thrsh DC_Curr_Max_Thrsh ChargeEnable AC_Curr_Min_Thrsh AC_Curr_Max_Thrsh CurrentRequest VDCM_StsWldgReq VDCM_SessnStopReq VDCM_StsSWWldgReq MessageCounter_HYBRID_CHARGING__1DE;
SIG_GROUP_ 1578 HV_CHARGER2_Pkt 1 : OBC_IdleTimeSec OBC_IdleTimeMin OBC_ChargeTimeSec OBC_ChargeTimeMin Charging_WHr OnboardChargerReady OnboardChargerMode OBC_WakeReason OBC_GenericFailSts OBC_FaultReason OBC_EVServiceLampOn OBC_EVServiceLampFlash OBC_CurrentFailureSts OBC_ChargingFaultSts OBC_ChargeFailure OBC_CaptureEnvironmentData ACplug_PwrMax OBC_Prox OBC_Pilot OBCM_PrechargeSts ChrgFailSts;
SIG_GROUP_ 242 PIM_F_Pkt 1 : MC_PF1 INVFInterlockSts InvF_DC_Voltage CRC_PF1 InvF_DerateReason MCPA_Torque_Achieved MCPA_TorqAchieved_AEMD_V MCPA_TorqAchieved_AEMD MCPA_Spd_Lim MCPA_RPM_V MCPA_RPM MCPA_MtrMinCpbltyTrq MCPA_MtrMaxCpbltyTrq MCPA_MtrIndex MCPA_MinTorq MCPA_MaxTorq MCPA_Invrtr_State MCPA_HV_CnctrOpn_Req MCPA_Dschrge_Status MCPA_DeratingFactor MCPA_DC_Volt_V MCPA_DC_Current_V MCPA_DC_Current MCPA_CpbltySpdDivVolt MCPA_AccelRawV MCPA_AccelRaw MCPA_6SO_Status MCPA_3PS_Pos InvF_CoolantTemp MCPA_Torque_Achieved_V MCPA_SPT_Stat;
SIG_GROUP_ 498 OBCM_VDCM_Pkt 1 : HVCMS_EVSEPresentVoltage HVCMS_EVSEPeakCurrentRipple HVCMS_EVSEMinCurrentLimit HVCMS_EVSEMaxPowerLimit HVCMS_EVSEMaxCurrentLimit HVCMS_EVSECurrRegulationTol HVCMS_EnergyToBeDelivered EVSE_IsolationSts EVSE_Accepted_Protocol DC_TimeOut DC_Isolation_Disable_Cmd OBCM_PLCTypeSts HVCMS_EVSEVoltageLimitAchieved HVCMS_EVSEPowerLimitAchieved HVCMS_EVSEMinimumVoltageLimit HVCMS_EVSEMaximumVoltageLimit HVCMS_EVSECurrentLimitAchieved HVCMS_EVSEPresentCurrent EVSE_OfferedEnergyTransferType HVCMS_TxMessageStat HVCMS_ResponseCode HVCMS_EVSEProcessing EVSE_FreeService TxMessageResponse HVCMS_EVSEStatusCode EVSE_ServiceId EVSE_OfferedService EVSE_OfferedPaymentOptn MC_OBCM_VDCM EVSE_Supported_ISO1 EVSE_Supported_DIN CRC_OBCM_VDCM EVSE_Supported_SAE EVSE_Service2_Certificate EVSE_OfferedPaymentEIM EVSE_OfferedPaymentContract EVSE_Notification;
